VERSION ""

NS_ :

BS_:

BU_: VMCU TECU OBDScanT2 IC3 EMS ECUspare2 ECUspare1 DACU CIOM BBM

BO_ 2482973248 CIOM_BB2_05P: 8 CIOM
 SG_ FPBRChangeReq_ISig_4 : 52|2@1+ (1,0) [0|0] ""  VMCU
 SG_ HeadLampUpDown_SwitchStatus : 32|3@1+ (1,0) [0|0] ""  VMCU
 SG_ Recirc_ButtonStatus_ISig_4 : 18|2@1+ (1,0) [0|0] ""  IC3
 SG_ Auto_ButtonStatus_ISig_4 : 14|2@1+ (1,0) [0|0] ""  IC3
 SG_ AirFlowSelectionFrontBtn_stat_IS : 35|2@1+ (1,0) [0|0] ""  IC3
 SG_ InteriorLightMode_rqst_IL_Mode : 48|3@1+ (1,0) [0|0] ""  VMCU
 SG_ InteriorLightMode_rqst_EventFlag : 51|1@1+ (1,0) [0|0] ""  VMCU
 SG_ BlackOutConvoyModeSwitchStatus : 24|3@1+ (1,0) [0|0] ""  VMCU
 SG_ Indicator_Lights_Alarm_rqst_ISig : 27|3@1+ (1,0) [0|0] ""  VMCU
 SG_ AirFlowSelectionDownBtn_stat_ISi : 16|2@1+ (1,0) [0|0] ""  IC3
 SG_ ParkingHeater_IndicationCmd_ISig : 39|1@1+ (1,0) [0|0] ""  BBM
 SG_ AirFlowSelectionUpBtn_stat_ISig_ : 10|2@1+ (1,0) [0|0] ""  IC3
 SG_ ApproachLight_HMI_rqst : 44|2@1+ (1,0) [0|0] ""  VMCU
 SG_ Temperature_FreeWheelStatus_ISig : 20|4@1+ (1,0) [0|0] ""  IC3
 SG_ AirBlowerSpeed_FreeWheelStatus_I : 40|4@1+ (1,0) [0|0] ""  IC3
 SG_ CabInteriorTempVentilated_Stat_I : 0|10@1+ (0.125,-40) [-40|87.875] "DegreeC"  BBM
 SG_ ParkHeaterCooler_ButtonStatus_IS : 12|2@1+ (1,0) [0|0] ""  IC3
 SG_ WindscreenDefrost_ButtonStatus_I : 46|2@1+ (1,0) [0|0] ""  IC3
 SG_ AC_ButtonStatus_ISig_4 : 37|2@1+ (1,0) [0|0] ""  IC3

BO_ 2365532224 CIOM_BB2_04P: 8 CIOM
 SG_ BBContainerUnlockRequest : 50|2@1+ (1,0) [0|0] ""  VMCU
 SG_ CabPlowLight_rqst : 61|2@1+ (1,0) [0|0] ""  BBM
 SG_ AC_CompressorClutchCmd_ISig_4 : 58|2@1+ (1,0) [0|0] ""  EMS,VMCU
 SG_ AuxSwitchBbLoad4_Request : 44|2@1+ (1,0) [0|0] ""  VMCU
 SG_ FogLightRear_ButtonStatus_1 : 18|2@1+ (1,0) [0|0] ""  VMCU
 SG_ CabRoofSignOrVegaLight_rqst : 0|2@1+ (1,0) [0|0] ""  VMCU
 SG_ FogLightFront_ButtonStatus_2 : 4|2@1+ (1,0) [0|0] ""  VMCU
 SG_ AuxSwitchBbLoad1_Request : 30|2@1+ (1,0) [0|0] ""  VMCU
 SG_ BBCraneRequest : 52|2@1+ (1,0) [0|0] ""  VMCU
 SG_ AuxSwitchBbLoad6_Request : 48|2@1+ (1,0) [0|0] ""  VMCU
 SG_ AuxSwitchBbLoad5_Request : 46|2@1+ (1,0) [0|0] ""  VMCU
 SG_ BodyOrCabWorkingLight_rqst : 20|2@1+ (1,0) [0|0] ""  VMCU,BBM
 SG_ CabFrontSpot_rqst : 6|2@1+ (1,0) [0|0] ""  VMCU
 SG_ CabTrailerBodyLighting_rqst : 10|2@1+ (1,0) [0|0] ""  VMCU
 SG_ CabWorkingLightChassis_rqst : 2|2@1+ (1,0) [0|0] ""  VMCU
 SG_ BBTailLiftRequest : 56|2@1+ (1,0) [0|0] ""  VMCU
 SG_ BBSlidable5thWheelRequest : 54|2@1+ (1,0) [0|0] ""  VMCU
 SG_ ACmode_IndicationCmd_ISig_4 : 60|1@1+ (1,0) [0|0] ""  VMCU
 SG_ CabExtraSideWorkingLight_rqst : 24|3@1+ (1,0) [0|0] ""  VMCU
 SG_ FogLightFront_ButtonStatus_1 : 16|2@1+ (1,0) [0|0] ""  VMCU
 SG_ AuxSwitchBbLoad2_Request : 40|2@1+ (1,0) [0|0] ""  VMCU
 SG_ DRL_ButtonStatus : 14|2@1+ (1,0) [0|0] ""  VMCU
 SG_ CabRoofSpot_rqst : 12|2@1+ (1,0) [0|0] ""  VMCU
 SG_ LightMode_Status_Ctr_2 : 32|4@1+ (1,0) [0|0] ""  VMCU
 SG_ CabBeaconLight_rqst : 8|2@1+ (1,0) [0|0] ""  VMCU
 SG_ AuxSwitchBbLoad3_Request : 42|2@1+ (1,0) [0|0] ""  VMCU
 SG_ FogLightRear_ButtonStatus_2 : 22|2@1+ (1,0) [0|0] ""  VMCU
 SG_ LightMode_Status_Ctr_1 : 36|4@1+ (1,0) [0|0] ""  VMCU
 SG_ MirrorHeat_rqst : 27|3@1+ (1,0) [0|0] ""  IC3,VMCU

BO_ 2432643136 CIOM_BB2_03P: 8 CIOM
 SG_ LevelRequest_RollRequest_ISig_4 : 6|3@1+ (1,0) [0|0] ""  VMCU
 SG_ FerryFunctionSwitchChangeReq_ISi : 20|2@1+ (1,0) [0|0] ""  VMCU
 SG_ FerryFunctionRequest_ISig_4 : 34|2@1+ (1,0) [0|0] ""  VMCU
 SG_ LevelRequest_FrontAxle_ISig_4 : 0|3@1+ (1,0) [0|0] ""  VMCU
 SG_ KneelingChangeRequest_ISig_4 : 43|2@1+ (1,0) [0|0] ""  VMCU
 SG_ FerryFunctionRequest_UB_ISig_4 : 11|1@1+ (1,0) [0|0] ""  VMCU
 SG_ BunkH1AudioSrcSem_rqst_ISig_4 : 55|4@1+ (1,0) [0|0] ""  IC3
 SG_ ECSStandByRequest_ISig_4 : 40|3@1+ (1,0) [0|0] ""  VMCU
 SG_ LevelStrokeRequest_ISig_4 : 36|2@1+ (1,0) [0|0] ""  VMCU
 SG_ RideHeightStorageRequest_ISig_4 : 24|4@1+ (1,0) [0|0] ""  VMCU
 SG_ RampLevelRequest_ISig_4 : 12|4@1+ (1,0) [0|0] ""  VMCU
 SG_ TCP_KnobPostionStatus : 59|3@1+ (1,0) [0|0] ""  IC3
 SG_ SetFCWOperation : 48|3@1+ (1,0) [0|0] ""  DACU
 SG_ StopLevelChangeRequest_ISig_4 : 38|2@1+ (1,0) [0|0] ""  VMCU
 SG_ LevelRequest_sg_UB_ISig_4 : 22|1@1+ (1,0) [0|0] ""  VMCU
 SG_ RideHeightFunctionRequest_ISig_4 : 28|4@1+ (1,0) [0|0] ""  VMCU
 SG_ LevelRequest_RearAxle_ISig_4 : 3|3@1+ (1,0) [0|0] ""  VMCU
 SG_ RampLevelStorageRequest_ISig_4 : 16|4@1+ (1,0) [0|0] ""  VMCU
 SG_ SetCMOperation : 45|3@1+ (1,0) [0|0] ""  DACU,IC3,VMCU
 SG_ RideHeightFunctionRequest_UB_ISi : 23|1@1+ (1,0) [0|0] ""  VMCU
 SG_ BackToDriveReq_ISig_4 : 9|2@1+ (1,0) [0|0] ""  VMCU

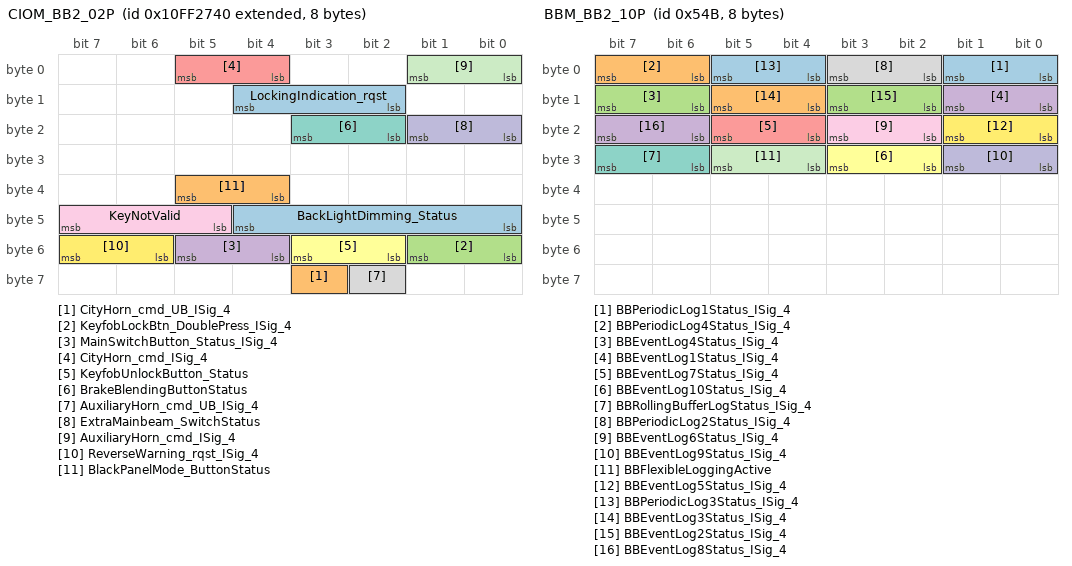
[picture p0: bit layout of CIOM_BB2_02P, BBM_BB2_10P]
BO_ 2432640832 CIOM_BB2_02P: 8 CIOM
 SG_ LockingIndication_rqst : 10|3@1+ (1,0) [0|0] ""  VMCU
 SG_ CityHorn_cmd_UB_ISig_4 : 59|1@1+ (1,0) [0|0] ""  BBM,VMCU
 SG_ KeyfobLockBtn_DoublePress_ISig_4 : 48|2@1+ (1,0) [0|0] ""  VMCU
 SG_ MainSwitchButton_Status_ISig_4 : 52|2@1+ (1,0) [0|0] ""  VMCU
 SG_ CityHorn_cmd_ISig_4 : 4|2@1+ (1,0) [0|0] ""  VMCU,BBM
 SG_ KeyfobUnlockButton_Status : 50|2@1+ (1,0) [0|0] ""  VMCU
 SG_ BrakeBlendingButtonStatus : 18|2@1+ (1,0) [0|0] ""  VMCU
 SG_ AuxiliaryHorn_cmd_UB_ISig_4 : 58|1@1+ (1,0) [0|0] ""  BBM,VMCU
 SG_ KeyNotValid : 45|3@1+ (1,0) [0|0] ""  IC3
 SG_ ExtraMainbeam_SwitchStatus : 16|2@1+ (1,0) [0|0] ""  VMCU
 SG_ AuxiliaryHorn_cmd_ISig_4 : 0|2@1+ (1,0) [0|0] ""  BBM,VMCU
 SG_ ReverseWarning_rqst_ISig_4 : 54|2@1+ (1,0) [0|0] ""  VMCU
 SG_ BackLightDimming_Status : 40|5@1+ (1,0) [0|0] ""  IC3
 SG_ BlackPanelMode_ButtonStatus : 36|2@1+ (1,0) [0|0] ""  IC3

BO_ 2432661312 CIOM_BB2_01P: 8 CIOM
 SG_ LiftAxle1LiftPositionRequest_UB_ : 3|1@1+ (1,0) [0|0] ""  VMCU
 SG_ VIN_rqst_ISig_4 : 36|1@1+ (1,0) [0|0] ""  EMS,TECU,IC3,VMCU
 SG_ FWSelectedSpeedControlMode : 24|3@1+ (1,0) [0|0] ""  IC3
 SG_ FogLightFront_ButtonStatus_3 : 42|2@1+ (1,0) [0|0] ""  VMCU
 SG_ InteriorLightDimming_rqst : 27|5@1+ (1,0) [0|0] ""  VMCU,IC3
 SG_ FrAxleDiffLockActvnDriverRqst_IS : 17|2@1+ (1,0) [0|0] ""  VMCU
 SG_ AdjustFrontBeamInclination : 32|3@1+ (1,0) [0|0] ""  VMCU
 SG_ LiftAxle2LiftPositionRequest_UB_ : 7|1@1+ (1,0) [0|0] ""  VMCU
 SG_ LiftAxle2AutoLiftRequest_ISig_4 : 11|2@1+ (1,0) [0|0] ""  VMCU
 SG_ LiftAxle2AutoLiftRequest_UB_ISig : 13|1@1+ (1,0) [0|0] ""  VMCU
 SG_ AltLoadDistribution_rqst_ISig_4 : 20|3@1+ (1,0) [0|0] ""  VMCU
 SG_ FogLightRear_ButtonStatus_3 : 44|2@1+ (1,0) [0|0] ""  VMCU
 SG_ LoadDistributionChangeRequest_UB : 16|1@1+ (1,0) [0|0] ""  VMCU
 SG_ LiftAxle2LiftPositionRequest_ISi : 4|3@1+ (1,0) [0|0] ""  VMCU
 SG_ AltLoadDistribution_rqst_UB_ISig : 23|1@1+ (1,0) [0|0] ""  VMCU
 SG_ TrailerBodyLamp_rqst : 49|2@1+ (1,0) [0|0] ""  VMCU
 SG_ LiftAxle1AutoLiftRequest_UB_ISig : 10|1@1+ (1,0) [0|0] ""  VMCU
 SG_ LoadDistributionChangeRequest_IS : 14|2@1+ (1,0) [0|0] ""  VMCU
 SG_ LiftAxle1AutoLiftRequest_ISig_4 : 8|2@1+ (1,0) [0|0] ""  VMCU
 SG_ LiftAxle1LiftPositionRequest_ISi : 0|3@1+ (1,0) [0|0] ""  VMCU
 SG_ FrAxleDiffLockActvnDriverRqst_UB : 19|1@1+ (1,0) [0|0] ""  VMCU,IC3

BO_ 1355 BBM_BB2_10P: 8 BBM
 SG_ BBPeriodicLog1Status_ISig_4 : 0|2@1+ (1,0) [0|0] ""  IC3
 SG_ BBPeriodicLog4Status_ISig_4 : 6|2@1+ (1,0) [0|0] ""  IC3
 SG_ BBEventLog4Status_ISig_4 : 14|2@1+ (1,0) [0|0] ""  IC3
 SG_ BBEventLog1Status_ISig_4 : 8|2@1+ (1,0) [0|0] ""  IC3
 SG_ BBEventLog7Status_ISig_4 : 20|2@1+ (1,0) [0|0] ""  IC3
 SG_ BBEventLog10Status_ISig_4 : 26|2@1+ (1,0) [0|0] ""  IC3
 SG_ BBRollingBufferLogStatus_ISig_4 : 30|2@1+ (1,0) [0|0] ""  IC3
 SG_ BBPeriodicLog2Status_ISig_4 : 2|2@1+ (1,0) [0|0] ""  IC3
 SG_ BBEventLog6Status_ISig_4 : 18|2@1+ (1,0) [0|0] ""  IC3
 SG_ BBEventLog9Status_ISig_4 : 24|2@1+ (1,0) [0|0] ""  IC3
 SG_ BBFlexibleLoggingActive : 28|2@1+ (1,0) [0|0] ""  IC3
 SG_ BBEventLog5Status_ISig_4 : 16|2@1+ (1,0) [0|0] ""  IC3
 SG_ BBPeriodicLog3Status_ISig_4 : 4|2@1+ (1,0) [0|0] ""  IC3
 SG_ BBEventLog3Status_ISig_4 : 12|2@1+ (1,0) [0|0] ""  IC3
 SG_ BBEventLog2Status_ISig_4 : 10|2@1+ (1,0) [0|0] ""  IC3
 SG_ BBEventLog8Status_ISig_4 : 22|2@1+ (1,0) [0|0] ""  IC3

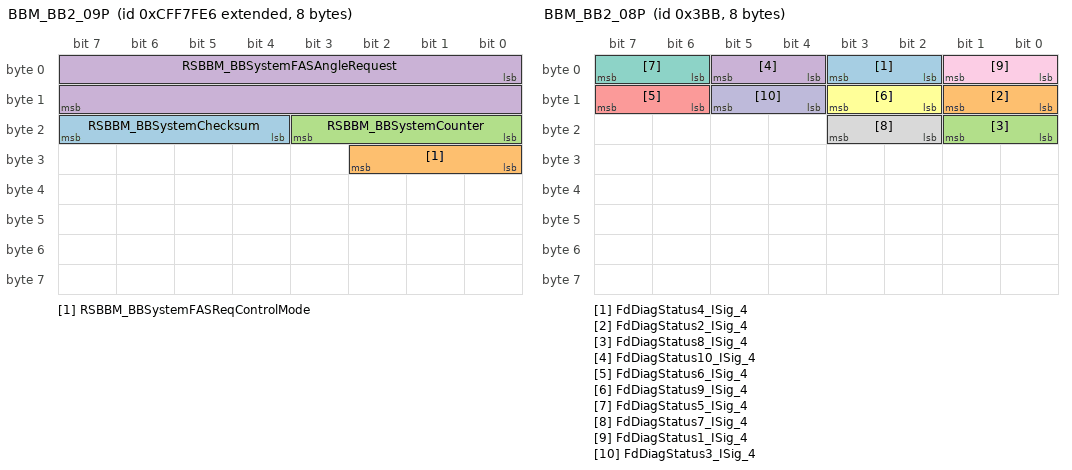
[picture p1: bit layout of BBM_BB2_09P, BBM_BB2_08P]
BO_ 2365554662 BBM_BB2_09P: 8 BBM
 SG_ RSBBM_BBSystemChecksum : 20|4@1+ (1,0) [0|15] "Count"  DACU
 SG_ RSBBM_BBSystemFASReqControlMode : 24|3@1+ (1,0) [0|0] ""  DACU
 SG_ RSBBM_BBSystemCounter : 16|4@1+ (1,0) [0|15] "Count"  DACU
 SG_ RSBBM_BBSystemFASAngleRequest : 0|16@1+ (5E-005,-1.6) [-1.6|1.67675] "rad"  DACU

BO_ 955 BBM_BB2_08P: 8 BBM
 SG_ FdDiagStatus4_ISig_4 : 2|2@1+ (1,0) [0|0] ""  IC3
 SG_ FdDiagStatus2_ISig_4 : 8|2@1+ (1,0) [0|0] ""  IC3
 SG_ FdDiagStatus8_ISig_4 : 16|2@1+ (1,0) [0|0] ""  IC3
 SG_ FdDiagStatus10_ISig_4 : 4|2@1+ (1,0) [0|0] ""  IC3
 SG_ FdDiagStatus6_ISig_4 : 14|2@1+ (1,0) [0|0] ""  IC3
 SG_ FdDiagStatus9_ISig_4 : 10|2@1+ (1,0) [0|0] ""  IC3
 SG_ FdDiagStatus5_ISig_4 : 6|2@1+ (1,0) [0|0] ""  IC3
 SG_ FdDiagStatus7_ISig_4 : 18|2@1+ (1,0) [0|0] ""  IC3
 SG_ FdDiagStatus1_ISig_4 : 0|2@1+ (1,0) [0|0] ""  IC3
 SG_ FdDiagStatus3_ISig_4 : 12|2@1+ (1,0) [0|0] ""  IC3

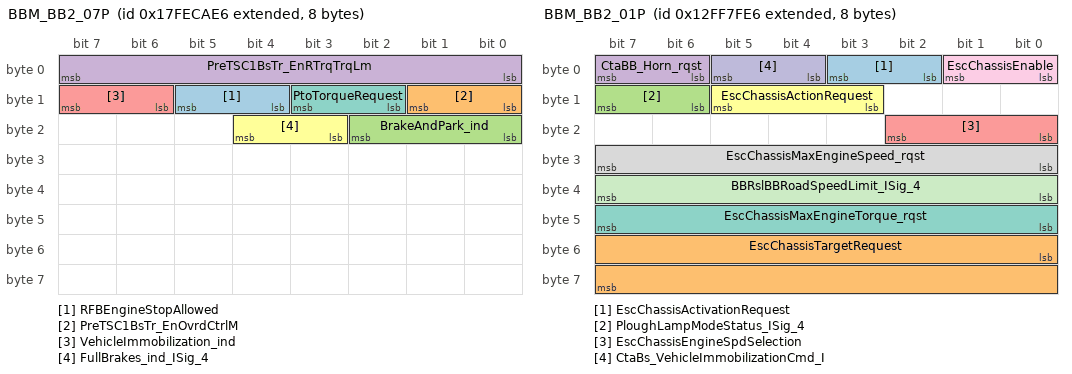
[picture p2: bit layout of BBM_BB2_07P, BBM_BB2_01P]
BO_ 2550057702 BBM_BB2_07P: 8 BBM
 SG_ RFBEngineStopAllowed : 12|2@1+ (1,0) [0|0] ""  VMCU
 SG_ PreTSC1BsTr_EnOvrdCtrlM : 8|2@1+ (1,0) [0|0] ""  VMCU
 SG_ BrakeAndPark_ind : 16|3@1+ (1,0) [0|0] ""  VMCU
 SG_ PreTSC1BsTr_EnRTrqTrqLm : 0|8@1+ (1,-125) [-125|130] "Percent"  VMCU
 SG_ VehicleImmobilization_ind : 14|2@1+ (1,0) [0|0] ""  VMCU
 SG_ FullBrakes_ind_ISig_4 : 19|2@1+ (1,0) [0|0] ""  IC3
 SG_ PtoTorqueRequest : 10|2@1+ (1,0) [0|0] ""  VMCU

BO_ 2481984998 BBM_BB2_06P: 8 BBM
 SG_ TipperConditionsStatus_ISig_4 : 14|2@1+ (1,0) [0|0] ""  CIOM
 SG_ TailLiftRemoteNotAllowed_ISig_4 : 30|2@1+ (1,0) [0|0] ""  CIOM
 SG_ TipperTarpaulinStatus_ISig_4 : 19|3@1+ (1,0) [0|0] ""  CIOM
 SG_ CTA_PBReleaseInhibit_rqst_UB : 39|1@1+ (1,0) [0|0] ""  VMCU
 SG_ TipperAutoLowering : 32|2@1+ (1,0) [0|0] ""  IC3
 SG_ DirInd_Plough_Status : 36|3@1+ (1,0) [0|0] ""  VMCU
 SG_ TipperShakerStatus_ISig_4 : 22|2@1+ (1,0) [0|0] ""  CIOM
 SG_ TipperEmergencyStopStatus_ISig_4 : 45|3@1+ (1,0) [0|0] ""  CIOM
 SG_ TipperSecondaryBodyStatus_ISig_4 : 51|3@1+ (1,0) [0|0] ""  CIOM
 SG_ TipperPrimaryBodyStatus_ISig_4 : 48|3@1+ (1,0) [0|0] ""  CIOM
 SG_ AuxSwitchBbLoad5Feedback : 8|3@1+ (1,0) [0|0] ""  VMCU
 SG_ AuxSwitchBbLoad3Feedback : 0|3@1+ (1,0) [0|0] ""  VMCU
 SG_ TailLiftMotionStatus_ISig_4 : 27|3@1+ (1,0) [0|0] ""  CIOM
 SG_ AuxSwitchBbLoad4Feedback : 3|3@1+ (1,0) [0|0] ""  VMCU
 SG_ TipperUpDownStatus_ISig_4 : 24|3@1+ (1,0) [0|0] ""  CIOM
 SG_ TailLiftConditionsStatus_ISig_4 : 6|2@1+ (1,0) [0|0] ""  CIOM
 SG_ AuxSwitchBbLoad6Feedback : 11|3@1+ (1,0) [0|0] ""  VMCU
 SG_ TipperTailGateStatus_ISig_4 : 16|3@1+ (1,0) [0|0] ""  CIOM
 SG_ CTA_PBReleaseInhibit_rqst : 43|2@1+ (1,0) [0|0] ""  VMCU

BO_ 2466201830 BBM_BB2_05P: 8 BBM
 SG_ BBUSecondDriverInterfEnable_UB_I : 29|1@1+ (1,0) [0|0] ""  VMCU
 SG_ CtaGcReverseInhibit : 6|2@1+ (1,0) [0|0] ""  TECU
 SG_ BBSystemAlternatLoadDistribReq_U : 28|1@1+ (1,0) [0|0] ""  VMCU
 SG_ BBSystemProhibitControlRequest_I : 4|2@1+ (1,0) [0|0] ""  VMCU
 SG_ BBUSecondDriverInterfEnable_ISig : 30|2@1+ (1,0) [0|0] ""  VMCU
 SG_ SecondDriverInterfEnableInput : 2|2@1+ (1,0) [0|0] ""  VMCU
 SG_ XPRRequest_RBS_ISig_4 : 40|8@1+ (1,0) [0|255] "NotApplicable"  VMCU
 SG_ CtaGcInhibitGearEngaged : 14|2@1+ (1,0) [0|0] ""  TECU
 SG_ EscChassisEngineSpdMode4 : 54|2@1+ (1,0) [0|0] ""  VMCU
 SG_ SecondAcceleratorPedalPosition : 32|8@1+ (0.4,0) [0|102] "Percent"  VMCU
 SG_ SecondaryAccelPedalQuality : 56|2@1+ (1,0) [0|0] ""  VMCU
 SG_ BBSystemKneelRequest_ISig_4 : 24|2@1+ (1,0) [0|0] ""  VMCU
 SG_ BBSystemAlternatLoadDistribReq_I : 0|2@1+ (1,0) [0|0] ""  VMCU
 SG_ EscChassisEngineSpdMode3 : 52|2@1+ (1,0) [0|0] ""  VMCU
 SG_ CtaGcSecondGearLeverPosition_ISi : 18|3@1+ (1,0) [0|0] ""  VMCU
 SG_ CtaGcAlternativeGearStarter : 16|2@1+ (1,0) [0|0] ""  TECU
 SG_ EscChassisEngineSpdMode2 : 50|2@1+ (1,0) [0|0] ""  VMCU
 SG_ SecondaryAccelPedalKickDown : 26|2@1+ (1,0) [0|0] ""  VMCU
 SG_ SecondAcceleratorPedalStatus : 10|2@1+ (1,0) [0|0] ""  VMCU
 SG_ GCRemoteEsc_rqst : 8|2@1+ (1,0) [0|0] ""  VMCU
 SG_ EscChassisEngineSpdMode1 : 48|2@1+ (1,0) [0|0] ""  VMCU
 SG_ BBSystemSpeedDepDriveLevelReq_IS : 12|2@1+ (1,0) [0|0] ""  VMCU

BO_ 2549377255 BBM_BB2_03S_HMIIOM_FCM: 8 IC3
 SG_ BBM_BB2_03S_FCS_4ea : 0|64@1+ (1,0) [0|1] ""  BBM

BO_ 2549377254 BBM_BB2_03S_HMIIOM: 128 BBM
 SG_ FdEquipmentFreeText_ISig_4_4e7 : 0|1024@1+ (1,0) [0|0] ""  IC3

BO_ 2549377511 BBM_BB2_03S_CIOM_FCM: 8 CIOM
 SG_ BBM_BB2_03S_FCS_4f0 : 0|64@1+ (1,0) [0|1] ""  BBM

BO_ 2549377510 BBM_BB2_03S_CIOM: 128 BBM
 SG_ FdEquipmentFreeText_ISig_4_4ed : 0|1024@1+ (1,0) [0|0] ""  CIOM

BO_ 2466239718 BBM_BB2_02P: 8 BBM
 SG_ RssRemoteStopEngine_rqst : 52|2@1+ (1,0) [0|0] ""  IC3,VMCU
 SG_ RSL2requestStatus : 56|2@1+ (1,0) [0|0] ""  VMCU
 SG_ FdEquipmentStatus2_ISig_4 : 6|2@1+ (1,0) [0|0] ""  IC3,CIOM
 SG_ RssRemoteStartEngine_rqst : 54|2@1+ (1,0) [0|0] ""  VMCU
 SG_ BBNetwBeaconLight_stat : 20|2@1+ (1,0) [0|0] ""  CIOM
 SG_ Pto2RemoteRequest : 18|2@1+ (1,0) [0|0] ""  VMCU
 SG_ FdEquipmentValue1_ISig_4 : 32|8@1+ (0.5,0) [0|127.5] "Percent"  CIOM,IC3
 SG_ Pto1RemoteRequest : 10|2@1+ (1,0) [0|0] ""  VMCU
 SG_ Pto3RemoteRequest : 16|2@1+ (1,0) [0|0] ""  VMCU
 SG_ FdEquipmentValue2_ISig_4 : 40|8@1+ (0.5,0) [0|127.5] "Percent"  IC3,CIOM
 SG_ BBHazardWarning_rqst : 0|2@1+ (1,0) [0|0] ""  VMCU
 SG_ FdEquipmentStatus5_ISig_4 : 4|2@1+ (1,0) [0|0] ""  CIOM,IC3
 SG_ RssInhibitStartEngFromBB_rqst : 58|2@1+ (1,0) [0|0] ""  VMCU
 SG_ BBNetwExtraSWrknLight_stat : 60|3@1+ (1,0) [0|0] ""  CIOM
 SG_ FdEquipmentStatus4_ISig_4 : 12|2@1+ (1,0) [0|0] ""  IC3,CIOM
 SG_ FdEquipmentStatus3_ISig_4 : 14|2@1+ (1,0) [0|0] ""  CIOM,IC3
 SG_ BBNetwWrknLightChassis_stat : 50|2@1+ (1,0) [0|0] ""  CIOM
 SG_ BBNetwBodyOrCabWrknLight_stat : 22|2@1+ (1,0) [0|0] ""  CIOM
 SG_ BBNetwTrailerBodyLighting_rqst : 48|2@1+ (1,0) [0|0] ""  CIOM
 SG_ Pto4RemoteRequest : 2|2@1+ (1,0) [0|0] ""  VMCU
 SG_ Pto3FeedbackStatus : 8|2@1+ (1,0) [0|0] ""  VMCU
 SG_ FdEquipmentValue3_ISig_4 : 24|8@1+ (0.5,0) [0|127.5] "Percent"  IC3,CIOM

BO_ 2466217958 BBM_BB2_01P: 8 BBM
 SG_ EscChassisActivationRequest : 2|2@1+ (1,0) [0|0] ""  VMCU
 SG_ EscChassisTargetRequest : 48|16@1+ (0.125,0) [0|8191.875] "rpm"  VMCU
 SG_ PloughLampModeStatus_ISig_4 : 14|2@1+ (1,0) [0|0] ""  CIOM,VMCU,IC3,DACU
 SG_ CtaBB_Horn_rqst : 6|2@1+ (1,0) [0|0] ""  CIOM
 SG_ EscChassisEngineSpdSelection : 16|3@1+ (1,0) [0|0] ""  VMCU
 SG_ EscChassisActionRequest : 11|3@1+ (1,0) [0|0] ""  VMCU
 SG_ EscChassisMaxEngineTorque_rqst : 40|8@1+ (1,-125) [-125|130] "Percent"  VMCU
 SG_ EscChassisMaxEngineSpeed_rqst : 24|8@1+ (10,500) [500|3050] "rpm"  VMCU
 SG_ EscChassisEnable : 0|2@1+ (1,0) [0|0] ""  VMCU
 SG_ CtaBs_VehicleImmobilizationCmd_I : 4|2@1+ (1,0) [0|0] ""  IC3
 SG_ BBRslBBRoadSpeedLimit_ISig_4 : 32|8@1+ (1,0) [0|255] "Km_per_h"  VMCU

BO_ 2633994247 AnmMsg_VMCU_Backbone2: 4 VMCU
 SG_ AnmSig_VMCU_Backbone2 : 0|32@1+ (1,0) [0|4294967295] ""  IC3,DACU,BBM,ECUspare2,EMS,CIOM,TECU,ECUspare1

BO_ 2633994246 AnmMsg_TECU_Backbone2: 4 TECU
 SG_ AnmSig_TECU_Backbone2 : 0|32@1+ (1,0) [0|4294967295] ""  VMCU,ECUspare2,IC3,ECUspare1,DACU,EMS,CIOM,BBM

BO_ 1715 AnmMsg_IC3_Backbone2: 4 IC3
 SG_ AnmSig_IC3_Backbone2 : 0|32@1+ (1,0) [0|4294967295] ""  ECUspare1,BBM,DACU,VMCU,TECU,EMS,CIOM,ECUspare2

BO_ 2633994243 AnmMsg_EMS_Backbone2: 4 EMS
 SG_ AnmSig_EMS_Backbone2 : 0|32@1+ (1,0) [0|4294967295] ""  ECUspare1,TECU,BBM,ECUspare2,CIOM,VMCU,DACU,IC3

BO_ 2633994310 AnmMsg_ECUspare2_Backbone2: 4 ECUspare2
 SG_ AnmSig_ECUspare2_Backbone2 : 0|32@1+ (1,0) [0|4294967295] ""  IC3,BBM,ECUspare1,CIOM,EMS,DACU,TECU,VMCU

BO_ 2633994309 AnmMsg_ECUspare1_Backbone2: 4 ECUspare1
 SG_ AnmSig_ECUspare1_Backbone2 : 0|32@1+ (1,0) [0|4294967295] ""  EMS,CIOM,TECU,VMCU,BBM,IC3,ECUspare2,DACU

BO_ 2633994242 AnmMsg_DACU_Backbone2: 4 DACU
 SG_ AnmSig_DACU_Backbone2 : 0|32@1+ (1,0) [0|4294967295] ""  ECUspare1,EMS,IC3,ECUspare2,CIOM,BBM,TECU,VMCU

BO_ 2633994241 AnmMsg_CIOM_Backbone2: 4 CIOM
 SG_ AnmSig_CIOM_Backbone2 : 0|32@1+ (1,0) [0|4294967295] ""  IC3,ECUspare1,VMCU,DACU,EMS,TECU,BBM,ECUspare2

BO_ 2633994240 AnmMsg_BBM_Backbone2: 4 BBM
 SG_ AnmSig_BBM_Backbone2 : 0|32@1+ (1,0) [0|4294967295] ""  EMS,VMCU,ECUspare2,DACU,CIOM,ECUspare1,TECU,IC3

CM_ SG_ 2482973248 CabInteriorTempVentilated_Stat_I "1022 Error; 1023 Not Available";
CM_ SG_ 2466201830 SecondAcceleratorPedalPosition "254 Error ; 255 Not available";
CM_ SG_ 2466239718 FdEquipmentValue1_ISig_4 "254 Error ; 255 Not available";
CM_ SG_ 2466239718 FdEquipmentValue2_ISig_4 "254 Error ; 255 Not available";
CM_ SG_ 2466239718 FdEquipmentValue3_ISig_4 "254 Error ; 255 Not available";
CM_ SG_ 2466217958 EscChassisTargetRequest "65024 - 65279 Error ; 65280 - 65535 Not available";
CM_ SG_ 2466217958 EscChassisMaxEngineTorque_rqst "254 Error ; 255 Not available";
CM_ SG_ 2466217958 EscChassisMaxEngineSpeed_rqst "254 Error ; 255 Not available";
CM_ SG_ 2466217958 BBRslBBRoadSpeedLimit_ISig_4 "254 Error ; 255 Not available";
BA_DEF_ BO_  "GenMsgStartDelayTime" INT 0 0;
BA_DEF_ BO_  "GenMsgDelayTime" INT 0 0;
BA_DEF_ BO_  "GenMsgCycleTime" INT 0 0;
BA_DEF_ BO_  "GenMsgSendType" ENUM  "Cyclic","NotUsed","NotUsed","NotUsed","NotUsed","NotUsed","NotUsed","IfActive","NoMsgSendType","NotUsed";
BA_DEF_ SG_  "GenSigStartValue" INT 0 0;
BA_DEF_ SG_  "GenSigCycleTimeActive" INT 0 0;
BA_DEF_ SG_  "GenSigCycleTime" INT 0 0;
BA_DEF_ SG_  "GenSigSendType" ENUM  "Cyclic","OnWrite","OnWriteWithRepetition","OnChange","OnChangeWithRepetition","IfActive","IfActiveWithRepetition","NoSigSendType","NotUsed","NotUsed","NotUsed","NotUsed","NotUsed";
BA_DEF_ BO_  "VFrameFormat" ENUM  "StandardCAN","ExtendedCAN","reserved","J1939PG";
BA_DEF_ SG_  "SigType" ENUM  "Default","Range","RangeSigned","ASCII","Discrete","Control","ReferencePGN","DTC","StringDelimiter","StringLength","StringLengthControl";
BA_DEF_ SG_  "SeToolVersion_SIGNAL" STRING ;
BA_DEF_ SG_  "SeToolUniqueID_SIGNAL" STRING ;
BA_DEF_ SG_  "SeToolOwnerSigGroup_SIGNAL" STRING ;
BA_DEF_ SG_  "SeToolOwnerSigGroupID_SIGNAL" STRING ;
BA_DEF_ SG_  "SeToolName_SIGNAL" STRING ;
BA_DEF_ SG_  "SeToolItemID_SIGNAL" STRING ;
BA_DEF_ SG_  "SeToolAncestorID_SIGNAL" STRING ;
BA_DEF_ SG_  "Platform_VMCU1_Sig" ENUM  "No","Yes";
BA_DEF_ BO_  "NmAsrMessage" ENUM  "No","Yes";
BA_DEF_ SG_  "NeedsUpdateBit" ENUM  "No","Yes";
BA_DEF_ SG_  "MmAnSignal" ENUM  "No","Yes";
BA_DEF_ SG_  "GenSigMaxLatency" INT 0 65535;
BA_DEF_ SG_  "GenSigILSupport" ENUM  "Yes","No";
BA_DEF_ BO_  "GenMsgRequestable" INT 0 1;
BA_DEF_ BO_  "GenMsgILSupport" ENUM  "No","Yes";
BA_DEF_ BO_  "DiagUUDTResponse" ENUM  "No","Yes";
BA_DEF_ BO_  "DiagState" ENUM  "No","Yes";
BA_DEF_ BO_  "DiagResponse" ENUM  "No","Yes";
BA_DEF_ BO_  "DiagRequest" ENUM  "No","Yes";
BA_DEF_ BO_  "DiagConnection" HEX 0 65535;
BA_DEF_ BO_  "CanTpSTmin" INT 0 255;
BA_DEF_ BO_  "CanTpFcFrameId" HEX 0 2147483647;
BA_DEF_ BO_  "CanTpBs" INT 0 255;
BA_DEF_ SG_  "SystemSignalLongSymbol" STRING ;
BA_DEF_REL_ BU_SG_REL_  "GenSigTimeoutTime" INT 0 65535;
BA_DEF_REL_ BU_SG_REL_  "GenSigFirstTimeoutTime" INT 0 65535;
BA_DEF_DEF_  "GenMsgStartDelayTime" 0;
BA_DEF_DEF_  "GenMsgDelayTime" 0;
BA_DEF_DEF_  "GenMsgCycleTime" 0;
BA_DEF_DEF_  "GenMsgSendType" "Cyclic";
BA_DEF_DEF_  "GenSigStartValue" 0;
BA_DEF_DEF_  "GenSigCycleTimeActive" 0;
BA_DEF_DEF_  "GenSigCycleTime" 0;
BA_DEF_DEF_  "GenSigSendType" "Cyclic";
BA_DEF_DEF_  "VFrameFormat" "ExtendedCAN";
BA_DEF_DEF_  "SigType" "Default";
BA_DEF_DEF_  "SeToolVersion_SIGNAL" "";
BA_DEF_DEF_  "SeToolUniqueID_SIGNAL" "";
BA_DEF_DEF_  "SeToolOwnerSigGroup_SIGNAL" "";
BA_DEF_DEF_  "SeToolOwnerSigGroupID_SIGNAL" "";
BA_DEF_DEF_  "SeToolName_SIGNAL" "";
BA_DEF_DEF_  "SeToolItemID_SIGNAL" "";
BA_DEF_DEF_  "SeToolAncestorID_SIGNAL" "";
BA_DEF_DEF_  "Platform_VMCU1_Sig" "No";
BA_DEF_DEF_  "NmAsrMessage" "No";
BA_DEF_DEF_  "NeedsUpdateBit" "No";
BA_DEF_DEF_  "MmAnSignal" "No";
BA_DEF_DEF_  "GenSigMaxLatency" 0;
BA_DEF_DEF_  "GenSigILSupport" "Yes";
BA_DEF_DEF_  "GenMsgRequestable" 1;
BA_DEF_DEF_  "GenMsgILSupport" "Yes";
BA_DEF_DEF_  "DiagUUDTResponse" "No";
BA_DEF_DEF_  "DiagState" "No";
BA_DEF_DEF_  "DiagResponse" "No";
BA_DEF_DEF_  "DiagRequest" "No";
BA_DEF_DEF_  "DiagConnection" 0;
BA_DEF_DEF_  "CanTpSTmin" 0;
BA_DEF_DEF_  "CanTpFcFrameId" 2147483647;
BA_DEF_DEF_  "CanTpBs" 255;
BA_DEF_DEF_REL_ "GenSigTimeoutTime" 0;
BA_DEF_DEF_REL_ "GenSigFirstTimeoutTime" 0;
BA_DEF_DEF_  "SystemSignalLongSymbol" "";
BA_ "GenMsgCycleTime" BO_ 2482973248 50;
BA_ "GenMsgStartDelayTime" BO_ 2482973248 20;
BA_ "GenMsgCycleTime" BO_ 2365532224 15;
BA_ "GenMsgCycleTime" BO_ 2432643136 20;
BA_ "GenMsgStartDelayTime" BO_ 2432643136 5;
BA_ "GenMsgCycleTime" BO_ 2432640832 20;
BA_ "GenMsgStartDelayTime" BO_ 2432640832 10;
BA_ "GenMsgCycleTime" BO_ 2432661312 20;
BA_ "VFrameFormat" BO_ 1355 0;
BA_ "GenMsgCycleTime" BO_ 1355 1000;
BA_ "GenMsgCycleTime" BO_ 2365554662 20;
BA_ "GenMsgStartDelayTime" BO_ 2365554662 10;
BA_ "VFrameFormat" BO_ 955 0;
BA_ "GenMsgCycleTime" BO_ 955 45;
BA_ "GenMsgStartDelayTime" BO_ 955 20;
BA_ "GenMsgCycleTime" BO_ 2550057702 250;
BA_ "GenMsgStartDelayTime" BO_ 2550057702 130;
BA_ "GenMsgCycleTime" BO_ 2481984998 50;
BA_ "GenMsgStartDelayTime" BO_ 2481984998 25;
BA_ "GenMsgCycleTime" BO_ 2466201830 30;
BA_ "GenMsgStartDelayTime" BO_ 2466201830 5;
BA_ "GenMsgILSupport" BO_ 2549377255 0;
BA_ "GenMsgSendType" BO_ 2549377255 8;
BA_ "CanTpFcFrameId" BO_ 2549377254 1258;
BA_ "GenMsgSendType" BO_ 2549377254 8;
BA_ "GenMsgDelayTime" BO_ 2549377254 90;
BA_ "GenMsgStartDelayTime" BO_ 2549377254 50;
BA_ "GenMsgILSupport" BO_ 2549377511 0;
BA_ "GenMsgSendType" BO_ 2549377511 8;
BA_ "CanTpFcFrameId" BO_ 2549377510 1264;
BA_ "GenMsgSendType" BO_ 2549377510 8;
BA_ "GenMsgDelayTime" BO_ 2549377510 90;
BA_ "GenMsgStartDelayTime" BO_ 2549377510 50;
BA_ "GenMsgCycleTime" BO_ 2466239718 45;
BA_ "GenMsgStartDelayTime" BO_ 2466239718 10;
BA_ "GenMsgCycleTime" BO_ 2466217958 45;
BA_ "GenMsgStartDelayTime" BO_ 2466217958 15;
BA_ "GenMsgCycleTime" BO_ 2633994247 100;
BA_ "GenMsgCycleTime" BO_ 2633994246 100;
BA_ "VFrameFormat" BO_ 1715 0;
BA_ "GenMsgCycleTime" BO_ 1715 100;
BA_ "GenMsgCycleTime" BO_ 2633994243 100;
BA_ "GenMsgCycleTime" BO_ 2633994310 100;
BA_ "GenMsgCycleTime" BO_ 2633994309 100;
BA_ "GenMsgCycleTime" BO_ 2633994242 100;
BA_ "GenMsgCycleTime" BO_ 2633994241 100;
BA_ "GenMsgCycleTime" BO_ 2633994240 100;
BA_ "GenSigCycleTime" SG_ 2482973248 FPBRChangeReq_ISig_4 100;
BA_ "GenSigCycleTimeActive" SG_ 2482973248 FPBRChangeReq_ISig_4 100;
BA_ "GenSigStartValue" SG_ 2482973248 FPBRChangeReq_ISig_4 3;
BA_ "Platform_VMCU1_Sig" SG_ 2482973248 FPBRChangeReq_ISig_4 1;
BA_ "GenSigCycleTime" SG_ 2482973248 HeadLampUpDown_SwitchStatus 100;
BA_ "GenSigCycleTimeActive" SG_ 2482973248 HeadLampUpDown_SwitchStatus 100;
BA_ "GenSigStartValue" SG_ 2482973248 HeadLampUpDown_SwitchStatus 7;
BA_ "GenSigMaxLatency" SG_ 2482973248 HeadLampUpDown_SwitchStatus 57;
BA_ "Platform_VMCU1_Sig" SG_ 2482973248 HeadLampUpDown_SwitchStatus 1;
BA_ "GenSigCycleTime" SG_ 2482973248 Recirc_ButtonStatus_ISig_4 100;
BA_ "GenSigCycleTimeActive" SG_ 2482973248 Recirc_ButtonStatus_ISig_4 100;
BA_ "GenSigStartValue" SG_ 2482973248 Recirc_ButtonStatus_ISig_4 3;
BA_ "GenSigMaxLatency" SG_ 2482973248 Recirc_ButtonStatus_ISig_4 57;
BA_ "Platform_VMCU1_Sig" SG_ 2482973248 Recirc_ButtonStatus_ISig_4 1;
BA_ "SeToolAncestorID_SIGNAL" SG_ 2482973248 Recirc_ButtonStatus_ISig_4 "x0000001D0423D932";
BA_ "SeToolItemID_SIGNAL" SG_ 2482973248 Recirc_ButtonStatus_ISig_4 "x0000001D0429669B";
BA_ "SeToolName_SIGNAL" SG_ 2482973248 Recirc_ButtonStatus_ISig_4 "Recirc_ButtonStatus";
BA_ "SeToolVersion_SIGNAL" SG_ 2482973248 Recirc_ButtonStatus_ISig_4 "4";
BA_ "GenSigCycleTime" SG_ 2482973248 Auto_ButtonStatus_ISig_4 100;
BA_ "GenSigCycleTimeActive" SG_ 2482973248 Auto_ButtonStatus_ISig_4 100;
BA_ "GenSigStartValue" SG_ 2482973248 Auto_ButtonStatus_ISig_4 3;
BA_ "GenSigMaxLatency" SG_ 2482973248 Auto_ButtonStatus_ISig_4 57;
BA_ "Platform_VMCU1_Sig" SG_ 2482973248 Auto_ButtonStatus_ISig_4 1;
BA_ "SeToolAncestorID_SIGNAL" SG_ 2482973248 Auto_ButtonStatus_ISig_4 "x0000001D0423D932";
BA_ "SeToolItemID_SIGNAL" SG_ 2482973248 Auto_ButtonStatus_ISig_4 "x0000001D0429669B";
BA_ "SeToolName_SIGNAL" SG_ 2482973248 Auto_ButtonStatus_ISig_4 "Auto_ButtonStatus";
BA_ "SeToolVersion_SIGNAL" SG_ 2482973248 Auto_ButtonStatus_ISig_4 "4";
BA_ "GenSigCycleTime" SG_ 2482973248 AirFlowSelectionFrontBtn_stat_IS 100;
BA_ "GenSigCycleTimeActive" SG_ 2482973248 AirFlowSelectionFrontBtn_stat_IS 100;
BA_ "GenSigStartValue" SG_ 2482973248 AirFlowSelectionFrontBtn_stat_IS 3;
BA_ "GenSigMaxLatency" SG_ 2482973248 AirFlowSelectionFrontBtn_stat_IS 57;
BA_ "Platform_VMCU1_Sig" SG_ 2482973248 AirFlowSelectionFrontBtn_stat_IS 1;
BA_ "SeToolAncestorID_SIGNAL" SG_ 2482973248 AirFlowSelectionFrontBtn_stat_IS "x0000001D0423D932";
BA_ "SeToolItemID_SIGNAL" SG_ 2482973248 AirFlowSelectionFrontBtn_stat_IS "x0000001D0429669B";
BA_ "SeToolName_SIGNAL" SG_ 2482973248 AirFlowSelectionFrontBtn_stat_IS "AirFlowSelectionFront_ButtonStatus";
BA_ "SeToolVersion_SIGNAL" SG_ 2482973248 AirFlowSelectionFrontBtn_stat_IS "4";
BA_ "SystemSignalLongSymbol" SG_ 2482973248 AirFlowSelectionFrontBtn_stat_IS "AirFlowSelectionFrontBtn_stat_ISig_4";
BA_ "GenSigCycleTime" SG_ 2482973248 InteriorLightMode_rqst_IL_Mode 100;
BA_ "GenSigCycleTimeActive" SG_ 2482973248 InteriorLightMode_rqst_IL_Mode 100;
BA_ "GenSigStartValue" SG_ 2482973248 InteriorLightMode_rqst_IL_Mode 7;
BA_ "Platform_VMCU1_Sig" SG_ 2482973248 InteriorLightMode_rqst_IL_Mode 1;
BA_ "GenSigCycleTime" SG_ 2482973248 InteriorLightMode_rqst_EventFlag 100;
BA_ "GenSigCycleTimeActive" SG_ 2482973248 InteriorLightMode_rqst_EventFlag 100;
BA_ "Platform_VMCU1_Sig" SG_ 2482973248 InteriorLightMode_rqst_EventFlag 1;
BA_ "GenSigCycleTime" SG_ 2482973248 BlackOutConvoyModeSwitchStatus 100;
BA_ "GenSigCycleTimeActive" SG_ 2482973248 BlackOutConvoyModeSwitchStatus 100;
BA_ "GenSigStartValue" SG_ 2482973248 BlackOutConvoyModeSwitchStatus 7;
BA_ "GenSigMaxLatency" SG_ 2482973248 BlackOutConvoyModeSwitchStatus 57;
BA_ "Platform_VMCU1_Sig" SG_ 2482973248 BlackOutConvoyModeSwitchStatus 1;
BA_ "GenSigCycleTime" SG_ 2482973248 Indicator_Lights_Alarm_rqst_ISig 100;
BA_ "GenSigCycleTimeActive" SG_ 2482973248 Indicator_Lights_Alarm_rqst_ISig 100;
BA_ "GenSigStartValue" SG_ 2482973248 Indicator_Lights_Alarm_rqst_ISig 7;
BA_ "GenSigMaxLatency" SG_ 2482973248 Indicator_Lights_Alarm_rqst_ISig 57;
BA_ "Platform_VMCU1_Sig" SG_ 2482973248 Indicator_Lights_Alarm_rqst_ISig 1;
BA_ "SystemSignalLongSymbol" SG_ 2482973248 Indicator_Lights_Alarm_rqst_ISig "Indicator_Lights_Alarm_rqst_ISig_4";
BA_ "GenSigCycleTime" SG_ 2482973248 AirFlowSelectionDownBtn_stat_ISi 100;
BA_ "GenSigCycleTimeActive" SG_ 2482973248 AirFlowSelectionDownBtn_stat_ISi 100;
BA_ "GenSigStartValue" SG_ 2482973248 AirFlowSelectionDownBtn_stat_ISi 3;
BA_ "GenSigMaxLatency" SG_ 2482973248 AirFlowSelectionDownBtn_stat_ISi 57;
BA_ "Platform_VMCU1_Sig" SG_ 2482973248 AirFlowSelectionDownBtn_stat_ISi 1;
BA_ "SeToolAncestorID_SIGNAL" SG_ 2482973248 AirFlowSelectionDownBtn_stat_ISi "x0000001D0423D932";
BA_ "SeToolItemID_SIGNAL" SG_ 2482973248 AirFlowSelectionDownBtn_stat_ISi "x0000001D0429669B";
BA_ "SeToolName_SIGNAL" SG_ 2482973248 AirFlowSelectionDownBtn_stat_ISi "AirFlowSelectionDown_ButtonStatus";
BA_ "SeToolVersion_SIGNAL" SG_ 2482973248 AirFlowSelectionDownBtn_stat_ISi "4";
BA_ "SystemSignalLongSymbol" SG_ 2482973248 AirFlowSelectionDownBtn_stat_ISi "AirFlowSelectionDownBtn_stat_ISig_4";
BA_ "GenSigCycleTime" SG_ 2482973248 ParkingHeater_IndicationCmd_ISig 100;
BA_ "GenSigCycleTimeActive" SG_ 2482973248 ParkingHeater_IndicationCmd_ISig 100;
BA_ "GenSigMaxLatency" SG_ 2482973248 ParkingHeater_IndicationCmd_ISig 57;
BA_ "Platform_VMCU1_Sig" SG_ 2482973248 ParkingHeater_IndicationCmd_ISig 1;
BA_ "SystemSignalLongSymbol" SG_ 2482973248 ParkingHeater_IndicationCmd_ISig "ParkingHeater_IndicationCmd_ISig_4";
BA_ "GenSigCycleTime" SG_ 2482973248 AirFlowSelectionUpBtn_stat_ISig_ 100;
BA_ "GenSigCycleTimeActive" SG_ 2482973248 AirFlowSelectionUpBtn_stat_ISig_ 100;
BA_ "GenSigStartValue" SG_ 2482973248 AirFlowSelectionUpBtn_stat_ISig_ 3;
BA_ "GenSigMaxLatency" SG_ 2482973248 AirFlowSelectionUpBtn_stat_ISig_ 57;
BA_ "Platform_VMCU1_Sig" SG_ 2482973248 AirFlowSelectionUpBtn_stat_ISig_ 1;
BA_ "SeToolAncestorID_SIGNAL" SG_ 2482973248 AirFlowSelectionUpBtn_stat_ISig_ "x0000001D0423D932";
BA_ "SeToolItemID_SIGNAL" SG_ 2482973248 AirFlowSelectionUpBtn_stat_ISig_ "x0000001D0429669B";
BA_ "SeToolName_SIGNAL" SG_ 2482973248 AirFlowSelectionUpBtn_stat_ISig_ "AirFlowSelectionUp_ButtonStatus";
BA_ "SeToolVersion_SIGNAL" SG_ 2482973248 AirFlowSelectionUpBtn_stat_ISig_ "4";
BA_ "SystemSignalLongSymbol" SG_ 2482973248 AirFlowSelectionUpBtn_stat_ISig_ "AirFlowSelectionUpBtn_stat_ISig_4";
BA_ "GenSigCycleTime" SG_ 2482973248 ApproachLight_HMI_rqst 100;
BA_ "GenSigCycleTimeActive" SG_ 2482973248 ApproachLight_HMI_rqst 100;
BA_ "GenSigStartValue" SG_ 2482973248 ApproachLight_HMI_rqst 3;
BA_ "GenSigMaxLatency" SG_ 2482973248 ApproachLight_HMI_rqst 57;
BA_ "Platform_VMCU1_Sig" SG_ 2482973248 ApproachLight_HMI_rqst 1;
BA_ "GenSigCycleTime" SG_ 2482973248 Temperature_FreeWheelStatus_ISig 100;
BA_ "GenSigCycleTimeActive" SG_ 2482973248 Temperature_FreeWheelStatus_ISig 100;
BA_ "GenSigStartValue" SG_ 2482973248 Temperature_FreeWheelStatus_ISig 15;
BA_ "GenSigMaxLatency" SG_ 2482973248 Temperature_FreeWheelStatus_ISig 57;
BA_ "Platform_VMCU1_Sig" SG_ 2482973248 Temperature_FreeWheelStatus_ISig 1;
BA_ "SeToolAncestorID_SIGNAL" SG_ 2482973248 Temperature_FreeWheelStatus_ISig "x0000001D0425F9AD";
BA_ "SeToolItemID_SIGNAL" SG_ 2482973248 Temperature_FreeWheelStatus_ISig "x0000001D043FC230";
BA_ "SeToolName_SIGNAL" SG_ 2482973248 Temperature_FreeWheelStatus_ISig "Temperature_FreeWheelStatus";
BA_ "SeToolVersion_SIGNAL" SG_ 2482973248 Temperature_FreeWheelStatus_ISig "3";
BA_ "SystemSignalLongSymbol" SG_ 2482973248 Temperature_FreeWheelStatus_ISig "Temperature_FreeWheelStatus_ISig_4";
BA_ "GenSigCycleTime" SG_ 2482973248 AirBlowerSpeed_FreeWheelStatus_I 100;
BA_ "GenSigCycleTimeActive" SG_ 2482973248 AirBlowerSpeed_FreeWheelStatus_I 100;
BA_ "GenSigStartValue" SG_ 2482973248 AirBlowerSpeed_FreeWheelStatus_I 15;
BA_ "GenSigMaxLatency" SG_ 2482973248 AirBlowerSpeed_FreeWheelStatus_I 57;
BA_ "Platform_VMCU1_Sig" SG_ 2482973248 AirBlowerSpeed_FreeWheelStatus_I 1;
BA_ "SeToolAncestorID_SIGNAL" SG_ 2482973248 AirBlowerSpeed_FreeWheelStatus_I "x0000001D0425F9AD";
BA_ "SeToolItemID_SIGNAL" SG_ 2482973248 AirBlowerSpeed_FreeWheelStatus_I "x0000001D043FC230";
BA_ "SeToolName_SIGNAL" SG_ 2482973248 AirBlowerSpeed_FreeWheelStatus_I "AirBlowerSpeed_FreeWheelStatus";
BA_ "SeToolVersion_SIGNAL" SG_ 2482973248 AirBlowerSpeed_FreeWheelStatus_I "3";
BA_ "SystemSignalLongSymbol" SG_ 2482973248 AirBlowerSpeed_FreeWheelStatus_I "AirBlowerSpeed_FreeWheelStatus_ISig_4";
BA_ "GenSigCycleTime" SG_ 2482973248 CabInteriorTempVentilated_Stat_I 100;
BA_ "GenSigCycleTimeActive" SG_ 2482973248 CabInteriorTempVentilated_Stat_I 100;
BA_ "GenSigStartValue" SG_ 2482973248 CabInteriorTempVentilated_Stat_I 1023;
BA_ "GenSigMaxLatency" SG_ 2482973248 CabInteriorTempVentilated_Stat_I 57;
BA_ "Platform_VMCU1_Sig" SG_ 2482973248 CabInteriorTempVentilated_Stat_I 1;
BA_ "SeToolAncestorID_SIGNAL" SG_ 2482973248 CabInteriorTempVentilated_Stat_I "x0000001D043C9954";
BA_ "SeToolItemID_SIGNAL" SG_ 2482973248 CabInteriorTempVentilated_Stat_I "x0000001D043C9954";
BA_ "SeToolName_SIGNAL" SG_ 2482973248 CabInteriorTempVentilated_Stat_I "CabInteriorTempVentilated_Stat";
BA_ "SeToolVersion_SIGNAL" SG_ 2482973248 CabInteriorTempVentilated_Stat_I "1";
BA_ "SystemSignalLongSymbol" SG_ 2482973248 CabInteriorTempVentilated_Stat_I "CabInteriorTempVentilated_Stat_ISig_4";
BA_ "GenSigCycleTime" SG_ 2482973248 ParkHeaterCooler_ButtonStatus_IS 100;
BA_ "GenSigCycleTimeActive" SG_ 2482973248 ParkHeaterCooler_ButtonStatus_IS 100;
BA_ "GenSigStartValue" SG_ 2482973248 ParkHeaterCooler_ButtonStatus_IS 3;
BA_ "GenSigMaxLatency" SG_ 2482973248 ParkHeaterCooler_ButtonStatus_IS 57;
BA_ "Platform_VMCU1_Sig" SG_ 2482973248 ParkHeaterCooler_ButtonStatus_IS 1;
BA_ "SystemSignalLongSymbol" SG_ 2482973248 ParkHeaterCooler_ButtonStatus_IS "ParkHeaterCooler_ButtonStatus_ISig_4";
BA_ "GenSigCycleTime" SG_ 2482973248 WindscreenDefrost_ButtonStatus_I 100;
BA_ "GenSigCycleTimeActive" SG_ 2482973248 WindscreenDefrost_ButtonStatus_I 100;
BA_ "GenSigStartValue" SG_ 2482973248 WindscreenDefrost_ButtonStatus_I 3;
BA_ "GenSigMaxLatency" SG_ 2482973248 WindscreenDefrost_ButtonStatus_I 57;
BA_ "Platform_VMCU1_Sig" SG_ 2482973248 WindscreenDefrost_ButtonStatus_I 1;
BA_ "SeToolAncestorID_SIGNAL" SG_ 2482973248 WindscreenDefrost_ButtonStatus_I "x0000001D0423D932";
BA_ "SeToolItemID_SIGNAL" SG_ 2482973248 WindscreenDefrost_ButtonStatus_I "x0000001D0429669B";
BA_ "SeToolName_SIGNAL" SG_ 2482973248 WindscreenDefrost_ButtonStatus_I "WindscreenDefroster_ButtonStatus";
BA_ "SeToolVersion_SIGNAL" SG_ 2482973248 WindscreenDefrost_ButtonStatus_I "4";
BA_ "SystemSignalLongSymbol" SG_ 2482973248 WindscreenDefrost_ButtonStatus_I "WindscreenDefrost_ButtonStatus_ISig_4";
BA_ "GenSigCycleTime" SG_ 2482973248 AC_ButtonStatus_ISig_4 100;
BA_ "GenSigCycleTimeActive" SG_ 2482973248 AC_ButtonStatus_ISig_4 100;
BA_ "GenSigStartValue" SG_ 2482973248 AC_ButtonStatus_ISig_4 3;
BA_ "GenSigMaxLatency" SG_ 2482973248 AC_ButtonStatus_ISig_4 57;
BA_ "Platform_VMCU1_Sig" SG_ 2482973248 AC_ButtonStatus_ISig_4 1;
BA_ "SeToolAncestorID_SIGNAL" SG_ 2482973248 AC_ButtonStatus_ISig_4 "x0000001D0423D932";
BA_ "SeToolItemID_SIGNAL" SG_ 2482973248 AC_ButtonStatus_ISig_4 "x0000001D0429669B";
BA_ "SeToolName_SIGNAL" SG_ 2482973248 AC_ButtonStatus_ISig_4 "AC_ButtonStatus";
BA_ "SeToolVersion_SIGNAL" SG_ 2482973248 AC_ButtonStatus_ISig_4 "4";
BA_ "GenSigCycleTime" SG_ 2365532224 BBContainerUnlockRequest 100;
BA_ "GenSigCycleTimeActive" SG_ 2365532224 BBContainerUnlockRequest 100;
BA_ "GenSigStartValue" SG_ 2365532224 BBContainerUnlockRequest 3;
BA_ "Platform_VMCU1_Sig" SG_ 2365532224 BBContainerUnlockRequest 1;
BA_ "GenSigCycleTime" SG_ 2365532224 CabPlowLight_rqst 100;
BA_ "GenSigCycleTimeActive" SG_ 2365532224 CabPlowLight_rqst 100;
BA_ "GenSigStartValue" SG_ 2365532224 CabPlowLight_rqst 3;
BA_ "Platform_VMCU1_Sig" SG_ 2365532224 CabPlowLight_rqst 1;
BA_ "GenSigCycleTime" SG_ 2365532224 AC_CompressorClutchCmd_ISig_4 100;
BA_ "GenSigCycleTimeActive" SG_ 2365532224 AC_CompressorClutchCmd_ISig_4 100;
BA_ "GenSigStartValue" SG_ 2365532224 AC_CompressorClutchCmd_ISig_4 3;
BA_ "Platform_VMCU1_Sig" SG_ 2365532224 AC_CompressorClutchCmd_ISig_4 1;
BA_ "GenSigCycleTime" SG_ 2365532224 AuxSwitchBbLoad4_Request 100;
BA_ "GenSigCycleTimeActive" SG_ 2365532224 AuxSwitchBbLoad4_Request 100;
BA_ "GenSigStartValue" SG_ 2365532224 AuxSwitchBbLoad4_Request 3;
BA_ "Platform_VMCU1_Sig" SG_ 2365532224 AuxSwitchBbLoad4_Request 1;
BA_ "GenSigCycleTime" SG_ 2365532224 FogLightRear_ButtonStatus_1 100;
BA_ "GenSigCycleTimeActive" SG_ 2365532224 FogLightRear_ButtonStatus_1 100;
BA_ "GenSigStartValue" SG_ 2365532224 FogLightRear_ButtonStatus_1 3;
BA_ "GenSigMaxLatency" SG_ 2365532224 FogLightRear_ButtonStatus_1 29;
BA_ "Platform_VMCU1_Sig" SG_ 2365532224 FogLightRear_ButtonStatus_1 1;
BA_ "SeToolAncestorID_SIGNAL" SG_ 2365532224 FogLightRear_ButtonStatus_1 "x0000001D0423D932";
BA_ "SeToolItemID_SIGNAL" SG_ 2365532224 FogLightRear_ButtonStatus_1 "x0000001D0429669B";
BA_ "SeToolName_SIGNAL" SG_ 2365532224 FogLightRear_ButtonStatus_1 "FogLightRear_ButtonStatus_1";
BA_ "SeToolVersion_SIGNAL" SG_ 2365532224 FogLightRear_ButtonStatus_1 "4";
BA_ "GenSigCycleTime" SG_ 2365532224 CabRoofSignOrVegaLight_rqst 100;
BA_ "GenSigCycleTimeActive" SG_ 2365532224 CabRoofSignOrVegaLight_rqst 100;
BA_ "GenSigStartValue" SG_ 2365532224 CabRoofSignOrVegaLight_rqst 3;
BA_ "GenSigMaxLatency" SG_ 2365532224 CabRoofSignOrVegaLight_rqst 29;
BA_ "Platform_VMCU1_Sig" SG_ 2365532224 CabRoofSignOrVegaLight_rqst 1;
BA_ "SeToolAncestorID_SIGNAL" SG_ 2365532224 CabRoofSignOrVegaLight_rqst "x0000001D041A6CF7";
BA_ "SeToolItemID_SIGNAL" SG_ 2365532224 CabRoofSignOrVegaLight_rqst "x0000001D041A6CF7";
BA_ "SeToolName_SIGNAL" SG_ 2365532224 CabRoofSignOrVegaLight_rqst "CabRoofSignLight_rqst";
BA_ "SeToolVersion_SIGNAL" SG_ 2365532224 CabRoofSignOrVegaLight_rqst "1";
BA_ "GenSigCycleTime" SG_ 2365532224 FogLightFront_ButtonStatus_2 100;
BA_ "GenSigCycleTimeActive" SG_ 2365532224 FogLightFront_ButtonStatus_2 100;
BA_ "GenSigStartValue" SG_ 2365532224 FogLightFront_ButtonStatus_2 3;
BA_ "GenSigMaxLatency" SG_ 2365532224 FogLightFront_ButtonStatus_2 29;
BA_ "Platform_VMCU1_Sig" SG_ 2365532224 FogLightFront_ButtonStatus_2 1;
BA_ "SeToolAncestorID_SIGNAL" SG_ 2365532224 FogLightFront_ButtonStatus_2 "x0000001D0423D932";
BA_ "SeToolItemID_SIGNAL" SG_ 2365532224 FogLightFront_ButtonStatus_2 "x0000001D0429669B";
BA_ "SeToolName_SIGNAL" SG_ 2365532224 FogLightFront_ButtonStatus_2 "FogLightFront_ButtonStatus_2";
BA_ "SeToolVersion_SIGNAL" SG_ 2365532224 FogLightFront_ButtonStatus_2 "4";
BA_ "GenSigCycleTime" SG_ 2365532224 AuxSwitchBbLoad1_Request 100;
BA_ "GenSigCycleTimeActive" SG_ 2365532224 AuxSwitchBbLoad1_Request 100;
BA_ "GenSigStartValue" SG_ 2365532224 AuxSwitchBbLoad1_Request 3;
BA_ "Platform_VMCU1_Sig" SG_ 2365532224 AuxSwitchBbLoad1_Request 1;
BA_ "GenSigCycleTime" SG_ 2365532224 BBCraneRequest 100;
BA_ "GenSigCycleTimeActive" SG_ 2365532224 BBCraneRequest 100;
BA_ "GenSigStartValue" SG_ 2365532224 BBCraneRequest 3;
BA_ "Platform_VMCU1_Sig" SG_ 2365532224 BBCraneRequest 1;
BA_ "GenSigCycleTime" SG_ 2365532224 AuxSwitchBbLoad6_Request 100;
BA_ "GenSigCycleTimeActive" SG_ 2365532224 AuxSwitchBbLoad6_Request 100;
BA_ "GenSigStartValue" SG_ 2365532224 AuxSwitchBbLoad6_Request 3;
BA_ "Platform_VMCU1_Sig" SG_ 2365532224 AuxSwitchBbLoad6_Request 1;
BA_ "GenSigCycleTime" SG_ 2365532224 AuxSwitchBbLoad5_Request 100;
BA_ "GenSigCycleTimeActive" SG_ 2365532224 AuxSwitchBbLoad5_Request 100;
BA_ "GenSigStartValue" SG_ 2365532224 AuxSwitchBbLoad5_Request 3;
BA_ "Platform_VMCU1_Sig" SG_ 2365532224 AuxSwitchBbLoad5_Request 1;
BA_ "GenSigCycleTime" SG_ 2365532224 BodyOrCabWorkingLight_rqst 100;
BA_ "GenSigCycleTimeActive" SG_ 2365532224 BodyOrCabWorkingLight_rqst 100;
BA_ "GenSigStartValue" SG_ 2365532224 BodyOrCabWorkingLight_rqst 3;
BA_ "GenSigMaxLatency" SG_ 2365532224 BodyOrCabWorkingLight_rqst 29;
BA_ "Platform_VMCU1_Sig" SG_ 2365532224 BodyOrCabWorkingLight_rqst 1;
BA_ "SeToolAncestorID_SIGNAL" SG_ 2365532224 BodyOrCabWorkingLight_rqst "x0000001D041A6CF9";
BA_ "SeToolItemID_SIGNAL" SG_ 2365532224 BodyOrCabWorkingLight_rqst "x0000001D041A6CF9";
BA_ "SeToolName_SIGNAL" SG_ 2365532224 BodyOrCabWorkingLight_rqst "CabBody/CabWorkingLight_rqst";
BA_ "SeToolVersion_SIGNAL" SG_ 2365532224 BodyOrCabWorkingLight_rqst "1";
BA_ "GenSigCycleTime" SG_ 2365532224 CabFrontSpot_rqst 100;
BA_ "GenSigCycleTimeActive" SG_ 2365532224 CabFrontSpot_rqst 100;
BA_ "GenSigStartValue" SG_ 2365532224 CabFrontSpot_rqst 3;
BA_ "GenSigMaxLatency" SG_ 2365532224 CabFrontSpot_rqst 29;
BA_ "Platform_VMCU1_Sig" SG_ 2365532224 CabFrontSpot_rqst 1;
BA_ "SeToolAncestorID_SIGNAL" SG_ 2365532224 CabFrontSpot_rqst "x0000001D041A6CF5";
BA_ "SeToolItemID_SIGNAL" SG_ 2365532224 CabFrontSpot_rqst "x0000001D041A6CF5";
BA_ "SeToolName_SIGNAL" SG_ 2365532224 CabFrontSpot_rqst "CabFrontSpot_rqst";
BA_ "SeToolVersion_SIGNAL" SG_ 2365532224 CabFrontSpot_rqst "1";
BA_ "GenSigCycleTime" SG_ 2365532224 CabTrailerBodyLighting_rqst 100;
BA_ "GenSigCycleTimeActive" SG_ 2365532224 CabTrailerBodyLighting_rqst 100;
BA_ "GenSigStartValue" SG_ 2365532224 CabTrailerBodyLighting_rqst 3;
BA_ "GenSigMaxLatency" SG_ 2365532224 CabTrailerBodyLighting_rqst 29;
BA_ "Platform_VMCU1_Sig" SG_ 2365532224 CabTrailerBodyLighting_rqst 1;
BA_ "SeToolAncestorID_SIGNAL" SG_ 2365532224 CabTrailerBodyLighting_rqst "x0000001D04206C33";
BA_ "SeToolItemID_SIGNAL" SG_ 2365532224 CabTrailerBodyLighting_rqst "x0000001D042FD0E8";
BA_ "SeToolName_SIGNAL" SG_ 2365532224 CabTrailerBodyLighting_rqst "CabTrailerBodyLighting_rqst";
BA_ "SeToolVersion_SIGNAL" SG_ 2365532224 CabTrailerBodyLighting_rqst "2";
BA_ "GenSigCycleTime" SG_ 2365532224 CabWorkingLightChassis_rqst 100;
BA_ "GenSigCycleTimeActive" SG_ 2365532224 CabWorkingLightChassis_rqst 100;
BA_ "GenSigStartValue" SG_ 2365532224 CabWorkingLightChassis_rqst 3;
BA_ "GenSigMaxLatency" SG_ 2365532224 CabWorkingLightChassis_rqst 29;
BA_ "Platform_VMCU1_Sig" SG_ 2365532224 CabWorkingLightChassis_rqst 1;
BA_ "SeToolAncestorID_SIGNAL" SG_ 2365532224 CabWorkingLightChassis_rqst "x0000001D041A6D07";
BA_ "SeToolItemID_SIGNAL" SG_ 2365532224 CabWorkingLightChassis_rqst "x0000001D041A6D07";
BA_ "SeToolName_SIGNAL" SG_ 2365532224 CabWorkingLightChassis_rqst "CabWorkingLightChassis_rqst";
BA_ "SeToolVersion_SIGNAL" SG_ 2365532224 CabWorkingLightChassis_rqst "1";
BA_ "GenSigCycleTime" SG_ 2365532224 BBTailLiftRequest 100;
BA_ "GenSigCycleTimeActive" SG_ 2365532224 BBTailLiftRequest 100;
BA_ "GenSigStartValue" SG_ 2365532224 BBTailLiftRequest 3;
BA_ "Platform_VMCU1_Sig" SG_ 2365532224 BBTailLiftRequest 1;
BA_ "GenSigCycleTime" SG_ 2365532224 BBSlidable5thWheelRequest 100;
BA_ "GenSigCycleTimeActive" SG_ 2365532224 BBSlidable5thWheelRequest 100;
BA_ "GenSigStartValue" SG_ 2365532224 BBSlidable5thWheelRequest 3;
BA_ "Platform_VMCU1_Sig" SG_ 2365532224 BBSlidable5thWheelRequest 1;
BA_ "GenSigCycleTime" SG_ 2365532224 ACmode_IndicationCmd_ISig_4 100;
BA_ "GenSigCycleTimeActive" SG_ 2365532224 ACmode_IndicationCmd_ISig_4 100;
BA_ "Platform_VMCU1_Sig" SG_ 2365532224 ACmode_IndicationCmd_ISig_4 1;
BA_ "SeToolAncestorID_SIGNAL" SG_ 2365532224 ACmode_IndicationCmd_ISig_4 "x0000001D04405ABB";
BA_ "SeToolItemID_SIGNAL" SG_ 2365532224 ACmode_IndicationCmd_ISig_4 "x0000001D04405ABB";
BA_ "SeToolName_SIGNAL" SG_ 2365532224 ACmode_IndicationCmd_ISig_4 "ACmode_IndicationCmd";
BA_ "SeToolVersion_SIGNAL" SG_ 2365532224 ACmode_IndicationCmd_ISig_4 "1";
BA_ "GenSigCycleTime" SG_ 2365532224 CabExtraSideWorkingLight_rqst 100;
BA_ "GenSigCycleTimeActive" SG_ 2365532224 CabExtraSideWorkingLight_rqst 100;
BA_ "GenSigStartValue" SG_ 2365532224 CabExtraSideWorkingLight_rqst 7;
BA_ "GenSigMaxLatency" SG_ 2365532224 CabExtraSideWorkingLight_rqst 29;
BA_ "Platform_VMCU1_Sig" SG_ 2365532224 CabExtraSideWorkingLight_rqst 1;
BA_ "SeToolAncestorID_SIGNAL" SG_ 2365532224 CabExtraSideWorkingLight_rqst "x0000001D041AF5F5";
BA_ "SeToolItemID_SIGNAL" SG_ 2365532224 CabExtraSideWorkingLight_rqst "x0000001D041AF5F5";
BA_ "SeToolName_SIGNAL" SG_ 2365532224 CabExtraSideWorkingLight_rqst "CabExtraSideWorkingLight_rqst";
BA_ "SeToolVersion_SIGNAL" SG_ 2365532224 CabExtraSideWorkingLight_rqst "1";
BA_ "GenSigCycleTime" SG_ 2365532224 FogLightFront_ButtonStatus_1 100;
BA_ "GenSigCycleTimeActive" SG_ 2365532224 FogLightFront_ButtonStatus_1 100;
BA_ "GenSigStartValue" SG_ 2365532224 FogLightFront_ButtonStatus_1 3;
BA_ "GenSigMaxLatency" SG_ 2365532224 FogLightFront_ButtonStatus_1 29;
BA_ "Platform_VMCU1_Sig" SG_ 2365532224 FogLightFront_ButtonStatus_1 1;
BA_ "SeToolAncestorID_SIGNAL" SG_ 2365532224 FogLightFront_ButtonStatus_1 "x0000001D0423D932";
BA_ "SeToolItemID_SIGNAL" SG_ 2365532224 FogLightFront_ButtonStatus_1 "x0000001D0429669B";
BA_ "SeToolName_SIGNAL" SG_ 2365532224 FogLightFront_ButtonStatus_1 "FogLightFront_ButtonStatus_1";
BA_ "SeToolVersion_SIGNAL" SG_ 2365532224 FogLightFront_ButtonStatus_1 "4";
BA_ "GenSigCycleTime" SG_ 2365532224 AuxSwitchBbLoad2_Request 100;
BA_ "GenSigCycleTimeActive" SG_ 2365532224 AuxSwitchBbLoad2_Request 100;
BA_ "GenSigStartValue" SG_ 2365532224 AuxSwitchBbLoad2_Request 3;
BA_ "Platform_VMCU1_Sig" SG_ 2365532224 AuxSwitchBbLoad2_Request 1;
BA_ "GenSigCycleTime" SG_ 2365532224 DRL_ButtonStatus 100;
BA_ "GenSigCycleTimeActive" SG_ 2365532224 DRL_ButtonStatus 100;
BA_ "GenSigStartValue" SG_ 2365532224 DRL_ButtonStatus 3;
BA_ "GenSigMaxLatency" SG_ 2365532224 DRL_ButtonStatus 29;
BA_ "Platform_VMCU1_Sig" SG_ 2365532224 DRL_ButtonStatus 1;
BA_ "SeToolAncestorID_SIGNAL" SG_ 2365532224 DRL_ButtonStatus "x0000001D0423D932";
BA_ "SeToolItemID_SIGNAL" SG_ 2365532224 DRL_ButtonStatus "x0000001D0429669B";
BA_ "SeToolName_SIGNAL" SG_ 2365532224 DRL_ButtonStatus "DRL_ButtonStatus";
BA_ "SeToolVersion_SIGNAL" SG_ 2365532224 DRL_ButtonStatus "4";
BA_ "GenSigCycleTime" SG_ 2365532224 CabRoofSpot_rqst 100;
BA_ "GenSigCycleTimeActive" SG_ 2365532224 CabRoofSpot_rqst 100;
BA_ "GenSigStartValue" SG_ 2365532224 CabRoofSpot_rqst 3;
BA_ "GenSigMaxLatency" SG_ 2365532224 CabRoofSpot_rqst 29;
BA_ "Platform_VMCU1_Sig" SG_ 2365532224 CabRoofSpot_rqst 1;
BA_ "SeToolAncestorID_SIGNAL" SG_ 2365532224 CabRoofSpot_rqst "x0000001D041A6CF3";
BA_ "SeToolItemID_SIGNAL" SG_ 2365532224 CabRoofSpot_rqst "x0000001D041A6CF3";
BA_ "SeToolName_SIGNAL" SG_ 2365532224 CabRoofSpot_rqst "CabRoofSpot_rqst";
BA_ "SeToolVersion_SIGNAL" SG_ 2365532224 CabRoofSpot_rqst "1";
BA_ "GenSigCycleTime" SG_ 2365532224 LightMode_Status_Ctr_2 100;
BA_ "GenSigCycleTimeActive" SG_ 2365532224 LightMode_Status_Ctr_2 100;
BA_ "GenSigStartValue" SG_ 2365532224 LightMode_Status_Ctr_2 15;
BA_ "Platform_VMCU1_Sig" SG_ 2365532224 LightMode_Status_Ctr_2 1;
BA_ "GenSigCycleTime" SG_ 2365532224 CabBeaconLight_rqst 100;
BA_ "GenSigCycleTimeActive" SG_ 2365532224 CabBeaconLight_rqst 100;
BA_ "GenSigStartValue" SG_ 2365532224 CabBeaconLight_rqst 3;
BA_ "GenSigMaxLatency" SG_ 2365532224 CabBeaconLight_rqst 29;
BA_ "Platform_VMCU1_Sig" SG_ 2365532224 CabBeaconLight_rqst 1;
BA_ "SeToolAncestorID_SIGNAL" SG_ 2365532224 CabBeaconLight_rqst "x0000001D041A6CF1";
BA_ "SeToolItemID_SIGNAL" SG_ 2365532224 CabBeaconLight_rqst "x0000001D041A6CF1";
BA_ "SeToolName_SIGNAL" SG_ 2365532224 CabBeaconLight_rqst "CabBeaconLight_rqst";
BA_ "SeToolVersion_SIGNAL" SG_ 2365532224 CabBeaconLight_rqst "1";
BA_ "GenSigCycleTime" SG_ 2365532224 AuxSwitchBbLoad3_Request 100;
BA_ "GenSigCycleTimeActive" SG_ 2365532224 AuxSwitchBbLoad3_Request 100;
BA_ "GenSigStartValue" SG_ 2365532224 AuxSwitchBbLoad3_Request 3;
BA_ "Platform_VMCU1_Sig" SG_ 2365532224 AuxSwitchBbLoad3_Request 1;
BA_ "GenSigCycleTime" SG_ 2365532224 FogLightRear_ButtonStatus_2 100;
BA_ "GenSigCycleTimeActive" SG_ 2365532224 FogLightRear_ButtonStatus_2 100;
BA_ "GenSigStartValue" SG_ 2365532224 FogLightRear_ButtonStatus_2 3;
BA_ "GenSigMaxLatency" SG_ 2365532224 FogLightRear_ButtonStatus_2 29;
BA_ "Platform_VMCU1_Sig" SG_ 2365532224 FogLightRear_ButtonStatus_2 1;
BA_ "SeToolAncestorID_SIGNAL" SG_ 2365532224 FogLightRear_ButtonStatus_2 "x0000001D0423D932";
BA_ "SeToolItemID_SIGNAL" SG_ 2365532224 FogLightRear_ButtonStatus_2 "x0000001D0429669B";
BA_ "SeToolName_SIGNAL" SG_ 2365532224 FogLightRear_ButtonStatus_2 "FogLightRear_ButtonStatus_2";
BA_ "SeToolVersion_SIGNAL" SG_ 2365532224 FogLightRear_ButtonStatus_2 "4";
BA_ "GenSigCycleTime" SG_ 2365532224 LightMode_Status_Ctr_1 100;
BA_ "GenSigCycleTimeActive" SG_ 2365532224 LightMode_Status_Ctr_1 100;
BA_ "GenSigStartValue" SG_ 2365532224 LightMode_Status_Ctr_1 15;
BA_ "Platform_VMCU1_Sig" SG_ 2365532224 LightMode_Status_Ctr_1 1;
BA_ "GenSigCycleTime" SG_ 2365532224 MirrorHeat_rqst 100;
BA_ "GenSigCycleTimeActive" SG_ 2365532224 MirrorHeat_rqst 100;
BA_ "GenSigStartValue" SG_ 2365532224 MirrorHeat_rqst 7;
BA_ "GenSigMaxLatency" SG_ 2365532224 MirrorHeat_rqst 29;
BA_ "Platform_VMCU1_Sig" SG_ 2365532224 MirrorHeat_rqst 1;
BA_ "SeToolAncestorID_SIGNAL" SG_ 2365532224 MirrorHeat_rqst "x0000001D0412C072";
BA_ "SeToolItemID_SIGNAL" SG_ 2365532224 MirrorHeat_rqst "x0000001D0412C072";
BA_ "SeToolName_SIGNAL" SG_ 2365532224 MirrorHeat_rqst "MirrorHeat_rqst";
BA_ "SeToolVersion_SIGNAL" SG_ 2365532224 MirrorHeat_rqst "1";
BA_ "GenSigCycleTime" SG_ 2432643136 LevelRequest_RollRequest_ISig_4 100;
BA_ "GenSigCycleTimeActive" SG_ 2432643136 LevelRequest_RollRequest_ISig_4 100;
BA_ "GenSigStartValue" SG_ 2432643136 LevelRequest_RollRequest_ISig_4 7;
BA_ "NeedsUpdateBit" SG_ 2432643136 LevelRequest_RollRequest_ISig_4 1;
BA_ "Platform_VMCU1_Sig" SG_ 2432643136 LevelRequest_RollRequest_ISig_4 1;
BA_ "GenSigCycleTime" SG_ 2432643136 FerryFunctionSwitchChangeReq_ISi 100;
BA_ "GenSigCycleTimeActive" SG_ 2432643136 FerryFunctionSwitchChangeReq_ISi 100;
BA_ "GenSigStartValue" SG_ 2432643136 FerryFunctionSwitchChangeReq_ISi 3;
BA_ "Platform_VMCU1_Sig" SG_ 2432643136 FerryFunctionSwitchChangeReq_ISi 1;
BA_ "SystemSignalLongSymbol" SG_ 2432643136 FerryFunctionSwitchChangeReq_ISi "FerryFunctionSwitchChangeReq_ISig_4";
BA_ "GenSigCycleTime" SG_ 2432643136 FerryFunctionRequest_ISig_4 100;
BA_ "GenSigCycleTimeActive" SG_ 2432643136 FerryFunctionRequest_ISig_4 100;
BA_ "GenSigStartValue" SG_ 2432643136 FerryFunctionRequest_ISig_4 3;
BA_ "GenSigMaxLatency" SG_ 2432643136 FerryFunctionRequest_ISig_4 28;
BA_ "NeedsUpdateBit" SG_ 2432643136 FerryFunctionRequest_ISig_4 1;
BA_ "Platform_VMCU1_Sig" SG_ 2432643136 FerryFunctionRequest_ISig_4 1;
BA_ "SeToolAncestorID_SIGNAL" SG_ 2432643136 FerryFunctionRequest_ISig_4 "x0000001D04131411";
BA_ "SeToolItemID_SIGNAL" SG_ 2432643136 FerryFunctionRequest_ISig_4 "x0000001D04131411";
BA_ "SeToolName_SIGNAL" SG_ 2432643136 FerryFunctionRequest_ISig_4 "FerryFunctionRequest";
BA_ "SeToolVersion_SIGNAL" SG_ 2432643136 FerryFunctionRequest_ISig_4 "1";
BA_ "GenSigCycleTime" SG_ 2432643136 LevelRequest_FrontAxle_ISig_4 100;
BA_ "GenSigCycleTimeActive" SG_ 2432643136 LevelRequest_FrontAxle_ISig_4 100;
BA_ "GenSigStartValue" SG_ 2432643136 LevelRequest_FrontAxle_ISig_4 7;
BA_ "NeedsUpdateBit" SG_ 2432643136 LevelRequest_FrontAxle_ISig_4 1;
BA_ "Platform_VMCU1_Sig" SG_ 2432643136 LevelRequest_FrontAxle_ISig_4 1;
BA_ "GenSigCycleTime" SG_ 2432643136 KneelingChangeRequest_ISig_4 100;
BA_ "GenSigCycleTimeActive" SG_ 2432643136 KneelingChangeRequest_ISig_4 100;
BA_ "GenSigStartValue" SG_ 2432643136 KneelingChangeRequest_ISig_4 3;
BA_ "Platform_VMCU1_Sig" SG_ 2432643136 KneelingChangeRequest_ISig_4 1;
BA_ "GenSigSendType" SG_ 2432643136 FerryFunctionRequest_UB_ISig_4 7;
BA_ "Platform_VMCU1_Sig" SG_ 2432643136 FerryFunctionRequest_UB_ISig_4 1;
BA_ "GenSigCycleTime" SG_ 2432643136 BunkH1AudioSrcSem_rqst_ISig_4 100;
BA_ "GenSigCycleTimeActive" SG_ 2432643136 BunkH1AudioSrcSem_rqst_ISig_4 100;
BA_ "GenSigStartValue" SG_ 2432643136 BunkH1AudioSrcSem_rqst_ISig_4 15;
BA_ "Platform_VMCU1_Sig" SG_ 2432643136 BunkH1AudioSrcSem_rqst_ISig_4 1;
BA_ "GenSigCycleTime" SG_ 2432643136 ECSStandByRequest_ISig_4 100;
BA_ "GenSigCycleTimeActive" SG_ 2432643136 ECSStandByRequest_ISig_4 100;
BA_ "GenSigStartValue" SG_ 2432643136 ECSStandByRequest_ISig_4 7;
BA_ "Platform_VMCU1_Sig" SG_ 2432643136 ECSStandByRequest_ISig_4 1;
BA_ "GenSigCycleTime" SG_ 2432643136 LevelStrokeRequest_ISig_4 100;
BA_ "GenSigCycleTimeActive" SG_ 2432643136 LevelStrokeRequest_ISig_4 100;
BA_ "GenSigStartValue" SG_ 2432643136 LevelStrokeRequest_ISig_4 3;
BA_ "GenSigMaxLatency" SG_ 2432643136 LevelStrokeRequest_ISig_4 28;
BA_ "Platform_VMCU1_Sig" SG_ 2432643136 LevelStrokeRequest_ISig_4 1;
BA_ "SeToolAncestorID_SIGNAL" SG_ 2432643136 LevelStrokeRequest_ISig_4 "x0000001D0413029C";
BA_ "SeToolItemID_SIGNAL" SG_ 2432643136 LevelStrokeRequest_ISig_4 "x0000001D0413029C";
BA_ "SeToolName_SIGNAL" SG_ 2432643136 LevelStrokeRequest_ISig_4 "LevelStrokeRequest";
BA_ "SeToolVersion_SIGNAL" SG_ 2432643136 LevelStrokeRequest_ISig_4 "1";
BA_ "GenSigCycleTime" SG_ 2432643136 RideHeightStorageRequest_ISig_4 100;
BA_ "GenSigCycleTimeActive" SG_ 2432643136 RideHeightStorageRequest_ISig_4 100;
BA_ "GenSigStartValue" SG_ 2432643136 RideHeightStorageRequest_ISig_4 15;
BA_ "GenSigMaxLatency" SG_ 2432643136 RideHeightStorageRequest_ISig_4 28;
BA_ "Platform_VMCU1_Sig" SG_ 2432643136 RideHeightStorageRequest_ISig_4 1;
BA_ "SeToolAncestorID_SIGNAL" SG_ 2432643136 RideHeightStorageRequest_ISig_4 "x0000001D041302B5";
BA_ "SeToolItemID_SIGNAL" SG_ 2432643136 RideHeightStorageRequest_ISig_4 "x0000001D041302B5";
BA_ "SeToolName_SIGNAL" SG_ 2432643136 RideHeightStorageRequest_ISig_4 "RideHeightStorageRequest";
BA_ "SeToolVersion_SIGNAL" SG_ 2432643136 RideHeightStorageRequest_ISig_4 "1";
BA_ "GenSigCycleTime" SG_ 2432643136 RampLevelRequest_ISig_4 100;
BA_ "GenSigCycleTimeActive" SG_ 2432643136 RampLevelRequest_ISig_4 100;
BA_ "GenSigStartValue" SG_ 2432643136 RampLevelRequest_ISig_4 15;
BA_ "GenSigMaxLatency" SG_ 2432643136 RampLevelRequest_ISig_4 28;
BA_ "Platform_VMCU1_Sig" SG_ 2432643136 RampLevelRequest_ISig_4 1;
BA_ "SeToolAncestorID_SIGNAL" SG_ 2432643136 RampLevelRequest_ISig_4 "x0000001D041301DB";
BA_ "SeToolItemID_SIGNAL" SG_ 2432643136 RampLevelRequest_ISig_4 "x0000001D041301DB";
BA_ "SeToolName_SIGNAL" SG_ 2432643136 RampLevelRequest_ISig_4 "RampLevelRequest";
BA_ "SeToolVersion_SIGNAL" SG_ 2432643136 RampLevelRequest_ISig_4 "1";
BA_ "GenSigCycleTime" SG_ 2432643136 TCP_KnobPostionStatus 100;
BA_ "GenSigCycleTimeActive" SG_ 2432643136 TCP_KnobPostionStatus 100;
BA_ "GenSigStartValue" SG_ 2432643136 TCP_KnobPostionStatus 3;
BA_ "GenSigMaxLatency" SG_ 2432643136 TCP_KnobPostionStatus 1038;
BA_ "GenSigCycleTime" SG_ 2432643136 SetFCWOperation 100;
BA_ "GenSigCycleTimeActive" SG_ 2432643136 SetFCWOperation 100;
BA_ "GenSigStartValue" SG_ 2432643136 SetFCWOperation 7;
BA_ "Platform_VMCU1_Sig" SG_ 2432643136 SetFCWOperation 1;
BA_ "GenSigCycleTime" SG_ 2432643136 StopLevelChangeRequest_ISig_4 100;
BA_ "GenSigCycleTimeActive" SG_ 2432643136 StopLevelChangeRequest_ISig_4 100;
BA_ "GenSigStartValue" SG_ 2432643136 StopLevelChangeRequest_ISig_4 3;
BA_ "GenSigMaxLatency" SG_ 2432643136 StopLevelChangeRequest_ISig_4 28;
BA_ "Platform_VMCU1_Sig" SG_ 2432643136 StopLevelChangeRequest_ISig_4 1;
BA_ "SeToolAncestorID_SIGNAL" SG_ 2432643136 StopLevelChangeRequest_ISig_4 "x0000001D041301E9";
BA_ "SeToolItemID_SIGNAL" SG_ 2432643136 StopLevelChangeRequest_ISig_4 "x0000001D041301E9";
BA_ "SeToolName_SIGNAL" SG_ 2432643136 StopLevelChangeRequest_ISig_4 "StopLevelChangeRequest";
BA_ "SeToolVersion_SIGNAL" SG_ 2432643136 StopLevelChangeRequest_ISig_4 "1";
BA_ "GenSigSendType" SG_ 2432643136 LevelRequest_sg_UB_ISig_4 7;
BA_ "Platform_VMCU1_Sig" SG_ 2432643136 LevelRequest_sg_UB_ISig_4 1;
BA_ "GenSigCycleTime" SG_ 2432643136 RideHeightFunctionRequest_ISig_4 100;
BA_ "GenSigCycleTimeActive" SG_ 2432643136 RideHeightFunctionRequest_ISig_4 100;
BA_ "GenSigStartValue" SG_ 2432643136 RideHeightFunctionRequest_ISig_4 15;
BA_ "GenSigMaxLatency" SG_ 2432643136 RideHeightFunctionRequest_ISig_4 28;
BA_ "NeedsUpdateBit" SG_ 2432643136 RideHeightFunctionRequest_ISig_4 1;
BA_ "Platform_VMCU1_Sig" SG_ 2432643136 RideHeightFunctionRequest_ISig_4 1;
BA_ "SeToolAncestorID_SIGNAL" SG_ 2432643136 RideHeightFunctionRequest_ISig_4 "x0000001D0412F86D";
BA_ "SeToolItemID_SIGNAL" SG_ 2432643136 RideHeightFunctionRequest_ISig_4 "x0000001D043FB86B";
BA_ "SeToolName_SIGNAL" SG_ 2432643136 RideHeightFunctionRequest_ISig_4 "RideHeightFunctionRequest";
BA_ "SeToolVersion_SIGNAL" SG_ 2432643136 RideHeightFunctionRequest_ISig_4 "2";
BA_ "GenSigCycleTime" SG_ 2432643136 LevelRequest_RearAxle_ISig_4 100;
BA_ "GenSigCycleTimeActive" SG_ 2432643136 LevelRequest_RearAxle_ISig_4 100;
BA_ "GenSigStartValue" SG_ 2432643136 LevelRequest_RearAxle_ISig_4 7;
BA_ "NeedsUpdateBit" SG_ 2432643136 LevelRequest_RearAxle_ISig_4 1;
BA_ "Platform_VMCU1_Sig" SG_ 2432643136 LevelRequest_RearAxle_ISig_4 1;
BA_ "GenSigCycleTime" SG_ 2432643136 RampLevelStorageRequest_ISig_4 100;
BA_ "GenSigCycleTimeActive" SG_ 2432643136 RampLevelStorageRequest_ISig_4 100;
BA_ "GenSigStartValue" SG_ 2432643136 RampLevelStorageRequest_ISig_4 15;
BA_ "GenSigMaxLatency" SG_ 2432643136 RampLevelStorageRequest_ISig_4 28;
BA_ "Platform_VMCU1_Sig" SG_ 2432643136 RampLevelStorageRequest_ISig_4 1;
BA_ "SeToolAncestorID_SIGNAL" SG_ 2432643136 RampLevelStorageRequest_ISig_4 "x0000001D041301E3";
BA_ "SeToolItemID_SIGNAL" SG_ 2432643136 RampLevelStorageRequest_ISig_4 "x0000001D041301E3";
BA_ "SeToolName_SIGNAL" SG_ 2432643136 RampLevelStorageRequest_ISig_4 "RampLevelStorageRequest";
BA_ "SeToolVersion_SIGNAL" SG_ 2432643136 RampLevelStorageRequest_ISig_4 "1";
BA_ "GenSigCycleTime" SG_ 2432643136 SetCMOperation 100;
BA_ "GenSigCycleTimeActive" SG_ 2432643136 SetCMOperation 100;
BA_ "GenSigStartValue" SG_ 2432643136 SetCMOperation 7;
BA_ "Platform_VMCU1_Sig" SG_ 2432643136 SetCMOperation 1;
BA_ "GenSigSendType" SG_ 2432643136 RideHeightFunctionRequest_UB_ISi 7;
BA_ "Platform_VMCU1_Sig" SG_ 2432643136 RideHeightFunctionRequest_UB_ISi 1;
BA_ "SystemSignalLongSymbol" SG_ 2432643136 RideHeightFunctionRequest_UB_ISi "RideHeightFunctionRequest_UB_ISig_4";
BA_ "GenSigCycleTime" SG_ 2432643136 BackToDriveReq_ISig_4 100;
BA_ "GenSigCycleTimeActive" SG_ 2432643136 BackToDriveReq_ISig_4 100;
BA_ "GenSigStartValue" SG_ 2432643136 BackToDriveReq_ISig_4 3;
BA_ "Platform_VMCU1_Sig" SG_ 2432643136 BackToDriveReq_ISig_4 1;
BA_ "GenSigCycleTime" SG_ 2432640832 LockingIndication_rqst 100;
BA_ "GenSigCycleTimeActive" SG_ 2432640832 LockingIndication_rqst 100;
BA_ "GenSigStartValue" SG_ 2432640832 LockingIndication_rqst 7;
BA_ "Platform_VMCU1_Sig" SG_ 2432640832 LockingIndication_rqst 1;
BA_ "GenSigSendType" SG_ 2432640832 CityHorn_cmd_UB_ISig_4 7;
BA_ "Platform_VMCU1_Sig" SG_ 2432640832 CityHorn_cmd_UB_ISig_4 1;
BA_ "GenSigCycleTime" SG_ 2432640832 KeyfobLockBtn_DoublePress_ISig_4 100;
BA_ "GenSigCycleTimeActive" SG_ 2432640832 KeyfobLockBtn_DoublePress_ISig_4 100;
BA_ "GenSigStartValue" SG_ 2432640832 KeyfobLockBtn_DoublePress_ISig_4 3;
BA_ "Platform_VMCU1_Sig" SG_ 2432640832 KeyfobLockBtn_DoublePress_ISig_4 1;
BA_ "GenSigCycleTime" SG_ 2432640832 MainSwitchButton_Status_ISig_4 100;
BA_ "GenSigCycleTimeActive" SG_ 2432640832 MainSwitchButton_Status_ISig_4 100;
BA_ "GenSigStartValue" SG_ 2432640832 MainSwitchButton_Status_ISig_4 3;
BA_ "Platform_VMCU1_Sig" SG_ 2432640832 MainSwitchButton_Status_ISig_4 1;
BA_ "GenSigCycleTime" SG_ 2432640832 CityHorn_cmd_ISig_4 100;
BA_ "GenSigCycleTimeActive" SG_ 2432640832 CityHorn_cmd_ISig_4 100;
BA_ "GenSigStartValue" SG_ 2432640832 CityHorn_cmd_ISig_4 3;
BA_ "GenSigMaxLatency" SG_ 2432640832 CityHorn_cmd_ISig_4 27;
BA_ "NeedsUpdateBit" SG_ 2432640832 CityHorn_cmd_ISig_4 1;
BA_ "Platform_VMCU1_Sig" SG_ 2432640832 CityHorn_cmd_ISig_4 1;
BA_ "SeToolAncestorID_SIGNAL" SG_ 2432640832 CityHorn_cmd_ISig_4 "x0000001D040FCB08";
BA_ "SeToolItemID_SIGNAL" SG_ 2432640832 CityHorn_cmd_ISig_4 "x0000001D042E3A55";
BA_ "SeToolName_SIGNAL" SG_ 2432640832 CityHorn_cmd_ISig_4 "CityHorn_cmd";
BA_ "SeToolVersion_SIGNAL" SG_ 2432640832 CityHorn_cmd_ISig_4 "2";
BA_ "GenSigCycleTime" SG_ 2432640832 KeyfobUnlockButton_Status 100;
BA_ "GenSigCycleTimeActive" SG_ 2432640832 KeyfobUnlockButton_Status 100;
BA_ "GenSigStartValue" SG_ 2432640832 KeyfobUnlockButton_Status 3;
BA_ "Platform_VMCU1_Sig" SG_ 2432640832 KeyfobUnlockButton_Status 1;
BA_ "GenSigCycleTime" SG_ 2432640832 BrakeBlendingButtonStatus 100;
BA_ "GenSigCycleTimeActive" SG_ 2432640832 BrakeBlendingButtonStatus 100;
BA_ "GenSigStartValue" SG_ 2432640832 BrakeBlendingButtonStatus 3;
BA_ "Platform_VMCU1_Sig" SG_ 2432640832 BrakeBlendingButtonStatus 1;
BA_ "GenSigSendType" SG_ 2432640832 AuxiliaryHorn_cmd_UB_ISig_4 7;
BA_ "Platform_VMCU1_Sig" SG_ 2432640832 AuxiliaryHorn_cmd_UB_ISig_4 1;
BA_ "GenSigCycleTime" SG_ 2432640832 KeyNotValid 100;
BA_ "GenSigCycleTimeActive" SG_ 2432640832 KeyNotValid 100;
BA_ "GenSigStartValue" SG_ 2432640832 KeyNotValid 7;
BA_ "Platform_VMCU1_Sig" SG_ 2432640832 KeyNotValid 1;
BA_ "GenSigCycleTime" SG_ 2432640832 ExtraMainbeam_SwitchStatus 100;
BA_ "GenSigCycleTimeActive" SG_ 2432640832 ExtraMainbeam_SwitchStatus 100;
BA_ "GenSigStartValue" SG_ 2432640832 ExtraMainbeam_SwitchStatus 3;
BA_ "Platform_VMCU1_Sig" SG_ 2432640832 ExtraMainbeam_SwitchStatus 1;
BA_ "GenSigCycleTime" SG_ 2432640832 AuxiliaryHorn_cmd_ISig_4 100;
BA_ "GenSigCycleTimeActive" SG_ 2432640832 AuxiliaryHorn_cmd_ISig_4 100;
BA_ "GenSigStartValue" SG_ 2432640832 AuxiliaryHorn_cmd_ISig_4 3;
BA_ "GenSigMaxLatency" SG_ 2432640832 AuxiliaryHorn_cmd_ISig_4 27;
BA_ "NeedsUpdateBit" SG_ 2432640832 AuxiliaryHorn_cmd_ISig_4 1;
BA_ "Platform_VMCU1_Sig" SG_ 2432640832 AuxiliaryHorn_cmd_ISig_4 1;
BA_ "SeToolAncestorID_SIGNAL" SG_ 2432640832 AuxiliaryHorn_cmd_ISig_4 "x0000001D040FCAFD";
BA_ "SeToolItemID_SIGNAL" SG_ 2432640832 AuxiliaryHorn_cmd_ISig_4 "x0000001D042E3A36";
BA_ "SeToolName_SIGNAL" SG_ 2432640832 AuxiliaryHorn_cmd_ISig_4 "AuxiliaryHorn_cmd";
BA_ "SeToolVersion_SIGNAL" SG_ 2432640832 AuxiliaryHorn_cmd_ISig_4 "2";
BA_ "GenSigCycleTime" SG_ 2432640832 ReverseWarning_rqst_ISig_4 100;
BA_ "GenSigCycleTimeActive" SG_ 2432640832 ReverseWarning_rqst_ISig_4 100;
BA_ "GenSigStartValue" SG_ 2432640832 ReverseWarning_rqst_ISig_4 3;
BA_ "GenSigMaxLatency" SG_ 2432640832 ReverseWarning_rqst_ISig_4 26;
BA_ "Platform_VMCU1_Sig" SG_ 2432640832 ReverseWarning_rqst_ISig_4 1;
BA_ "SeToolAncestorID_SIGNAL" SG_ 2432640832 ReverseWarning_rqst_ISig_4 "x0000001D042783B3";
BA_ "SeToolItemID_SIGNAL" SG_ 2432640832 ReverseWarning_rqst_ISig_4 "x0000001D042783B3";
BA_ "SeToolName_SIGNAL" SG_ 2432640832 ReverseWarning_rqst_ISig_4 "ReverseWarning_rqst";
BA_ "SeToolVersion_SIGNAL" SG_ 2432640832 ReverseWarning_rqst_ISig_4 "1";
BA_ "GenSigCycleTime" SG_ 2432640832 BackLightDimming_Status 100;
BA_ "GenSigCycleTimeActive" SG_ 2432640832 BackLightDimming_Status 100;
BA_ "GenSigStartValue" SG_ 2432640832 BackLightDimming_Status 31;
BA_ "Platform_VMCU1_Sig" SG_ 2432640832 BackLightDimming_Status 1;
BA_ "GenSigCycleTime" SG_ 2432640832 BlackPanelMode_ButtonStatus 100;
BA_ "GenSigCycleTimeActive" SG_ 2432640832 BlackPanelMode_ButtonStatus 100;
BA_ "GenSigStartValue" SG_ 2432640832 BlackPanelMode_ButtonStatus 3;
BA_ "Platform_VMCU1_Sig" SG_ 2432640832 BlackPanelMode_ButtonStatus 1;
BA_ "GenSigSendType" SG_ 2432661312 LiftAxle1LiftPositionRequest_UB_ 7;
BA_ "Platform_VMCU1_Sig" SG_ 2432661312 LiftAxle1LiftPositionRequest_UB_ 1;
BA_ "SystemSignalLongSymbol" SG_ 2432661312 LiftAxle1LiftPositionRequest_UB_ "LiftAxle1LiftPositionRequest_UB_ISig_4";
BA_ "GenSigCycleTime" SG_ 2432661312 VIN_rqst_ISig_4 100;
BA_ "GenSigCycleTimeActive" SG_ 2432661312 VIN_rqst_ISig_4 100;
BA_ "Platform_VMCU1_Sig" SG_ 2432661312 VIN_rqst_ISig_4 1;
BA_ "GenSigCycleTime" SG_ 2432661312 FWSelectedSpeedControlMode 100;
BA_ "GenSigCycleTimeActive" SG_ 2432661312 FWSelectedSpeedControlMode 100;
BA_ "GenSigStartValue" SG_ 2432661312 FWSelectedSpeedControlMode 7;
BA_ "Platform_VMCU1_Sig" SG_ 2432661312 FWSelectedSpeedControlMode 1;
BA_ "GenSigCycleTime" SG_ 2432661312 FogLightFront_ButtonStatus_3 100;
BA_ "GenSigCycleTimeActive" SG_ 2432661312 FogLightFront_ButtonStatus_3 100;
BA_ "GenSigStartValue" SG_ 2432661312 FogLightFront_ButtonStatus_3 3;
BA_ "Platform_VMCU1_Sig" SG_ 2432661312 FogLightFront_ButtonStatus_3 1;
BA_ "GenSigCycleTime" SG_ 2432661312 InteriorLightDimming_rqst 100;
BA_ "GenSigCycleTimeActive" SG_ 2432661312 InteriorLightDimming_rqst 100;
BA_ "GenSigStartValue" SG_ 2432661312 InteriorLightDimming_rqst 31;
BA_ "Platform_VMCU1_Sig" SG_ 2432661312 InteriorLightDimming_rqst 1;
BA_ "GenSigCycleTime" SG_ 2432661312 FrAxleDiffLockActvnDriverRqst_IS 100;
BA_ "GenSigCycleTimeActive" SG_ 2432661312 FrAxleDiffLockActvnDriverRqst_IS 100;
BA_ "GenSigStartValue" SG_ 2432661312 FrAxleDiffLockActvnDriverRqst_IS 3;
BA_ "GenSigMaxLatency" SG_ 2432661312 FrAxleDiffLockActvnDriverRqst_IS 28;
BA_ "NeedsUpdateBit" SG_ 2432661312 FrAxleDiffLockActvnDriverRqst_IS 1;
BA_ "Platform_VMCU1_Sig" SG_ 2432661312 FrAxleDiffLockActvnDriverRqst_IS 1;
BA_ "SystemSignalLongSymbol" SG_ 2432661312 FrAxleDiffLockActvnDriverRqst_IS "FrAxleDiffLockActvnDriverRqst_ISig_4";
BA_ "GenSigCycleTime" SG_ 2432661312 AdjustFrontBeamInclination 100;
BA_ "GenSigCycleTimeActive" SG_ 2432661312 AdjustFrontBeamInclination 100;
BA_ "GenSigStartValue" SG_ 2432661312 AdjustFrontBeamInclination 7;
BA_ "Platform_VMCU1_Sig" SG_ 2432661312 AdjustFrontBeamInclination 1;
BA_ "GenSigSendType" SG_ 2432661312 LiftAxle2LiftPositionRequest_UB_ 7;
BA_ "Platform_VMCU1_Sig" SG_ 2432661312 LiftAxle2LiftPositionRequest_UB_ 1;
BA_ "SystemSignalLongSymbol" SG_ 2432661312 LiftAxle2LiftPositionRequest_UB_ "LiftAxle2LiftPositionRequest_UB_ISig_4";
BA_ "GenSigCycleTime" SG_ 2432661312 LiftAxle2AutoLiftRequest_ISig_4 100;
BA_ "GenSigCycleTimeActive" SG_ 2432661312 LiftAxle2AutoLiftRequest_ISig_4 100;
BA_ "GenSigStartValue" SG_ 2432661312 LiftAxle2AutoLiftRequest_ISig_4 3;
BA_ "GenSigMaxLatency" SG_ 2432661312 LiftAxle2AutoLiftRequest_ISig_4 28;
BA_ "NeedsUpdateBit" SG_ 2432661312 LiftAxle2AutoLiftRequest_ISig_4 1;
BA_ "Platform_VMCU1_Sig" SG_ 2432661312 LiftAxle2AutoLiftRequest_ISig_4 1;
BA_ "SeToolAncestorID_SIGNAL" SG_ 2432661312 LiftAxle2AutoLiftRequest_ISig_4 "x0000001D0417683F";
BA_ "SeToolItemID_SIGNAL" SG_ 2432661312 LiftAxle2AutoLiftRequest_ISig_4 "x0000001D0417683F";
BA_ "SeToolName_SIGNAL" SG_ 2432661312 LiftAxle2AutoLiftRequest_ISig_4 "LiftAxle2AutoLiftRequest";
BA_ "SeToolVersion_SIGNAL" SG_ 2432661312 LiftAxle2AutoLiftRequest_ISig_4 "1";
BA_ "GenSigSendType" SG_ 2432661312 LiftAxle2AutoLiftRequest_UB_ISig 7;
BA_ "Platform_VMCU1_Sig" SG_ 2432661312 LiftAxle2AutoLiftRequest_UB_ISig 1;
BA_ "SystemSignalLongSymbol" SG_ 2432661312 LiftAxle2AutoLiftRequest_UB_ISig "LiftAxle2AutoLiftRequest_UB_ISig_4";
BA_ "GenSigCycleTime" SG_ 2432661312 AltLoadDistribution_rqst_ISig_4 100;
BA_ "GenSigCycleTimeActive" SG_ 2432661312 AltLoadDistribution_rqst_ISig_4 100;
BA_ "GenSigStartValue" SG_ 2432661312 AltLoadDistribution_rqst_ISig_4 7;
BA_ "GenSigMaxLatency" SG_ 2432661312 AltLoadDistribution_rqst_ISig_4 28;
BA_ "NeedsUpdateBit" SG_ 2432661312 AltLoadDistribution_rqst_ISig_4 1;
BA_ "Platform_VMCU1_Sig" SG_ 2432661312 AltLoadDistribution_rqst_ISig_4 1;
BA_ "SeToolAncestorID_SIGNAL" SG_ 2432661312 AltLoadDistribution_rqst_ISig_4 "x0000001D04189EA3";
BA_ "SeToolItemID_SIGNAL" SG_ 2432661312 AltLoadDistribution_rqst_ISig_4 "x0000001D04189EA3";
BA_ "SeToolName_SIGNAL" SG_ 2432661312 AltLoadDistribution_rqst_ISig_4 "AlternativeLoadDistributionRequest";
BA_ "SeToolVersion_SIGNAL" SG_ 2432661312 AltLoadDistribution_rqst_ISig_4 "1";
BA_ "GenSigCycleTime" SG_ 2432661312 FogLightRear_ButtonStatus_3 100;
BA_ "GenSigCycleTimeActive" SG_ 2432661312 FogLightRear_ButtonStatus_3 100;
BA_ "GenSigStartValue" SG_ 2432661312 FogLightRear_ButtonStatus_3 3;
BA_ "Platform_VMCU1_Sig" SG_ 2432661312 FogLightRear_ButtonStatus_3 1;
BA_ "GenSigSendType" SG_ 2432661312 LoadDistributionChangeRequest_UB 7;
BA_ "Platform_VMCU1_Sig" SG_ 2432661312 LoadDistributionChangeRequest_UB 1;
BA_ "SystemSignalLongSymbol" SG_ 2432661312 LoadDistributionChangeRequest_UB "LoadDistributionChangeRequest_UB_ISig_4";
BA_ "GenSigCycleTime" SG_ 2432661312 LiftAxle2LiftPositionRequest_ISi 100;
BA_ "GenSigCycleTimeActive" SG_ 2432661312 LiftAxle2LiftPositionRequest_ISi 100;
BA_ "GenSigStartValue" SG_ 2432661312 LiftAxle2LiftPositionRequest_ISi 7;
BA_ "GenSigMaxLatency" SG_ 2432661312 LiftAxle2LiftPositionRequest_ISi 28;
BA_ "NeedsUpdateBit" SG_ 2432661312 LiftAxle2LiftPositionRequest_ISi 1;
BA_ "Platform_VMCU1_Sig" SG_ 2432661312 LiftAxle2LiftPositionRequest_ISi 1;
BA_ "SeToolAncestorID_SIGNAL" SG_ 2432661312 LiftAxle2LiftPositionRequest_ISi "x0000001D0417683A";
BA_ "SeToolItemID_SIGNAL" SG_ 2432661312 LiftAxle2LiftPositionRequest_ISi "x0000001D0417683A";
BA_ "SeToolName_SIGNAL" SG_ 2432661312 LiftAxle2LiftPositionRequest_ISi "LiftAxle2LiftPositionRequest";
BA_ "SeToolVersion_SIGNAL" SG_ 2432661312 LiftAxle2LiftPositionRequest_ISi "1";
BA_ "SystemSignalLongSymbol" SG_ 2432661312 LiftAxle2LiftPositionRequest_ISi "LiftAxle2LiftPositionRequest_ISig_4";
BA_ "GenSigSendType" SG_ 2432661312 AltLoadDistribution_rqst_UB_ISig 7;
BA_ "Platform_VMCU1_Sig" SG_ 2432661312 AltLoadDistribution_rqst_UB_ISig 1;
BA_ "SystemSignalLongSymbol" SG_ 2432661312 AltLoadDistribution_rqst_UB_ISig "AltLoadDistribution_rqst_UB_ISig_4";
BA_ "GenSigCycleTime" SG_ 2432661312 TrailerBodyLamp_rqst 100;
BA_ "GenSigCycleTimeActive" SG_ 2432661312 TrailerBodyLamp_rqst 100;
BA_ "GenSigStartValue" SG_ 2432661312 TrailerBodyLamp_rqst 3;
BA_ "Platform_VMCU1_Sig" SG_ 2432661312 TrailerBodyLamp_rqst 1;
BA_ "GenSigSendType" SG_ 2432661312 LiftAxle1AutoLiftRequest_UB_ISig 7;
BA_ "Platform_VMCU1_Sig" SG_ 2432661312 LiftAxle1AutoLiftRequest_UB_ISig 1;
BA_ "SystemSignalLongSymbol" SG_ 2432661312 LiftAxle1AutoLiftRequest_UB_ISig "LiftAxle1AutoLiftRequest_UB_ISig_4";
BA_ "GenSigCycleTime" SG_ 2432661312 LoadDistributionChangeRequest_IS 100;
BA_ "GenSigCycleTimeActive" SG_ 2432661312 LoadDistributionChangeRequest_IS 100;
BA_ "GenSigStartValue" SG_ 2432661312 LoadDistributionChangeRequest_IS 3;
BA_ "GenSigMaxLatency" SG_ 2432661312 LoadDistributionChangeRequest_IS 28;
BA_ "NeedsUpdateBit" SG_ 2432661312 LoadDistributionChangeRequest_IS 1;
BA_ "Platform_VMCU1_Sig" SG_ 2432661312 LoadDistributionChangeRequest_IS 1;
BA_ "SeToolAncestorID_SIGNAL" SG_ 2432661312 LoadDistributionChangeRequest_IS "x0000001D04176D2B";
BA_ "SeToolItemID_SIGNAL" SG_ 2432661312 LoadDistributionChangeRequest_IS "x0000001D04176D2B";
BA_ "SeToolName_SIGNAL" SG_ 2432661312 LoadDistributionChangeRequest_IS "LoadDistributionChangeRequest";
BA_ "SeToolVersion_SIGNAL" SG_ 2432661312 LoadDistributionChangeRequest_IS "1";
BA_ "SystemSignalLongSymbol" SG_ 2432661312 LoadDistributionChangeRequest_IS "LoadDistributionChangeRequest_ISig_4";
BA_ "GenSigCycleTime" SG_ 2432661312 LiftAxle1AutoLiftRequest_ISig_4 100;
BA_ "GenSigCycleTimeActive" SG_ 2432661312 LiftAxle1AutoLiftRequest_ISig_4 100;
BA_ "GenSigStartValue" SG_ 2432661312 LiftAxle1AutoLiftRequest_ISig_4 3;
BA_ "GenSigMaxLatency" SG_ 2432661312 LiftAxle1AutoLiftRequest_ISig_4 28;
BA_ "NeedsUpdateBit" SG_ 2432661312 LiftAxle1AutoLiftRequest_ISig_4 1;
BA_ "Platform_VMCU1_Sig" SG_ 2432661312 LiftAxle1AutoLiftRequest_ISig_4 1;
BA_ "SeToolAncestorID_SIGNAL" SG_ 2432661312 LiftAxle1AutoLiftRequest_ISig_4 "x0000001D0417688D";
BA_ "SeToolItemID_SIGNAL" SG_ 2432661312 LiftAxle1AutoLiftRequest_ISig_4 "x0000001D0417688D";
BA_ "SeToolName_SIGNAL" SG_ 2432661312 LiftAxle1AutoLiftRequest_ISig_4 "LiftAxle1AutoLiftRequest";
BA_ "SeToolVersion_SIGNAL" SG_ 2432661312 LiftAxle1AutoLiftRequest_ISig_4 "1";
BA_ "GenSigCycleTime" SG_ 2432661312 LiftAxle1LiftPositionRequest_ISi 100;
BA_ "GenSigCycleTimeActive" SG_ 2432661312 LiftAxle1LiftPositionRequest_ISi 100;
BA_ "GenSigStartValue" SG_ 2432661312 LiftAxle1LiftPositionRequest_ISi 7;
BA_ "GenSigMaxLatency" SG_ 2432661312 LiftAxle1LiftPositionRequest_ISi 28;
BA_ "NeedsUpdateBit" SG_ 2432661312 LiftAxle1LiftPositionRequest_ISi 1;
BA_ "Platform_VMCU1_Sig" SG_ 2432661312 LiftAxle1LiftPositionRequest_ISi 1;
BA_ "SeToolAncestorID_SIGNAL" SG_ 2432661312 LiftAxle1LiftPositionRequest_ISi "x0000001D04176891";
BA_ "SeToolItemID_SIGNAL" SG_ 2432661312 LiftAxle1LiftPositionRequest_ISi "x0000001D04176891";
BA_ "SeToolName_SIGNAL" SG_ 2432661312 LiftAxle1LiftPositionRequest_ISi "LiftAxle1LiftPositionRequest";
BA_ "SeToolVersion_SIGNAL" SG_ 2432661312 LiftAxle1LiftPositionRequest_ISi "1";
BA_ "SystemSignalLongSymbol" SG_ 2432661312 LiftAxle1LiftPositionRequest_ISi "LiftAxle1LiftPositionRequest_ISig_4";
BA_ "GenSigSendType" SG_ 2432661312 FrAxleDiffLockActvnDriverRqst_UB 7;
BA_ "Platform_VMCU1_Sig" SG_ 2432661312 FrAxleDiffLockActvnDriverRqst_UB 1;
BA_ "SystemSignalLongSymbol" SG_ 2432661312 FrAxleDiffLockActvnDriverRqst_UB "FrAxleDiffLockActvnDriverRqst_UB_ISig_4";
BA_ "GenSigCycleTime" SG_ 1355 BBPeriodicLog1Status_ISig_4 100;
BA_ "GenSigCycleTimeActive" SG_ 1355 BBPeriodicLog1Status_ISig_4 100;
BA_ "GenSigStartValue" SG_ 1355 BBPeriodicLog1Status_ISig_4 3;
BA_ "GenSigMaxLatency" SG_ 1355 BBPeriodicLog1Status_ISig_4 995;
BA_ "GenSigCycleTime" SG_ 1355 BBPeriodicLog4Status_ISig_4 100;
BA_ "GenSigCycleTimeActive" SG_ 1355 BBPeriodicLog4Status_ISig_4 100;
BA_ "GenSigStartValue" SG_ 1355 BBPeriodicLog4Status_ISig_4 3;
BA_ "GenSigMaxLatency" SG_ 1355 BBPeriodicLog4Status_ISig_4 995;
BA_ "GenSigCycleTime" SG_ 1355 BBEventLog4Status_ISig_4 100;
BA_ "GenSigCycleTimeActive" SG_ 1355 BBEventLog4Status_ISig_4 100;
BA_ "GenSigStartValue" SG_ 1355 BBEventLog4Status_ISig_4 3;
BA_ "GenSigMaxLatency" SG_ 1355 BBEventLog4Status_ISig_4 995;
BA_ "GenSigCycleTime" SG_ 1355 BBEventLog1Status_ISig_4 100;
BA_ "GenSigCycleTimeActive" SG_ 1355 BBEventLog1Status_ISig_4 100;
BA_ "GenSigStartValue" SG_ 1355 BBEventLog1Status_ISig_4 3;
BA_ "GenSigMaxLatency" SG_ 1355 BBEventLog1Status_ISig_4 995;
BA_ "GenSigCycleTime" SG_ 1355 BBEventLog7Status_ISig_4 100;
BA_ "GenSigCycleTimeActive" SG_ 1355 BBEventLog7Status_ISig_4 100;
BA_ "GenSigStartValue" SG_ 1355 BBEventLog7Status_ISig_4 3;
BA_ "GenSigMaxLatency" SG_ 1355 BBEventLog7Status_ISig_4 995;
BA_ "GenSigCycleTime" SG_ 1355 BBEventLog10Status_ISig_4 100;
BA_ "GenSigCycleTimeActive" SG_ 1355 BBEventLog10Status_ISig_4 100;
BA_ "GenSigStartValue" SG_ 1355 BBEventLog10Status_ISig_4 3;
BA_ "GenSigMaxLatency" SG_ 1355 BBEventLog10Status_ISig_4 995;
BA_ "GenSigCycleTime" SG_ 1355 BBRollingBufferLogStatus_ISig_4 100;
BA_ "GenSigCycleTimeActive" SG_ 1355 BBRollingBufferLogStatus_ISig_4 100;
BA_ "GenSigStartValue" SG_ 1355 BBRollingBufferLogStatus_ISig_4 3;
BA_ "GenSigMaxLatency" SG_ 1355 BBRollingBufferLogStatus_ISig_4 995;
BA_ "GenSigCycleTime" SG_ 1355 BBPeriodicLog2Status_ISig_4 100;
BA_ "GenSigCycleTimeActive" SG_ 1355 BBPeriodicLog2Status_ISig_4 100;
BA_ "GenSigStartValue" SG_ 1355 BBPeriodicLog2Status_ISig_4 3;
BA_ "GenSigMaxLatency" SG_ 1355 BBPeriodicLog2Status_ISig_4 995;
BA_ "GenSigCycleTime" SG_ 1355 BBEventLog6Status_ISig_4 100;
BA_ "GenSigCycleTimeActive" SG_ 1355 BBEventLog6Status_ISig_4 100;
BA_ "GenSigStartValue" SG_ 1355 BBEventLog6Status_ISig_4 3;
BA_ "GenSigMaxLatency" SG_ 1355 BBEventLog6Status_ISig_4 995;
BA_ "GenSigCycleTime" SG_ 1355 BBEventLog9Status_ISig_4 100;
BA_ "GenSigCycleTimeActive" SG_ 1355 BBEventLog9Status_ISig_4 100;
BA_ "GenSigStartValue" SG_ 1355 BBEventLog9Status_ISig_4 3;
BA_ "GenSigMaxLatency" SG_ 1355 BBEventLog9Status_ISig_4 995;
BA_ "GenSigCycleTime" SG_ 1355 BBFlexibleLoggingActive 100;
BA_ "GenSigCycleTimeActive" SG_ 1355 BBFlexibleLoggingActive 100;
BA_ "GenSigStartValue" SG_ 1355 BBFlexibleLoggingActive 3;
BA_ "GenSigMaxLatency" SG_ 1355 BBFlexibleLoggingActive 995;
BA_ "GenSigCycleTime" SG_ 1355 BBEventLog5Status_ISig_4 100;
BA_ "GenSigCycleTimeActive" SG_ 1355 BBEventLog5Status_ISig_4 100;
BA_ "GenSigStartValue" SG_ 1355 BBEventLog5Status_ISig_4 3;
BA_ "GenSigMaxLatency" SG_ 1355 BBEventLog5Status_ISig_4 995;
BA_ "GenSigCycleTime" SG_ 1355 BBPeriodicLog3Status_ISig_4 100;
BA_ "GenSigCycleTimeActive" SG_ 1355 BBPeriodicLog3Status_ISig_4 100;
BA_ "GenSigStartValue" SG_ 1355 BBPeriodicLog3Status_ISig_4 3;
BA_ "GenSigMaxLatency" SG_ 1355 BBPeriodicLog3Status_ISig_4 995;
BA_ "GenSigCycleTime" SG_ 1355 BBEventLog3Status_ISig_4 100;
BA_ "GenSigCycleTimeActive" SG_ 1355 BBEventLog3Status_ISig_4 100;
BA_ "GenSigStartValue" SG_ 1355 BBEventLog3Status_ISig_4 3;
BA_ "GenSigMaxLatency" SG_ 1355 BBEventLog3Status_ISig_4 995;
BA_ "GenSigCycleTime" SG_ 1355 BBEventLog2Status_ISig_4 100;
BA_ "GenSigCycleTimeActive" SG_ 1355 BBEventLog2Status_ISig_4 100;
BA_ "GenSigStartValue" SG_ 1355 BBEventLog2Status_ISig_4 3;
BA_ "GenSigMaxLatency" SG_ 1355 BBEventLog2Status_ISig_4 995;
BA_ "GenSigCycleTime" SG_ 1355 BBEventLog8Status_ISig_4 100;
BA_ "GenSigCycleTimeActive" SG_ 1355 BBEventLog8Status_ISig_4 100;
BA_ "GenSigStartValue" SG_ 1355 BBEventLog8Status_ISig_4 3;
BA_ "GenSigMaxLatency" SG_ 1355 BBEventLog8Status_ISig_4 995;
BA_ "GenSigCycleTime" SG_ 2365554662 RSBBM_BBSystemChecksum 100;
BA_ "GenSigCycleTimeActive" SG_ 2365554662 RSBBM_BBSystemChecksum 100;
BA_ "GenSigStartValue" SG_ 2365554662 RSBBM_BBSystemChecksum 15;
BA_ "GenSigCycleTime" SG_ 2365554662 RSBBM_BBSystemFASReqControlMode 100;
BA_ "GenSigCycleTimeActive" SG_ 2365554662 RSBBM_BBSystemFASReqControlMode 100;
BA_ "GenSigStartValue" SG_ 2365554662 RSBBM_BBSystemFASReqControlMode 7;
BA_ "GenSigCycleTime" SG_ 2365554662 RSBBM_BBSystemCounter 100;
BA_ "GenSigCycleTimeActive" SG_ 2365554662 RSBBM_BBSystemCounter 100;
BA_ "GenSigStartValue" SG_ 2365554662 RSBBM_BBSystemCounter 15;
BA_ "GenSigCycleTime" SG_ 2365554662 RSBBM_BBSystemFASAngleRequest 100;
BA_ "GenSigCycleTimeActive" SG_ 2365554662 RSBBM_BBSystemFASAngleRequest 100;
BA_ "GenSigStartValue" SG_ 2365554662 RSBBM_BBSystemFASAngleRequest 65535;
BA_ "GenSigCycleTime" SG_ 955 FdDiagStatus4_ISig_4 100;
BA_ "GenSigCycleTimeActive" SG_ 955 FdDiagStatus4_ISig_4 100;
BA_ "GenSigStartValue" SG_ 955 FdDiagStatus4_ISig_4 3;
BA_ "GenSigMaxLatency" SG_ 955 FdDiagStatus4_ISig_4 61;
BA_ "GenSigCycleTime" SG_ 955 FdDiagStatus2_ISig_4 100;
BA_ "GenSigCycleTimeActive" SG_ 955 FdDiagStatus2_ISig_4 100;
BA_ "GenSigStartValue" SG_ 955 FdDiagStatus2_ISig_4 3;
BA_ "GenSigMaxLatency" SG_ 955 FdDiagStatus2_ISig_4 61;
BA_ "GenSigCycleTime" SG_ 955 FdDiagStatus8_ISig_4 100;
BA_ "GenSigCycleTimeActive" SG_ 955 FdDiagStatus8_ISig_4 100;
BA_ "GenSigStartValue" SG_ 955 FdDiagStatus8_ISig_4 3;
BA_ "GenSigMaxLatency" SG_ 955 FdDiagStatus8_ISig_4 61;
BA_ "GenSigCycleTime" SG_ 955 FdDiagStatus10_ISig_4 100;
BA_ "GenSigCycleTimeActive" SG_ 955 FdDiagStatus10_ISig_4 100;
BA_ "GenSigStartValue" SG_ 955 FdDiagStatus10_ISig_4 3;
BA_ "GenSigMaxLatency" SG_ 955 FdDiagStatus10_ISig_4 61;
BA_ "GenSigCycleTime" SG_ 955 FdDiagStatus6_ISig_4 100;
BA_ "GenSigCycleTimeActive" SG_ 955 FdDiagStatus6_ISig_4 100;
BA_ "GenSigStartValue" SG_ 955 FdDiagStatus6_ISig_4 3;
BA_ "GenSigMaxLatency" SG_ 955 FdDiagStatus6_ISig_4 61;
BA_ "GenSigCycleTime" SG_ 955 FdDiagStatus9_ISig_4 100;
BA_ "GenSigCycleTimeActive" SG_ 955 FdDiagStatus9_ISig_4 100;
BA_ "GenSigStartValue" SG_ 955 FdDiagStatus9_ISig_4 3;
BA_ "GenSigMaxLatency" SG_ 955 FdDiagStatus9_ISig_4 61;
BA_ "GenSigCycleTime" SG_ 955 FdDiagStatus5_ISig_4 100;
BA_ "GenSigCycleTimeActive" SG_ 955 FdDiagStatus5_ISig_4 100;
BA_ "GenSigStartValue" SG_ 955 FdDiagStatus5_ISig_4 3;
BA_ "GenSigMaxLatency" SG_ 955 FdDiagStatus5_ISig_4 61;
BA_ "GenSigCycleTime" SG_ 955 FdDiagStatus7_ISig_4 100;
BA_ "GenSigCycleTimeActive" SG_ 955 FdDiagStatus7_ISig_4 100;
BA_ "GenSigStartValue" SG_ 955 FdDiagStatus7_ISig_4 3;
BA_ "GenSigMaxLatency" SG_ 955 FdDiagStatus7_ISig_4 61;
BA_ "GenSigCycleTime" SG_ 955 FdDiagStatus1_ISig_4 100;
BA_ "GenSigCycleTimeActive" SG_ 955 FdDiagStatus1_ISig_4 100;
BA_ "GenSigStartValue" SG_ 955 FdDiagStatus1_ISig_4 3;
BA_ "GenSigMaxLatency" SG_ 955 FdDiagStatus1_ISig_4 61;
BA_ "GenSigCycleTime" SG_ 955 FdDiagStatus3_ISig_4 100;
BA_ "GenSigCycleTimeActive" SG_ 955 FdDiagStatus3_ISig_4 100;
BA_ "GenSigStartValue" SG_ 955 FdDiagStatus3_ISig_4 3;
BA_ "GenSigMaxLatency" SG_ 955 FdDiagStatus3_ISig_4 61;
BA_ "GenSigCycleTime" SG_ 2550057702 RFBEngineStopAllowed 100;
BA_ "GenSigCycleTimeActive" SG_ 2550057702 RFBEngineStopAllowed 100;
BA_ "GenSigStartValue" SG_ 2550057702 RFBEngineStopAllowed 3;
BA_ "Platform_VMCU1_Sig" SG_ 2550057702 RFBEngineStopAllowed 1;
BA_ "GenSigCycleTime" SG_ 2550057702 PreTSC1BsTr_EnOvrdCtrlM 100;
BA_ "GenSigCycleTimeActive" SG_ 2550057702 PreTSC1BsTr_EnOvrdCtrlM 100;
BA_ "Platform_VMCU1_Sig" SG_ 2550057702 PreTSC1BsTr_EnOvrdCtrlM 1;
BA_ "GenSigCycleTime" SG_ 2550057702 BrakeAndPark_ind 100;
BA_ "GenSigCycleTimeActive" SG_ 2550057702 BrakeAndPark_ind 100;
BA_ "GenSigStartValue" SG_ 2550057702 BrakeAndPark_ind 7;
BA_ "Platform_VMCU1_Sig" SG_ 2550057702 BrakeAndPark_ind 1;
BA_ "GenSigCycleTime" SG_ 2550057702 PreTSC1BsTr_EnRTrqTrqLm 100;
BA_ "GenSigCycleTimeActive" SG_ 2550057702 PreTSC1BsTr_EnRTrqTrqLm 100;
BA_ "GenSigStartValue" SG_ 2550057702 PreTSC1BsTr_EnRTrqTrqLm 255;
BA_ "Platform_VMCU1_Sig" SG_ 2550057702 PreTSC1BsTr_EnRTrqTrqLm 1;
BA_ "GenSigCycleTime" SG_ 2550057702 VehicleImmobilization_ind 100;
BA_ "GenSigCycleTimeActive" SG_ 2550057702 VehicleImmobilization_ind 100;
BA_ "GenSigStartValue" SG_ 2550057702 VehicleImmobilization_ind 3;
BA_ "Platform_VMCU1_Sig" SG_ 2550057702 VehicleImmobilization_ind 1;
BA_ "GenSigCycleTime" SG_ 2550057702 FullBrakes_ind_ISig_4 100;
BA_ "GenSigCycleTimeActive" SG_ 2550057702 FullBrakes_ind_ISig_4 100;
BA_ "GenSigStartValue" SG_ 2550057702 FullBrakes_ind_ISig_4 3;
BA_ "Platform_VMCU1_Sig" SG_ 2550057702 FullBrakes_ind_ISig_4 1;
BA_ "GenSigCycleTime" SG_ 2550057702 PtoTorqueRequest 100;
BA_ "GenSigCycleTimeActive" SG_ 2550057702 PtoTorqueRequest 100;
BA_ "GenSigStartValue" SG_ 2550057702 PtoTorqueRequest 3;
BA_ "Platform_VMCU1_Sig" SG_ 2550057702 PtoTorqueRequest 1;
BA_ "GenSigCycleTime" SG_ 2481984998 TipperConditionsStatus_ISig_4 100;
BA_ "GenSigCycleTimeActive" SG_ 2481984998 TipperConditionsStatus_ISig_4 100;
BA_ "GenSigStartValue" SG_ 2481984998 TipperConditionsStatus_ISig_4 3;
BA_ "Platform_VMCU1_Sig" SG_ 2481984998 TipperConditionsStatus_ISig_4 1;
BA_ "GenSigCycleTime" SG_ 2481984998 TailLiftRemoteNotAllowed_ISig_4 100;
BA_ "GenSigCycleTimeActive" SG_ 2481984998 TailLiftRemoteNotAllowed_ISig_4 100;
BA_ "GenSigStartValue" SG_ 2481984998 TailLiftRemoteNotAllowed_ISig_4 3;
BA_ "Platform_VMCU1_Sig" SG_ 2481984998 TailLiftRemoteNotAllowed_ISig_4 1;
BA_ "GenSigCycleTime" SG_ 2481984998 TipperTarpaulinStatus_ISig_4 100;
BA_ "GenSigCycleTimeActive" SG_ 2481984998 TipperTarpaulinStatus_ISig_4 100;
BA_ "GenSigStartValue" SG_ 2481984998 TipperTarpaulinStatus_ISig_4 7;
BA_ "Platform_VMCU1_Sig" SG_ 2481984998 TipperTarpaulinStatus_ISig_4 1;
BA_ "GenSigSendType" SG_ 2481984998 CTA_PBReleaseInhibit_rqst_UB 7;
BA_ "Platform_VMCU1_Sig" SG_ 2481984998 CTA_PBReleaseInhibit_rqst_UB 1;
BA_ "GenSigCycleTime" SG_ 2481984998 TipperAutoLowering 100;
BA_ "GenSigCycleTimeActive" SG_ 2481984998 TipperAutoLowering 100;
BA_ "GenSigStartValue" SG_ 2481984998 TipperAutoLowering 3;
BA_ "Platform_VMCU1_Sig" SG_ 2481984998 TipperAutoLowering 1;
BA_ "GenSigCycleTime" SG_ 2481984998 DirInd_Plough_Status 100;
BA_ "GenSigCycleTimeActive" SG_ 2481984998 DirInd_Plough_Status 100;
BA_ "GenSigStartValue" SG_ 2481984998 DirInd_Plough_Status 7;
BA_ "Platform_VMCU1_Sig" SG_ 2481984998 DirInd_Plough_Status 1;
BA_ "GenSigCycleTime" SG_ 2481984998 TipperShakerStatus_ISig_4 100;
BA_ "GenSigCycleTimeActive" SG_ 2481984998 TipperShakerStatus_ISig_4 100;
BA_ "GenSigStartValue" SG_ 2481984998 TipperShakerStatus_ISig_4 3;
BA_ "Platform_VMCU1_Sig" SG_ 2481984998 TipperShakerStatus_ISig_4 1;
BA_ "GenSigCycleTime" SG_ 2481984998 TipperEmergencyStopStatus_ISig_4 100;
BA_ "GenSigCycleTimeActive" SG_ 2481984998 TipperEmergencyStopStatus_ISig_4 100;
BA_ "GenSigStartValue" SG_ 2481984998 TipperEmergencyStopStatus_ISig_4 7;
BA_ "Platform_VMCU1_Sig" SG_ 2481984998 TipperEmergencyStopStatus_ISig_4 1;
BA_ "GenSigCycleTime" SG_ 2481984998 TipperSecondaryBodyStatus_ISig_4 100;
BA_ "GenSigCycleTimeActive" SG_ 2481984998 TipperSecondaryBodyStatus_ISig_4 100;
BA_ "GenSigStartValue" SG_ 2481984998 TipperSecondaryBodyStatus_ISig_4 7;
BA_ "Platform_VMCU1_Sig" SG_ 2481984998 TipperSecondaryBodyStatus_ISig_4 1;
BA_ "GenSigCycleTime" SG_ 2481984998 TipperPrimaryBodyStatus_ISig_4 100;
BA_ "GenSigCycleTimeActive" SG_ 2481984998 TipperPrimaryBodyStatus_ISig_4 100;
BA_ "GenSigStartValue" SG_ 2481984998 TipperPrimaryBodyStatus_ISig_4 7;
BA_ "Platform_VMCU1_Sig" SG_ 2481984998 TipperPrimaryBodyStatus_ISig_4 1;
BA_ "GenSigCycleTime" SG_ 2481984998 AuxSwitchBbLoad5Feedback 100;
BA_ "GenSigCycleTimeActive" SG_ 2481984998 AuxSwitchBbLoad5Feedback 100;
BA_ "GenSigStartValue" SG_ 2481984998 AuxSwitchBbLoad5Feedback 7;
BA_ "Platform_VMCU1_Sig" SG_ 2481984998 AuxSwitchBbLoad5Feedback 1;
BA_ "GenSigCycleTime" SG_ 2481984998 AuxSwitchBbLoad3Feedback 100;
BA_ "GenSigCycleTimeActive" SG_ 2481984998 AuxSwitchBbLoad3Feedback 100;
BA_ "GenSigStartValue" SG_ 2481984998 AuxSwitchBbLoad3Feedback 7;
BA_ "Platform_VMCU1_Sig" SG_ 2481984998 AuxSwitchBbLoad3Feedback 1;
BA_ "GenSigCycleTime" SG_ 2481984998 TailLiftMotionStatus_ISig_4 100;
BA_ "GenSigCycleTimeActive" SG_ 2481984998 TailLiftMotionStatus_ISig_4 100;
BA_ "GenSigStartValue" SG_ 2481984998 TailLiftMotionStatus_ISig_4 7;
BA_ "Platform_VMCU1_Sig" SG_ 2481984998 TailLiftMotionStatus_ISig_4 1;
BA_ "GenSigCycleTime" SG_ 2481984998 AuxSwitchBbLoad4Feedback 100;
BA_ "GenSigCycleTimeActive" SG_ 2481984998 AuxSwitchBbLoad4Feedback 100;
BA_ "GenSigStartValue" SG_ 2481984998 AuxSwitchBbLoad4Feedback 7;
BA_ "Platform_VMCU1_Sig" SG_ 2481984998 AuxSwitchBbLoad4Feedback 1;
BA_ "GenSigCycleTime" SG_ 2481984998 TipperUpDownStatus_ISig_4 100;
BA_ "GenSigCycleTimeActive" SG_ 2481984998 TipperUpDownStatus_ISig_4 100;
BA_ "GenSigStartValue" SG_ 2481984998 TipperUpDownStatus_ISig_4 7;
BA_ "Platform_VMCU1_Sig" SG_ 2481984998 TipperUpDownStatus_ISig_4 1;
BA_ "GenSigCycleTime" SG_ 2481984998 TailLiftConditionsStatus_ISig_4 100;
BA_ "GenSigCycleTimeActive" SG_ 2481984998 TailLiftConditionsStatus_ISig_4 100;
BA_ "GenSigStartValue" SG_ 2481984998 TailLiftConditionsStatus_ISig_4 3;
BA_ "Platform_VMCU1_Sig" SG_ 2481984998 TailLiftConditionsStatus_ISig_4 1;
BA_ "GenSigCycleTime" SG_ 2481984998 AuxSwitchBbLoad6Feedback 100;
BA_ "GenSigCycleTimeActive" SG_ 2481984998 AuxSwitchBbLoad6Feedback 100;
BA_ "GenSigStartValue" SG_ 2481984998 AuxSwitchBbLoad6Feedback 7;
BA_ "Platform_VMCU1_Sig" SG_ 2481984998 AuxSwitchBbLoad6Feedback 1;
BA_ "GenSigCycleTime" SG_ 2481984998 TipperTailGateStatus_ISig_4 100;
BA_ "GenSigCycleTimeActive" SG_ 2481984998 TipperTailGateStatus_ISig_4 100;
BA_ "GenSigStartValue" SG_ 2481984998 TipperTailGateStatus_ISig_4 7;
BA_ "Platform_VMCU1_Sig" SG_ 2481984998 TipperTailGateStatus_ISig_4 1;
BA_ "GenSigCycleTime" SG_ 2481984998 CTA_PBReleaseInhibit_rqst 100;
BA_ "GenSigCycleTimeActive" SG_ 2481984998 CTA_PBReleaseInhibit_rqst 100;
BA_ "GenSigStartValue" SG_ 2481984998 CTA_PBReleaseInhibit_rqst 3;
BA_ "NeedsUpdateBit" SG_ 2481984998 CTA_PBReleaseInhibit_rqst 1;
BA_ "Platform_VMCU1_Sig" SG_ 2481984998 CTA_PBReleaseInhibit_rqst 1;
BA_ "GenSigSendType" SG_ 2466201830 BBUSecondDriverInterfEnable_UB_I 7;
BA_ "Platform_VMCU1_Sig" SG_ 2466201830 BBUSecondDriverInterfEnable_UB_I 1;
BA_ "SystemSignalLongSymbol" SG_ 2466201830 BBUSecondDriverInterfEnable_UB_I "BBUSecondDriverInterfEnable_UB_ISig_4";
BA_ "GenSigCycleTime" SG_ 2466201830 CtaGcReverseInhibit 100;
BA_ "GenSigCycleTimeActive" SG_ 2466201830 CtaGcReverseInhibit 100;
BA_ "GenSigStartValue" SG_ 2466201830 CtaGcReverseInhibit 3;
BA_ "GenSigMaxLatency" SG_ 2466201830 CtaGcReverseInhibit 29;
BA_ "Platform_VMCU1_Sig" SG_ 2466201830 CtaGcReverseInhibit 1;
BA_ "GenSigSendType" SG_ 2466201830 BBSystemAlternatLoadDistribReq_U 7;
BA_ "Platform_VMCU1_Sig" SG_ 2466201830 BBSystemAlternatLoadDistribReq_U 1;
BA_ "SystemSignalLongSymbol" SG_ 2466201830 BBSystemAlternatLoadDistribReq_U "BBSystemAlternatLoadDistribReq_UB_ISig_4";
BA_ "GenSigCycleTime" SG_ 2466201830 BBSystemProhibitControlRequest_I 100;
BA_ "GenSigCycleTimeActive" SG_ 2466201830 BBSystemProhibitControlRequest_I 100;
BA_ "GenSigStartValue" SG_ 2466201830 BBSystemProhibitControlRequest_I 3;
BA_ "GenSigMaxLatency" SG_ 2466201830 BBSystemProhibitControlRequest_I 29;
BA_ "Platform_VMCU1_Sig" SG_ 2466201830 BBSystemProhibitControlRequest_I 1;
BA_ "SystemSignalLongSymbol" SG_ 2466201830 BBSystemProhibitControlRequest_I "BBSystemProhibitControlRequest_ISig_4";
BA_ "GenSigCycleTime" SG_ 2466201830 BBUSecondDriverInterfEnable_ISig 100;
BA_ "GenSigCycleTimeActive" SG_ 2466201830 BBUSecondDriverInterfEnable_ISig 100;
BA_ "GenSigStartValue" SG_ 2466201830 BBUSecondDriverInterfEnable_ISig 3;
BA_ "NeedsUpdateBit" SG_ 2466201830 BBUSecondDriverInterfEnable_ISig 1;
BA_ "Platform_VMCU1_Sig" SG_ 2466201830 BBUSecondDriverInterfEnable_ISig 1;
BA_ "SystemSignalLongSymbol" SG_ 2466201830 BBUSecondDriverInterfEnable_ISig "BBUSecondDriverInterfEnable_ISig_4";
BA_ "GenSigCycleTime" SG_ 2466201830 SecondDriverInterfEnableInput 100;
BA_ "GenSigCycleTimeActive" SG_ 2466201830 SecondDriverInterfEnableInput 100;
BA_ "GenSigStartValue" SG_ 2466201830 SecondDriverInterfEnableInput 3;
BA_ "GenSigMaxLatency" SG_ 2466201830 SecondDriverInterfEnableInput 29;
BA_ "Platform_VMCU1_Sig" SG_ 2466201830 SecondDriverInterfEnableInput 1;
BA_ "GenSigCycleTime" SG_ 2466201830 XPRRequest_RBS_ISig_4 100;
BA_ "GenSigCycleTimeActive" SG_ 2466201830 XPRRequest_RBS_ISig_4 100;
BA_ "GenSigStartValue" SG_ 2466201830 XPRRequest_RBS_ISig_4 255;
BA_ "Platform_VMCU1_Sig" SG_ 2466201830 XPRRequest_RBS_ISig_4 1;
BA_ "GenSigCycleTime" SG_ 2466201830 CtaGcInhibitGearEngaged 100;
BA_ "GenSigCycleTimeActive" SG_ 2466201830 CtaGcInhibitGearEngaged 100;
BA_ "GenSigStartValue" SG_ 2466201830 CtaGcInhibitGearEngaged 3;
BA_ "GenSigMaxLatency" SG_ 2466201830 CtaGcInhibitGearEngaged 29;
BA_ "Platform_VMCU1_Sig" SG_ 2466201830 CtaGcInhibitGearEngaged 1;
BA_ "GenSigCycleTime" SG_ 2466201830 EscChassisEngineSpdMode4 100;
BA_ "GenSigCycleTimeActive" SG_ 2466201830 EscChassisEngineSpdMode4 100;
BA_ "GenSigStartValue" SG_ 2466201830 EscChassisEngineSpdMode4 3;
BA_ "Platform_VMCU1_Sig" SG_ 2466201830 EscChassisEngineSpdMode4 1;
BA_ "GenSigCycleTime" SG_ 2466201830 SecondAcceleratorPedalPosition 100;
BA_ "GenSigCycleTimeActive" SG_ 2466201830 SecondAcceleratorPedalPosition 100;
BA_ "GenSigStartValue" SG_ 2466201830 SecondAcceleratorPedalPosition 255;
BA_ "GenSigMaxLatency" SG_ 2466201830 SecondAcceleratorPedalPosition 29;
BA_ "Platform_VMCU1_Sig" SG_ 2466201830 SecondAcceleratorPedalPosition 1;
BA_ "GenSigCycleTime" SG_ 2466201830 SecondaryAccelPedalQuality 100;
BA_ "GenSigCycleTimeActive" SG_ 2466201830 SecondaryAccelPedalQuality 100;
BA_ "GenSigStartValue" SG_ 2466201830 SecondaryAccelPedalQuality 3;
BA_ "Platform_VMCU1_Sig" SG_ 2466201830 SecondaryAccelPedalQuality 1;
BA_ "GenSigCycleTime" SG_ 2466201830 BBSystemKneelRequest_ISig_4 100;
BA_ "GenSigCycleTimeActive" SG_ 2466201830 BBSystemKneelRequest_ISig_4 100;
BA_ "GenSigStartValue" SG_ 2466201830 BBSystemKneelRequest_ISig_4 3;
BA_ "GenSigMaxLatency" SG_ 2466201830 BBSystemKneelRequest_ISig_4 29;
BA_ "Platform_VMCU1_Sig" SG_ 2466201830 BBSystemKneelRequest_ISig_4 1;
BA_ "GenSigCycleTime" SG_ 2466201830 BBSystemAlternatLoadDistribReq_I 100;
BA_ "GenSigCycleTimeActive" SG_ 2466201830 BBSystemAlternatLoadDistribReq_I 100;
BA_ "GenSigStartValue" SG_ 2466201830 BBSystemAlternatLoadDistribReq_I 3;
BA_ "GenSigMaxLatency" SG_ 2466201830 BBSystemAlternatLoadDistribReq_I 29;
BA_ "NeedsUpdateBit" SG_ 2466201830 BBSystemAlternatLoadDistribReq_I 1;
BA_ "Platform_VMCU1_Sig" SG_ 2466201830 BBSystemAlternatLoadDistribReq_I 1;
BA_ "SystemSignalLongSymbol" SG_ 2466201830 BBSystemAlternatLoadDistribReq_I "BBSystemAlternatLoadDistribReq_ISig_4";
BA_ "GenSigCycleTime" SG_ 2466201830 EscChassisEngineSpdMode3 100;
BA_ "GenSigCycleTimeActive" SG_ 2466201830 EscChassisEngineSpdMode3 100;
BA_ "GenSigStartValue" SG_ 2466201830 EscChassisEngineSpdMode3 3;
BA_ "Platform_VMCU1_Sig" SG_ 2466201830 EscChassisEngineSpdMode3 1;
BA_ "GenSigCycleTime" SG_ 2466201830 CtaGcSecondGearLeverPosition_ISi 100;
BA_ "GenSigCycleTimeActive" SG_ 2466201830 CtaGcSecondGearLeverPosition_ISi 100;
BA_ "GenSigStartValue" SG_ 2466201830 CtaGcSecondGearLeverPosition_ISi 7;
BA_ "GenSigMaxLatency" SG_ 2466201830 CtaGcSecondGearLeverPosition_ISi 29;
BA_ "Platform_VMCU1_Sig" SG_ 2466201830 CtaGcSecondGearLeverPosition_ISi 1;
BA_ "SystemSignalLongSymbol" SG_ 2466201830 CtaGcSecondGearLeverPosition_ISi "CtaGcSecondGearLeverPosition_ISig_4";
BA_ "GenSigCycleTime" SG_ 2466201830 CtaGcAlternativeGearStarter 100;
BA_ "GenSigCycleTimeActive" SG_ 2466201830 CtaGcAlternativeGearStarter 100;
BA_ "GenSigStartValue" SG_ 2466201830 CtaGcAlternativeGearStarter 3;
BA_ "GenSigMaxLatency" SG_ 2466201830 CtaGcAlternativeGearStarter 29;
BA_ "Platform_VMCU1_Sig" SG_ 2466201830 CtaGcAlternativeGearStarter 1;
BA_ "GenSigCycleTime" SG_ 2466201830 EscChassisEngineSpdMode2 100;
BA_ "GenSigCycleTimeActive" SG_ 2466201830 EscChassisEngineSpdMode2 100;
BA_ "GenSigStartValue" SG_ 2466201830 EscChassisEngineSpdMode2 3;
BA_ "Platform_VMCU1_Sig" SG_ 2466201830 EscChassisEngineSpdMode2 1;
BA_ "GenSigCycleTime" SG_ 2466201830 SecondaryAccelPedalKickDown 100;
BA_ "GenSigCycleTimeActive" SG_ 2466201830 SecondaryAccelPedalKickDown 100;
BA_ "GenSigStartValue" SG_ 2466201830 SecondaryAccelPedalKickDown 3;
BA_ "Platform_VMCU1_Sig" SG_ 2466201830 SecondaryAccelPedalKickDown 1;
BA_ "GenSigCycleTime" SG_ 2466201830 SecondAcceleratorPedalStatus 100;
BA_ "GenSigCycleTimeActive" SG_ 2466201830 SecondAcceleratorPedalStatus 100;
BA_ "GenSigStartValue" SG_ 2466201830 SecondAcceleratorPedalStatus 3;
BA_ "Platform_VMCU1_Sig" SG_ 2466201830 SecondAcceleratorPedalStatus 1;
BA_ "GenSigCycleTime" SG_ 2466201830 GCRemoteEsc_rqst 100;
BA_ "GenSigCycleTimeActive" SG_ 2466201830 GCRemoteEsc_rqst 100;
BA_ "GenSigStartValue" SG_ 2466201830 GCRemoteEsc_rqst 3;
BA_ "GenSigMaxLatency" SG_ 2466201830 GCRemoteEsc_rqst 29;
BA_ "Platform_VMCU1_Sig" SG_ 2466201830 GCRemoteEsc_rqst 1;
BA_ "GenSigCycleTime" SG_ 2466201830 EscChassisEngineSpdMode1 100;
BA_ "GenSigCycleTimeActive" SG_ 2466201830 EscChassisEngineSpdMode1 100;
BA_ "GenSigStartValue" SG_ 2466201830 EscChassisEngineSpdMode1 3;
BA_ "Platform_VMCU1_Sig" SG_ 2466201830 EscChassisEngineSpdMode1 1;
BA_ "GenSigCycleTime" SG_ 2466201830 BBSystemSpeedDepDriveLevelReq_IS 100;
BA_ "GenSigCycleTimeActive" SG_ 2466201830 BBSystemSpeedDepDriveLevelReq_IS 100;
BA_ "GenSigStartValue" SG_ 2466201830 BBSystemSpeedDepDriveLevelReq_IS 3;
BA_ "GenSigMaxLatency" SG_ 2466201830 BBSystemSpeedDepDriveLevelReq_IS 29;
BA_ "Platform_VMCU1_Sig" SG_ 2466201830 BBSystemSpeedDepDriveLevelReq_IS 1;
BA_ "SystemSignalLongSymbol" SG_ 2466201830 BBSystemSpeedDepDriveLevelReq_IS "BBSystemSpeedDepDriveLevelReq_ISig_4";
BA_ "GenSigSendType" SG_ 2549377255 BBM_BB2_03S_FCS_4ea 7;
BA_ "Platform_VMCU1_Sig" SG_ 2549377255 BBM_BB2_03S_FCS_4ea 1;
BA_ "GenSigSendType" SG_ 2549377254 FdEquipmentFreeText_ISig_4_4e7 1;
BA_ "GenSigMaxLatency" SG_ 2549377254 FdEquipmentFreeText_ISig_4_4e7 250;
BA_ "Platform_VMCU1_Sig" SG_ 2549377254 FdEquipmentFreeText_ISig_4_4e7 1;
BA_ "SeToolAncestorID_SIGNAL" SG_ 2549377254 FdEquipmentFreeText_ISig_4_4e7 "x0000001D04171318";
BA_ "SeToolItemID_SIGNAL" SG_ 2549377254 FdEquipmentFreeText_ISig_4_4e7 "x0000001D04171318";
BA_ "SeToolName_SIGNAL" SG_ 2549377254 FdEquipmentFreeText_ISig_4_4e7 "FdEquipmentFreeText";
BA_ "SeToolVersion_SIGNAL" SG_ 2549377254 FdEquipmentFreeText_ISig_4_4e7 "1";
BA_ "GenSigSendType" SG_ 2549377511 BBM_BB2_03S_FCS_4f0 7;
BA_ "Platform_VMCU1_Sig" SG_ 2549377511 BBM_BB2_03S_FCS_4f0 1;
BA_ "GenSigSendType" SG_ 2549377510 FdEquipmentFreeText_ISig_4_4ed 1;
BA_ "GenSigMaxLatency" SG_ 2549377510 FdEquipmentFreeText_ISig_4_4ed 250;
BA_ "Platform_VMCU1_Sig" SG_ 2549377510 FdEquipmentFreeText_ISig_4_4ed 1;
BA_ "SeToolAncestorID_SIGNAL" SG_ 2549377510 FdEquipmentFreeText_ISig_4_4ed "x0000001D04171318";
BA_ "SeToolItemID_SIGNAL" SG_ 2549377510 FdEquipmentFreeText_ISig_4_4ed "x0000001D04171318";
BA_ "SeToolName_SIGNAL" SG_ 2549377510 FdEquipmentFreeText_ISig_4_4ed "FdEquipmentFreeText";
BA_ "SeToolVersion_SIGNAL" SG_ 2549377510 FdEquipmentFreeText_ISig_4_4ed "1";
BA_ "GenSigCycleTime" SG_ 2466239718 RssRemoteStopEngine_rqst 100;
BA_ "GenSigCycleTimeActive" SG_ 2466239718 RssRemoteStopEngine_rqst 100;
BA_ "GenSigStartValue" SG_ 2466239718 RssRemoteStopEngine_rqst 3;
BA_ "Platform_VMCU1_Sig" SG_ 2466239718 RssRemoteStopEngine_rqst 1;
BA_ "GenSigCycleTime" SG_ 2466239718 RSL2requestStatus 100;
BA_ "GenSigCycleTimeActive" SG_ 2466239718 RSL2requestStatus 100;
BA_ "GenSigStartValue" SG_ 2466239718 RSL2requestStatus 3;
BA_ "Platform_VMCU1_Sig" SG_ 2466239718 RSL2requestStatus 1;
BA_ "GenSigCycleTime" SG_ 2466239718 FdEquipmentStatus2_ISig_4 100;
BA_ "GenSigCycleTimeActive" SG_ 2466239718 FdEquipmentStatus2_ISig_4 100;
BA_ "GenSigStartValue" SG_ 2466239718 FdEquipmentStatus2_ISig_4 3;
BA_ "GenSigMaxLatency" SG_ 2466239718 FdEquipmentStatus2_ISig_4 59;
BA_ "Platform_VMCU1_Sig" SG_ 2466239718 FdEquipmentStatus2_ISig_4 1;
BA_ "SeToolAncestorID_SIGNAL" SG_ 2466239718 FdEquipmentStatus2_ISig_4 "x0000001D041709FC";
BA_ "SeToolItemID_SIGNAL" SG_ 2466239718 FdEquipmentStatus2_ISig_4 "x0000001D041709FC";
BA_ "SeToolName_SIGNAL" SG_ 2466239718 FdEquipmentStatus2_ISig_4 "FdEquipmentStatus2";
BA_ "SeToolVersion_SIGNAL" SG_ 2466239718 FdEquipmentStatus2_ISig_4 "1";
BA_ "GenSigCycleTime" SG_ 2466239718 RssRemoteStartEngine_rqst 100;
BA_ "GenSigCycleTimeActive" SG_ 2466239718 RssRemoteStartEngine_rqst 100;
BA_ "GenSigStartValue" SG_ 2466239718 RssRemoteStartEngine_rqst 3;
BA_ "Platform_VMCU1_Sig" SG_ 2466239718 RssRemoteStartEngine_rqst 1;
BA_ "GenSigCycleTime" SG_ 2466239718 BBNetwBeaconLight_stat 100;
BA_ "GenSigCycleTimeActive" SG_ 2466239718 BBNetwBeaconLight_stat 100;
BA_ "GenSigStartValue" SG_ 2466239718 BBNetwBeaconLight_stat 3;
BA_ "Platform_VMCU1_Sig" SG_ 2466239718 BBNetwBeaconLight_stat 1;
BA_ "GenSigCycleTime" SG_ 2466239718 Pto2RemoteRequest 100;
BA_ "GenSigCycleTimeActive" SG_ 2466239718 Pto2RemoteRequest 100;
BA_ "GenSigStartValue" SG_ 2466239718 Pto2RemoteRequest 3;
BA_ "GenSigMaxLatency" SG_ 2466239718 Pto2RemoteRequest 59;
BA_ "Platform_VMCU1_Sig" SG_ 2466239718 Pto2RemoteRequest 1;
BA_ "SeToolAncestorID_SIGNAL" SG_ 2466239718 Pto2RemoteRequest "x0000001D0415378A";
BA_ "SeToolItemID_SIGNAL" SG_ 2466239718 Pto2RemoteRequest "x0000001D0415378A";
BA_ "SeToolName_SIGNAL" SG_ 2466239718 Pto2RemoteRequest "Pto2RemoteRequest";
BA_ "SeToolVersion_SIGNAL" SG_ 2466239718 Pto2RemoteRequest "1";
BA_ "GenSigCycleTime" SG_ 2466239718 FdEquipmentValue1_ISig_4 100;
BA_ "GenSigCycleTimeActive" SG_ 2466239718 FdEquipmentValue1_ISig_4 100;
BA_ "GenSigStartValue" SG_ 2466239718 FdEquipmentValue1_ISig_4 255;
BA_ "GenSigMaxLatency" SG_ 2466239718 FdEquipmentValue1_ISig_4 59;
BA_ "Platform_VMCU1_Sig" SG_ 2466239718 FdEquipmentValue1_ISig_4 1;
BA_ "SeToolAncestorID_SIGNAL" SG_ 2466239718 FdEquipmentValue1_ISig_4 "x0000001D0417123F";
BA_ "SeToolItemID_SIGNAL" SG_ 2466239718 FdEquipmentValue1_ISig_4 "x0000001D0417123F";
BA_ "SeToolName_SIGNAL" SG_ 2466239718 FdEquipmentValue1_ISig_4 "FdEquipmentValue1";
BA_ "SeToolVersion_SIGNAL" SG_ 2466239718 FdEquipmentValue1_ISig_4 "1";
BA_ "GenSigCycleTime" SG_ 2466239718 Pto1RemoteRequest 100;
BA_ "GenSigCycleTimeActive" SG_ 2466239718 Pto1RemoteRequest 100;
BA_ "GenSigStartValue" SG_ 2466239718 Pto1RemoteRequest 3;
BA_ "GenSigMaxLatency" SG_ 2466239718 Pto1RemoteRequest 59;
BA_ "Platform_VMCU1_Sig" SG_ 2466239718 Pto1RemoteRequest 1;
BA_ "SeToolAncestorID_SIGNAL" SG_ 2466239718 Pto1RemoteRequest "x0000001D04153788";
BA_ "SeToolItemID_SIGNAL" SG_ 2466239718 Pto1RemoteRequest "x0000001D04153788";
BA_ "SeToolName_SIGNAL" SG_ 2466239718 Pto1RemoteRequest "Pto1RemoteRequest";
BA_ "SeToolVersion_SIGNAL" SG_ 2466239718 Pto1RemoteRequest "1";
BA_ "GenSigCycleTime" SG_ 2466239718 Pto3RemoteRequest 100;
BA_ "GenSigCycleTimeActive" SG_ 2466239718 Pto3RemoteRequest 100;
BA_ "GenSigStartValue" SG_ 2466239718 Pto3RemoteRequest 3;
BA_ "GenSigMaxLatency" SG_ 2466239718 Pto3RemoteRequest 59;
BA_ "Platform_VMCU1_Sig" SG_ 2466239718 Pto3RemoteRequest 1;
BA_ "SeToolAncestorID_SIGNAL" SG_ 2466239718 Pto3RemoteRequest "x0000001D0415378C";
BA_ "SeToolItemID_SIGNAL" SG_ 2466239718 Pto3RemoteRequest "x0000001D0415378C";
BA_ "SeToolName_SIGNAL" SG_ 2466239718 Pto3RemoteRequest "Pto3RemoteRequest";
BA_ "SeToolVersion_SIGNAL" SG_ 2466239718 Pto3RemoteRequest "1";
BA_ "GenSigCycleTime" SG_ 2466239718 FdEquipmentValue2_ISig_4 100;
BA_ "GenSigCycleTimeActive" SG_ 2466239718 FdEquipmentValue2_ISig_4 100;
BA_ "GenSigStartValue" SG_ 2466239718 FdEquipmentValue2_ISig_4 255;
BA_ "GenSigMaxLatency" SG_ 2466239718 FdEquipmentValue2_ISig_4 59;
BA_ "Platform_VMCU1_Sig" SG_ 2466239718 FdEquipmentValue2_ISig_4 1;
BA_ "SeToolAncestorID_SIGNAL" SG_ 2466239718 FdEquipmentValue2_ISig_4 "x0000001D04171241";
BA_ "SeToolItemID_SIGNAL" SG_ 2466239718 FdEquipmentValue2_ISig_4 "x0000001D04171241";
BA_ "SeToolName_SIGNAL" SG_ 2466239718 FdEquipmentValue2_ISig_4 "FdEquipmentValue2";
BA_ "SeToolVersion_SIGNAL" SG_ 2466239718 FdEquipmentValue2_ISig_4 "1";
BA_ "GenSigCycleTime" SG_ 2466239718 BBHazardWarning_rqst 100;
BA_ "GenSigCycleTimeActive" SG_ 2466239718 BBHazardWarning_rqst 100;
BA_ "GenSigStartValue" SG_ 2466239718 BBHazardWarning_rqst 3;
BA_ "Platform_VMCU1_Sig" SG_ 2466239718 BBHazardWarning_rqst 1;
BA_ "GenSigCycleTime" SG_ 2466239718 FdEquipmentStatus5_ISig_4 100;
BA_ "GenSigCycleTimeActive" SG_ 2466239718 FdEquipmentStatus5_ISig_4 100;
BA_ "GenSigStartValue" SG_ 2466239718 FdEquipmentStatus5_ISig_4 3;
BA_ "GenSigMaxLatency" SG_ 2466239718 FdEquipmentStatus5_ISig_4 59;
BA_ "Platform_VMCU1_Sig" SG_ 2466239718 FdEquipmentStatus5_ISig_4 1;
BA_ "SeToolAncestorID_SIGNAL" SG_ 2466239718 FdEquipmentStatus5_ISig_4 "x0000001D04170A02";
BA_ "SeToolItemID_SIGNAL" SG_ 2466239718 FdEquipmentStatus5_ISig_4 "x0000001D04170A02";
BA_ "SeToolName_SIGNAL" SG_ 2466239718 FdEquipmentStatus5_ISig_4 "FdEquipmentStatus5";
BA_ "SeToolVersion_SIGNAL" SG_ 2466239718 FdEquipmentStatus5_ISig_4 "1";
BA_ "GenSigCycleTime" SG_ 2466239718 RssInhibitStartEngFromBB_rqst 100;
BA_ "GenSigCycleTimeActive" SG_ 2466239718 RssInhibitStartEngFromBB_rqst 100;
BA_ "GenSigStartValue" SG_ 2466239718 RssInhibitStartEngFromBB_rqst 3;
BA_ "Platform_VMCU1_Sig" SG_ 2466239718 RssInhibitStartEngFromBB_rqst 1;
BA_ "GenSigCycleTime" SG_ 2466239718 BBNetwExtraSWrknLight_stat 100;
BA_ "GenSigCycleTimeActive" SG_ 2466239718 BBNetwExtraSWrknLight_stat 100;
BA_ "GenSigStartValue" SG_ 2466239718 BBNetwExtraSWrknLight_stat 7;
BA_ "Platform_VMCU1_Sig" SG_ 2466239718 BBNetwExtraSWrknLight_stat 1;
BA_ "GenSigCycleTime" SG_ 2466239718 FdEquipmentStatus4_ISig_4 100;
BA_ "GenSigCycleTimeActive" SG_ 2466239718 FdEquipmentStatus4_ISig_4 100;
BA_ "GenSigStartValue" SG_ 2466239718 FdEquipmentStatus4_ISig_4 3;
BA_ "GenSigMaxLatency" SG_ 2466239718 FdEquipmentStatus4_ISig_4 59;
BA_ "Platform_VMCU1_Sig" SG_ 2466239718 FdEquipmentStatus4_ISig_4 1;
BA_ "SeToolAncestorID_SIGNAL" SG_ 2466239718 FdEquipmentStatus4_ISig_4 "x0000001D04170A00";
BA_ "SeToolItemID_SIGNAL" SG_ 2466239718 FdEquipmentStatus4_ISig_4 "x0000001D04170A00";
BA_ "SeToolName_SIGNAL" SG_ 2466239718 FdEquipmentStatus4_ISig_4 "FdEquipmentStatus4";
BA_ "SeToolVersion_SIGNAL" SG_ 2466239718 FdEquipmentStatus4_ISig_4 "1";
BA_ "GenSigCycleTime" SG_ 2466239718 FdEquipmentStatus3_ISig_4 100;
BA_ "GenSigCycleTimeActive" SG_ 2466239718 FdEquipmentStatus3_ISig_4 100;
BA_ "GenSigStartValue" SG_ 2466239718 FdEquipmentStatus3_ISig_4 3;
BA_ "GenSigMaxLatency" SG_ 2466239718 FdEquipmentStatus3_ISig_4 59;
BA_ "Platform_VMCU1_Sig" SG_ 2466239718 FdEquipmentStatus3_ISig_4 1;
BA_ "SeToolAncestorID_SIGNAL" SG_ 2466239718 FdEquipmentStatus3_ISig_4 "x0000001D041709FE";
BA_ "SeToolItemID_SIGNAL" SG_ 2466239718 FdEquipmentStatus3_ISig_4 "x0000001D041709FE";
BA_ "SeToolName_SIGNAL" SG_ 2466239718 FdEquipmentStatus3_ISig_4 "FdEquipmentStatus3";
BA_ "SeToolVersion_SIGNAL" SG_ 2466239718 FdEquipmentStatus3_ISig_4 "1";
BA_ "GenSigCycleTime" SG_ 2466239718 BBNetwWrknLightChassis_stat 100;
BA_ "GenSigCycleTimeActive" SG_ 2466239718 BBNetwWrknLightChassis_stat 100;
BA_ "GenSigStartValue" SG_ 2466239718 BBNetwWrknLightChassis_stat 3;
BA_ "Platform_VMCU1_Sig" SG_ 2466239718 BBNetwWrknLightChassis_stat 1;
BA_ "GenSigCycleTime" SG_ 2466239718 BBNetwBodyOrCabWrknLight_stat 100;
BA_ "GenSigCycleTimeActive" SG_ 2466239718 BBNetwBodyOrCabWrknLight_stat 100;
BA_ "GenSigStartValue" SG_ 2466239718 BBNetwBodyOrCabWrknLight_stat 3;
BA_ "Platform_VMCU1_Sig" SG_ 2466239718 BBNetwBodyOrCabWrknLight_stat 1;
BA_ "GenSigCycleTime" SG_ 2466239718 BBNetwTrailerBodyLighting_rqst 100;
BA_ "GenSigCycleTimeActive" SG_ 2466239718 BBNetwTrailerBodyLighting_rqst 100;
BA_ "GenSigStartValue" SG_ 2466239718 BBNetwTrailerBodyLighting_rqst 3;
BA_ "Platform_VMCU1_Sig" SG_ 2466239718 BBNetwTrailerBodyLighting_rqst 1;
BA_ "GenSigCycleTime" SG_ 2466239718 Pto4RemoteRequest 100;
BA_ "GenSigCycleTimeActive" SG_ 2466239718 Pto4RemoteRequest 100;
BA_ "GenSigStartValue" SG_ 2466239718 Pto4RemoteRequest 3;
BA_ "GenSigMaxLatency" SG_ 2466239718 Pto4RemoteRequest 59;
BA_ "Platform_VMCU1_Sig" SG_ 2466239718 Pto4RemoteRequest 1;
BA_ "SeToolAncestorID_SIGNAL" SG_ 2466239718 Pto4RemoteRequest "x0000001D04153791";
BA_ "SeToolItemID_SIGNAL" SG_ 2466239718 Pto4RemoteRequest "x0000001D04153791";
BA_ "SeToolName_SIGNAL" SG_ 2466239718 Pto4RemoteRequest "Pto4RemoteRequest";
BA_ "SeToolVersion_SIGNAL" SG_ 2466239718 Pto4RemoteRequest "1";
BA_ "GenSigCycleTime" SG_ 2466239718 Pto3FeedbackStatus 100;
BA_ "GenSigCycleTimeActive" SG_ 2466239718 Pto3FeedbackStatus 100;
BA_ "GenSigStartValue" SG_ 2466239718 Pto3FeedbackStatus 3;
BA_ "GenSigMaxLatency" SG_ 2466239718 Pto3FeedbackStatus 59;
BA_ "Platform_VMCU1_Sig" SG_ 2466239718 Pto3FeedbackStatus 1;
BA_ "SeToolAncestorID_SIGNAL" SG_ 2466239718 Pto3FeedbackStatus "x0000001D041538E2";
BA_ "SeToolItemID_SIGNAL" SG_ 2466239718 Pto3FeedbackStatus "x0000001D041538E2";
BA_ "SeToolName_SIGNAL" SG_ 2466239718 Pto3FeedbackStatus "Pto3FeedbackStatus";
BA_ "SeToolVersion_SIGNAL" SG_ 2466239718 Pto3FeedbackStatus "1";
BA_ "GenSigCycleTime" SG_ 2466239718 FdEquipmentValue3_ISig_4 100;
BA_ "GenSigCycleTimeActive" SG_ 2466239718 FdEquipmentValue3_ISig_4 100;
BA_ "GenSigStartValue" SG_ 2466239718 FdEquipmentValue3_ISig_4 255;
BA_ "GenSigMaxLatency" SG_ 2466239718 FdEquipmentValue3_ISig_4 59;
BA_ "Platform_VMCU1_Sig" SG_ 2466239718 FdEquipmentValue3_ISig_4 1;
BA_ "SeToolAncestorID_SIGNAL" SG_ 2466239718 FdEquipmentValue3_ISig_4 "x0000001D04171243";
BA_ "SeToolItemID_SIGNAL" SG_ 2466239718 FdEquipmentValue3_ISig_4 "x0000001D043A9096";
BA_ "SeToolName_SIGNAL" SG_ 2466239718 FdEquipmentValue3_ISig_4 "FdEquipmentValue3";
BA_ "SeToolVersion_SIGNAL" SG_ 2466239718 FdEquipmentValue3_ISig_4 "2";
BA_ "GenSigCycleTime" SG_ 2466217958 EscChassisActivationRequest 100;
BA_ "GenSigCycleTimeActive" SG_ 2466217958 EscChassisActivationRequest 100;
BA_ "GenSigStartValue" SG_ 2466217958 EscChassisActivationRequest 3;
BA_ "GenSigMaxLatency" SG_ 2466217958 EscChassisActivationRequest 57;
BA_ "Platform_VMCU1_Sig" SG_ 2466217958 EscChassisActivationRequest 1;
BA_ "SeToolAncestorID_SIGNAL" SG_ 2466217958 EscChassisActivationRequest "x0000001D043DFB31";
BA_ "SeToolItemID_SIGNAL" SG_ 2466217958 EscChassisActivationRequest "x0000001D043DFB31";
BA_ "SeToolName_SIGNAL" SG_ 2466217958 EscChassisActivationRequest "EscChassisActivationRequest";
BA_ "SeToolVersion_SIGNAL" SG_ 2466217958 EscChassisActivationRequest "1";
BA_ "GenSigCycleTime" SG_ 2466217958 EscChassisTargetRequest 100;
BA_ "GenSigCycleTimeActive" SG_ 2466217958 EscChassisTargetRequest 100;
BA_ "GenSigStartValue" SG_ 2466217958 EscChassisTargetRequest 65535;
BA_ "GenSigMaxLatency" SG_ 2466217958 EscChassisTargetRequest 57;
BA_ "Platform_VMCU1_Sig" SG_ 2466217958 EscChassisTargetRequest 1;
BA_ "SeToolAncestorID_SIGNAL" SG_ 2466217958 EscChassisTargetRequest "x0000001D04197020";
BA_ "SeToolItemID_SIGNAL" SG_ 2466217958 EscChassisTargetRequest "x0000001D04197020";
BA_ "SeToolName_SIGNAL" SG_ 2466217958 EscChassisTargetRequest "EscChassisTargetRequest";
BA_ "SeToolVersion_SIGNAL" SG_ 2466217958 EscChassisTargetRequest "1";
BA_ "GenSigCycleTime" SG_ 2466217958 PloughLampModeStatus_ISig_4 100;
BA_ "GenSigCycleTimeActive" SG_ 2466217958 PloughLampModeStatus_ISig_4 100;
BA_ "GenSigStartValue" SG_ 2466217958 PloughLampModeStatus_ISig_4 3;
BA_ "Platform_VMCU1_Sig" SG_ 2466217958 PloughLampModeStatus_ISig_4 1;
BA_ "GenSigCycleTime" SG_ 2466217958 CtaBB_Horn_rqst 100;
BA_ "GenSigCycleTimeActive" SG_ 2466217958 CtaBB_Horn_rqst 100;
BA_ "GenSigStartValue" SG_ 2466217958 CtaBB_Horn_rqst 3;
BA_ "GenSigMaxLatency" SG_ 2466217958 CtaBB_Horn_rqst 57;
BA_ "Platform_VMCU1_Sig" SG_ 2466217958 CtaBB_Horn_rqst 1;
BA_ "GenSigCycleTime" SG_ 2466217958 EscChassisEngineSpdSelection 100;
BA_ "GenSigCycleTimeActive" SG_ 2466217958 EscChassisEngineSpdSelection 100;
BA_ "GenSigStartValue" SG_ 2466217958 EscChassisEngineSpdSelection 7;
BA_ "GenSigMaxLatency" SG_ 2466217958 EscChassisEngineSpdSelection 57;
BA_ "Platform_VMCU1_Sig" SG_ 2466217958 EscChassisEngineSpdSelection 1;
BA_ "SeToolAncestorID_SIGNAL" SG_ 2466217958 EscChassisEngineSpdSelection "x0000001D042C5CA5";
BA_ "SeToolItemID_SIGNAL" SG_ 2466217958 EscChassisEngineSpdSelection "x0000001D042C5CA5";
BA_ "SeToolName_SIGNAL" SG_ 2466217958 EscChassisEngineSpdSelection "EscChassisEngineSpdSelection";
BA_ "SeToolVersion_SIGNAL" SG_ 2466217958 EscChassisEngineSpdSelection "1";
BA_ "GenSigCycleTime" SG_ 2466217958 EscChassisActionRequest 100;
BA_ "GenSigCycleTimeActive" SG_ 2466217958 EscChassisActionRequest 100;
BA_ "GenSigStartValue" SG_ 2466217958 EscChassisActionRequest 7;
BA_ "GenSigMaxLatency" SG_ 2466217958 EscChassisActionRequest 57;
BA_ "Platform_VMCU1_Sig" SG_ 2466217958 EscChassisActionRequest 1;
BA_ "SeToolAncestorID_SIGNAL" SG_ 2466217958 EscChassisActionRequest "x0000001D044050FE";
BA_ "SeToolItemID_SIGNAL" SG_ 2466217958 EscChassisActionRequest "x0000001D044050FE";
BA_ "SeToolName_SIGNAL" SG_ 2466217958 EscChassisActionRequest "EscChassisActionRequest";
BA_ "SeToolVersion_SIGNAL" SG_ 2466217958 EscChassisActionRequest "1";
BA_ "GenSigCycleTime" SG_ 2466217958 EscChassisMaxEngineTorque_rqst 100;
BA_ "GenSigCycleTimeActive" SG_ 2466217958 EscChassisMaxEngineTorque_rqst 100;
BA_ "GenSigStartValue" SG_ 2466217958 EscChassisMaxEngineTorque_rqst 255;
BA_ "GenSigMaxLatency" SG_ 2466217958 EscChassisMaxEngineTorque_rqst 57;
BA_ "Platform_VMCU1_Sig" SG_ 2466217958 EscChassisMaxEngineTorque_rqst 1;
BA_ "SeToolAncestorID_SIGNAL" SG_ 2466217958 EscChassisMaxEngineTorque_rqst "x0000001D04197027";
BA_ "SeToolItemID_SIGNAL" SG_ 2466217958 EscChassisMaxEngineTorque_rqst "x0000001D04197027";
BA_ "SeToolName_SIGNAL" SG_ 2466217958 EscChassisMaxEngineTorque_rqst "EscChassisMaxEngineTorqueRequest";
BA_ "SeToolVersion_SIGNAL" SG_ 2466217958 EscChassisMaxEngineTorque_rqst "1";
BA_ "GenSigCycleTime" SG_ 2466217958 EscChassisMaxEngineSpeed_rqst 100;
BA_ "GenSigCycleTimeActive" SG_ 2466217958 EscChassisMaxEngineSpeed_rqst 100;
BA_ "GenSigStartValue" SG_ 2466217958 EscChassisMaxEngineSpeed_rqst 255;
BA_ "GenSigMaxLatency" SG_ 2466217958 EscChassisMaxEngineSpeed_rqst 57;
BA_ "Platform_VMCU1_Sig" SG_ 2466217958 EscChassisMaxEngineSpeed_rqst 1;
BA_ "SeToolAncestorID_SIGNAL" SG_ 2466217958 EscChassisMaxEngineSpeed_rqst "x0000001D04197025";
BA_ "SeToolItemID_SIGNAL" SG_ 2466217958 EscChassisMaxEngineSpeed_rqst "x0000001D04197025";
BA_ "SeToolName_SIGNAL" SG_ 2466217958 EscChassisMaxEngineSpeed_rqst "EscChassisMaxEngineSpeedRequest";
BA_ "SeToolVersion_SIGNAL" SG_ 2466217958 EscChassisMaxEngineSpeed_rqst "1";
BA_ "GenSigCycleTime" SG_ 2466217958 EscChassisEnable 100;
BA_ "GenSigCycleTimeActive" SG_ 2466217958 EscChassisEnable 100;
BA_ "GenSigStartValue" SG_ 2466217958 EscChassisEnable 3;
BA_ "GenSigMaxLatency" SG_ 2466217958 EscChassisEnable 57;
BA_ "Platform_VMCU1_Sig" SG_ 2466217958 EscChassisEnable 1;
BA_ "SeToolAncestorID_SIGNAL" SG_ 2466217958 EscChassisEnable "x0000001D043DFB2F";
BA_ "SeToolItemID_SIGNAL" SG_ 2466217958 EscChassisEnable "x0000001D043DFB2F";
BA_ "SeToolName_SIGNAL" SG_ 2466217958 EscChassisEnable "EscChassisEnable";
BA_ "SeToolVersion_SIGNAL" SG_ 2466217958 EscChassisEnable "1";
BA_ "GenSigCycleTime" SG_ 2466217958 CtaBs_VehicleImmobilizationCmd_I 100;
BA_ "GenSigCycleTimeActive" SG_ 2466217958 CtaBs_VehicleImmobilizationCmd_I 100;
BA_ "GenSigStartValue" SG_ 2466217958 CtaBs_VehicleImmobilizationCmd_I 3;
BA_ "GenSigMaxLatency" SG_ 2466217958 CtaBs_VehicleImmobilizationCmd_I 57;
BA_ "Platform_VMCU1_Sig" SG_ 2466217958 CtaBs_VehicleImmobilizationCmd_I 1;
BA_ "SeToolAncestorID_SIGNAL" SG_ 2466217958 CtaBs_VehicleImmobilizationCmd_I "x0000001D0418087A";
BA_ "SeToolItemID_SIGNAL" SG_ 2466217958 CtaBs_VehicleImmobilizationCmd_I "x0000001D0418087A";
BA_ "SeToolName_SIGNAL" SG_ 2466217958 CtaBs_VehicleImmobilizationCmd_I "CtaBs_VehicleImmobilizationCmd";
BA_ "SeToolVersion_SIGNAL" SG_ 2466217958 CtaBs_VehicleImmobilizationCmd_I "1";
BA_ "SystemSignalLongSymbol" SG_ 2466217958 CtaBs_VehicleImmobilizationCmd_I "CtaBs_VehicleImmobilizationCmd_ISig_4";
BA_ "GenSigCycleTime" SG_ 2466217958 BBRslBBRoadSpeedLimit_ISig_4 100;
BA_ "GenSigCycleTimeActive" SG_ 2466217958 BBRslBBRoadSpeedLimit_ISig_4 100;
BA_ "GenSigStartValue" SG_ 2466217958 BBRslBBRoadSpeedLimit_ISig_4 255;
BA_ "GenSigMaxLatency" SG_ 2466217958 BBRslBBRoadSpeedLimit_ISig_4 57;
BA_ "Platform_VMCU1_Sig" SG_ 2466217958 BBRslBBRoadSpeedLimit_ISig_4 1;
BA_ "SeToolAncestorID_SIGNAL" SG_ 2466217958 BBRslBBRoadSpeedLimit_ISig_4 "x0000001D041600C2";
BA_ "SeToolItemID_SIGNAL" SG_ 2466217958 BBRslBBRoadSpeedLimit_ISig_4 "x0000001D041600C2";
BA_ "SeToolName_SIGNAL" SG_ 2466217958 BBRslBBRoadSpeedLimit_ISig_4 "BBRslBBRoadSpeedLimit";
BA_ "SeToolVersion_SIGNAL" SG_ 2466217958 BBRslBBRoadSpeedLimit_ISig_4 "1";
BA_ "GenSigSendType" SG_ 2633994247 AnmSig_VMCU_Backbone2 1;
BA_ "GenSigCycleTime" SG_ 2633994247 AnmSig_VMCU_Backbone2 100;
BA_ "GenSigCycleTimeActive" SG_ 2633994247 AnmSig_VMCU_Backbone2 100;
BA_ "MmAnSignal" SG_ 2633994247 AnmSig_VMCU_Backbone2 1;
BA_ "Platform_VMCU1_Sig" SG_ 2633994247 AnmSig_VMCU_Backbone2 1;
BA_ "GenSigSendType" SG_ 2633994246 AnmSig_TECU_Backbone2 1;
BA_ "GenSigCycleTime" SG_ 2633994246 AnmSig_TECU_Backbone2 100;
BA_ "GenSigCycleTimeActive" SG_ 2633994246 AnmSig_TECU_Backbone2 100;
BA_ "MmAnSignal" SG_ 2633994246 AnmSig_TECU_Backbone2 1;
BA_ "Platform_VMCU1_Sig" SG_ 2633994246 AnmSig_TECU_Backbone2 1;
BA_ "GenSigSendType" SG_ 1715 AnmSig_IC3_Backbone2 1;
BA_ "GenSigCycleTime" SG_ 1715 AnmSig_IC3_Backbone2 100;
BA_ "GenSigCycleTimeActive" SG_ 1715 AnmSig_IC3_Backbone2 100;
BA_ "MmAnSignal" SG_ 1715 AnmSig_IC3_Backbone2 1;
BA_ "Platform_VMCU1_Sig" SG_ 1715 AnmSig_IC3_Backbone2 1;
BA_ "GenSigSendType" SG_ 2633994243 AnmSig_EMS_Backbone2 1;
BA_ "GenSigCycleTime" SG_ 2633994243 AnmSig_EMS_Backbone2 100;
BA_ "GenSigCycleTimeActive" SG_ 2633994243 AnmSig_EMS_Backbone2 100;
BA_ "MmAnSignal" SG_ 2633994243 AnmSig_EMS_Backbone2 1;
BA_ "Platform_VMCU1_Sig" SG_ 2633994243 AnmSig_EMS_Backbone2 1;
BA_ "GenSigSendType" SG_ 2633994310 AnmSig_ECUspare2_Backbone2 1;
BA_ "GenSigCycleTime" SG_ 2633994310 AnmSig_ECUspare2_Backbone2 100;
BA_ "GenSigCycleTimeActive" SG_ 2633994310 AnmSig_ECUspare2_Backbone2 100;
BA_ "MmAnSignal" SG_ 2633994310 AnmSig_ECUspare2_Backbone2 1;
BA_ "Platform_VMCU1_Sig" SG_ 2633994310 AnmSig_ECUspare2_Backbone2 1;
BA_ "GenSigSendType" SG_ 2633994309 AnmSig_ECUspare1_Backbone2 1;
BA_ "GenSigCycleTime" SG_ 2633994309 AnmSig_ECUspare1_Backbone2 100;
BA_ "GenSigCycleTimeActive" SG_ 2633994309 AnmSig_ECUspare1_Backbone2 100;
BA_ "MmAnSignal" SG_ 2633994309 AnmSig_ECUspare1_Backbone2 1;
BA_ "Platform_VMCU1_Sig" SG_ 2633994309 AnmSig_ECUspare1_Backbone2 1;
BA_ "GenSigSendType" SG_ 2633994242 AnmSig_DACU_Backbone2 1;
BA_ "GenSigCycleTime" SG_ 2633994242 AnmSig_DACU_Backbone2 100;
BA_ "GenSigCycleTimeActive" SG_ 2633994242 AnmSig_DACU_Backbone2 100;
BA_ "MmAnSignal" SG_ 2633994242 AnmSig_DACU_Backbone2 1;
BA_ "Platform_VMCU1_Sig" SG_ 2633994242 AnmSig_DACU_Backbone2 1;
BA_ "GenSigSendType" SG_ 2633994241 AnmSig_CIOM_Backbone2 1;
BA_ "GenSigCycleTime" SG_ 2633994241 AnmSig_CIOM_Backbone2 100;
BA_ "GenSigCycleTimeActive" SG_ 2633994241 AnmSig_CIOM_Backbone2 100;
BA_ "MmAnSignal" SG_ 2633994241 AnmSig_CIOM_Backbone2 1;
BA_ "Platform_VMCU1_Sig" SG_ 2633994241 AnmSig_CIOM_Backbone2 1;
BA_ "GenSigSendType" SG_ 2633994240 AnmSig_BBM_Backbone2 1;
BA_ "GenSigCycleTime" SG_ 2633994240 AnmSig_BBM_Backbone2 100;
BA_ "GenSigCycleTimeActive" SG_ 2633994240 AnmSig_BBM_Backbone2 100;
BA_ "MmAnSignal" SG_ 2633994240 AnmSig_BBM_Backbone2 1;
BA_ "Platform_VMCU1_Sig" SG_ 2633994240 AnmSig_BBM_Backbone2 1;
BA_REL_ "GenSigFirstTimeoutTime" BU_SG_REL_ VMCU SG_ 2482973248 FPBRChangeReq_ISig_4 3000;
BA_REL_ "GenSigTimeoutTime" BU_SG_REL_ VMCU SG_ 2482973248 FPBRChangeReq_ISig_4 300;
BA_REL_ "GenSigFirstTimeoutTime" BU_SG_REL_ VMCU SG_ 2482973248 HeadLampUpDown_SwitchStatus 3000;
BA_REL_ "GenSigTimeoutTime" BU_SG_REL_ VMCU SG_ 2482973248 HeadLampUpDown_SwitchStatus 300;
BA_REL_ "GenSigFirstTimeoutTime" BU_SG_REL_ IC3 SG_ 2482973248 Recirc_ButtonStatus_ISig_4 3000;
BA_REL_ "GenSigTimeoutTime" BU_SG_REL_ IC3 SG_ 2482973248 Recirc_ButtonStatus_ISig_4 300;
BA_REL_ "GenSigFirstTimeoutTime" BU_SG_REL_ IC3 SG_ 2482973248 Auto_ButtonStatus_ISig_4 3000;
BA_REL_ "GenSigTimeoutTime" BU_SG_REL_ IC3 SG_ 2482973248 Auto_ButtonStatus_ISig_4 300;
BA_REL_ "GenSigFirstTimeoutTime" BU_SG_REL_ IC3 SG_ 2482973248 AirFlowSelectionFrontBtn_stat_IS 3000;
BA_REL_ "GenSigTimeoutTime" BU_SG_REL_ IC3 SG_ 2482973248 AirFlowSelectionFrontBtn_stat_IS 300;
BA_REL_ "GenSigFirstTimeoutTime" BU_SG_REL_ VMCU SG_ 2482973248 InteriorLightMode_rqst_IL_Mode 3000;
BA_REL_ "GenSigTimeoutTime" BU_SG_REL_ VMCU SG_ 2482973248 InteriorLightMode_rqst_IL_Mode 300;
BA_REL_ "GenSigFirstTimeoutTime" BU_SG_REL_ VMCU SG_ 2482973248 InteriorLightMode_rqst_EventFlag 3000;
BA_REL_ "GenSigTimeoutTime" BU_SG_REL_ VMCU SG_ 2482973248 InteriorLightMode_rqst_EventFlag 300;
BA_REL_ "GenSigFirstTimeoutTime" BU_SG_REL_ VMCU SG_ 2482973248 BlackOutConvoyModeSwitchStatus 3000;
BA_REL_ "GenSigTimeoutTime" BU_SG_REL_ VMCU SG_ 2482973248 BlackOutConvoyModeSwitchStatus 300;
BA_REL_ "GenSigFirstTimeoutTime" BU_SG_REL_ VMCU SG_ 2482973248 Indicator_Lights_Alarm_rqst_ISig 3000;
BA_REL_ "GenSigTimeoutTime" BU_SG_REL_ VMCU SG_ 2482973248 Indicator_Lights_Alarm_rqst_ISig 300;
BA_REL_ "GenSigFirstTimeoutTime" BU_SG_REL_ IC3 SG_ 2482973248 AirFlowSelectionDownBtn_stat_ISi 3000;
BA_REL_ "GenSigTimeoutTime" BU_SG_REL_ IC3 SG_ 2482973248 AirFlowSelectionDownBtn_stat_ISi 300;
BA_REL_ "GenSigFirstTimeoutTime" BU_SG_REL_ BBM SG_ 2482973248 ParkingHeater_IndicationCmd_ISig 3000;
BA_REL_ "GenSigTimeoutTime" BU_SG_REL_ BBM SG_ 2482973248 ParkingHeater_IndicationCmd_ISig 300;
BA_REL_ "GenSigFirstTimeoutTime" BU_SG_REL_ IC3 SG_ 2482973248 AirFlowSelectionUpBtn_stat_ISig_ 3000;
BA_REL_ "GenSigTimeoutTime" BU_SG_REL_ IC3 SG_ 2482973248 AirFlowSelectionUpBtn_stat_ISig_ 300;
BA_REL_ "GenSigFirstTimeoutTime" BU_SG_REL_ VMCU SG_ 2482973248 ApproachLight_HMI_rqst 3000;
BA_REL_ "GenSigTimeoutTime" BU_SG_REL_ VMCU SG_ 2482973248 ApproachLight_HMI_rqst 300;
BA_REL_ "GenSigFirstTimeoutTime" BU_SG_REL_ IC3 SG_ 2482973248 Temperature_FreeWheelStatus_ISig 3000;
BA_REL_ "GenSigTimeoutTime" BU_SG_REL_ IC3 SG_ 2482973248 Temperature_FreeWheelStatus_ISig 300;
BA_REL_ "GenSigFirstTimeoutTime" BU_SG_REL_ IC3 SG_ 2482973248 AirBlowerSpeed_FreeWheelStatus_I 3000;
BA_REL_ "GenSigTimeoutTime" BU_SG_REL_ IC3 SG_ 2482973248 AirBlowerSpeed_FreeWheelStatus_I 300;
BA_REL_ "GenSigFirstTimeoutTime" BU_SG_REL_ BBM SG_ 2482973248 CabInteriorTempVentilated_Stat_I 3000;
BA_REL_ "GenSigTimeoutTime" BU_SG_REL_ BBM SG_ 2482973248 CabInteriorTempVentilated_Stat_I 300;
BA_REL_ "GenSigFirstTimeoutTime" BU_SG_REL_ IC3 SG_ 2482973248 ParkHeaterCooler_ButtonStatus_IS 3000;
BA_REL_ "GenSigTimeoutTime" BU_SG_REL_ IC3 SG_ 2482973248 ParkHeaterCooler_ButtonStatus_IS 300;
BA_REL_ "GenSigFirstTimeoutTime" BU_SG_REL_ IC3 SG_ 2482973248 WindscreenDefrost_ButtonStatus_I 3000;
BA_REL_ "GenSigTimeoutTime" BU_SG_REL_ IC3 SG_ 2482973248 WindscreenDefrost_ButtonStatus_I 300;
BA_REL_ "GenSigFirstTimeoutTime" BU_SG_REL_ IC3 SG_ 2482973248 AC_ButtonStatus_ISig_4 3000;
BA_REL_ "GenSigTimeoutTime" BU_SG_REL_ IC3 SG_ 2482973248 AC_ButtonStatus_ISig_4 300;
BA_REL_ "GenSigFirstTimeoutTime" BU_SG_REL_ VMCU SG_ 2365532224 BBContainerUnlockRequest 3000;
BA_REL_ "GenSigTimeoutTime" BU_SG_REL_ VMCU SG_ 2365532224 BBContainerUnlockRequest 90;
BA_REL_ "GenSigFirstTimeoutTime" BU_SG_REL_ BBM SG_ 2365532224 CabPlowLight_rqst 3000;
BA_REL_ "GenSigTimeoutTime" BU_SG_REL_ BBM SG_ 2365532224 CabPlowLight_rqst 90;
BA_REL_ "GenSigFirstTimeoutTime" BU_SG_REL_ EMS SG_ 2365532224 AC_CompressorClutchCmd_ISig_4 3000;
BA_REL_ "GenSigTimeoutTime" BU_SG_REL_ EMS SG_ 2365532224 AC_CompressorClutchCmd_ISig_4 90;
BA_REL_ "GenSigFirstTimeoutTime" BU_SG_REL_ VMCU SG_ 2365532224 AC_CompressorClutchCmd_ISig_4 3000;
BA_REL_ "GenSigTimeoutTime" BU_SG_REL_ VMCU SG_ 2365532224 AC_CompressorClutchCmd_ISig_4 90;
BA_REL_ "GenSigFirstTimeoutTime" BU_SG_REL_ VMCU SG_ 2365532224 AuxSwitchBbLoad4_Request 3000;
BA_REL_ "GenSigTimeoutTime" BU_SG_REL_ VMCU SG_ 2365532224 AuxSwitchBbLoad4_Request 90;
BA_REL_ "GenSigFirstTimeoutTime" BU_SG_REL_ VMCU SG_ 2365532224 FogLightRear_ButtonStatus_1 3000;
BA_REL_ "GenSigTimeoutTime" BU_SG_REL_ VMCU SG_ 2365532224 FogLightRear_ButtonStatus_1 90;
BA_REL_ "GenSigFirstTimeoutTime" BU_SG_REL_ VMCU SG_ 2365532224 CabRoofSignOrVegaLight_rqst 3000;
BA_REL_ "GenSigTimeoutTime" BU_SG_REL_ VMCU SG_ 2365532224 CabRoofSignOrVegaLight_rqst 90;
BA_REL_ "GenSigFirstTimeoutTime" BU_SG_REL_ VMCU SG_ 2365532224 FogLightFront_ButtonStatus_2 3000;
BA_REL_ "GenSigTimeoutTime" BU_SG_REL_ VMCU SG_ 2365532224 FogLightFront_ButtonStatus_2 90;
BA_REL_ "GenSigFirstTimeoutTime" BU_SG_REL_ VMCU SG_ 2365532224 AuxSwitchBbLoad1_Request 3000;
BA_REL_ "GenSigTimeoutTime" BU_SG_REL_ VMCU SG_ 2365532224 AuxSwitchBbLoad1_Request 90;
BA_REL_ "GenSigFirstTimeoutTime" BU_SG_REL_ VMCU SG_ 2365532224 BBCraneRequest 3000;
BA_REL_ "GenSigTimeoutTime" BU_SG_REL_ VMCU SG_ 2365532224 BBCraneRequest 90;
BA_REL_ "GenSigFirstTimeoutTime" BU_SG_REL_ VMCU SG_ 2365532224 AuxSwitchBbLoad6_Request 3000;
BA_REL_ "GenSigTimeoutTime" BU_SG_REL_ VMCU SG_ 2365532224 AuxSwitchBbLoad6_Request 90;
BA_REL_ "GenSigFirstTimeoutTime" BU_SG_REL_ VMCU SG_ 2365532224 AuxSwitchBbLoad5_Request 3000;
BA_REL_ "GenSigTimeoutTime" BU_SG_REL_ VMCU SG_ 2365532224 AuxSwitchBbLoad5_Request 90;
BA_REL_ "GenSigFirstTimeoutTime" BU_SG_REL_ VMCU SG_ 2365532224 BodyOrCabWorkingLight_rqst 3000;
BA_REL_ "GenSigTimeoutTime" BU_SG_REL_ VMCU SG_ 2365532224 BodyOrCabWorkingLight_rqst 90;
BA_REL_ "GenSigFirstTimeoutTime" BU_SG_REL_ BBM SG_ 2365532224 BodyOrCabWorkingLight_rqst 3000;
BA_REL_ "GenSigTimeoutTime" BU_SG_REL_ BBM SG_ 2365532224 BodyOrCabWorkingLight_rqst 90;
BA_REL_ "GenSigFirstTimeoutTime" BU_SG_REL_ VMCU SG_ 2365532224 CabFrontSpot_rqst 3000;
BA_REL_ "GenSigTimeoutTime" BU_SG_REL_ VMCU SG_ 2365532224 CabFrontSpot_rqst 90;
BA_REL_ "GenSigFirstTimeoutTime" BU_SG_REL_ VMCU SG_ 2365532224 CabTrailerBodyLighting_rqst 3000;
BA_REL_ "GenSigTimeoutTime" BU_SG_REL_ VMCU SG_ 2365532224 CabTrailerBodyLighting_rqst 90;
BA_REL_ "GenSigFirstTimeoutTime" BU_SG_REL_ VMCU SG_ 2365532224 CabWorkingLightChassis_rqst 3000;
BA_REL_ "GenSigTimeoutTime" BU_SG_REL_ VMCU SG_ 2365532224 CabWorkingLightChassis_rqst 90;
BA_REL_ "GenSigFirstTimeoutTime" BU_SG_REL_ VMCU SG_ 2365532224 BBTailLiftRequest 3000;
BA_REL_ "GenSigTimeoutTime" BU_SG_REL_ VMCU SG_ 2365532224 BBTailLiftRequest 90;
BA_REL_ "GenSigFirstTimeoutTime" BU_SG_REL_ VMCU SG_ 2365532224 BBSlidable5thWheelRequest 3000;
BA_REL_ "GenSigTimeoutTime" BU_SG_REL_ VMCU SG_ 2365532224 BBSlidable5thWheelRequest 90;
BA_REL_ "GenSigFirstTimeoutTime" BU_SG_REL_ VMCU SG_ 2365532224 ACmode_IndicationCmd_ISig_4 3000;
BA_REL_ "GenSigTimeoutTime" BU_SG_REL_ VMCU SG_ 2365532224 ACmode_IndicationCmd_ISig_4 90;
BA_REL_ "GenSigFirstTimeoutTime" BU_SG_REL_ VMCU SG_ 2365532224 CabExtraSideWorkingLight_rqst 3000;
BA_REL_ "GenSigTimeoutTime" BU_SG_REL_ VMCU SG_ 2365532224 CabExtraSideWorkingLight_rqst 90;
BA_REL_ "GenSigFirstTimeoutTime" BU_SG_REL_ VMCU SG_ 2365532224 FogLightFront_ButtonStatus_1 3000;
BA_REL_ "GenSigTimeoutTime" BU_SG_REL_ VMCU SG_ 2365532224 FogLightFront_ButtonStatus_1 90;
BA_REL_ "GenSigFirstTimeoutTime" BU_SG_REL_ VMCU SG_ 2365532224 AuxSwitchBbLoad2_Request 3000;
BA_REL_ "GenSigTimeoutTime" BU_SG_REL_ VMCU SG_ 2365532224 AuxSwitchBbLoad2_Request 90;
BA_REL_ "GenSigFirstTimeoutTime" BU_SG_REL_ VMCU SG_ 2365532224 DRL_ButtonStatus 3000;
BA_REL_ "GenSigTimeoutTime" BU_SG_REL_ VMCU SG_ 2365532224 DRL_ButtonStatus 90;
BA_REL_ "GenSigFirstTimeoutTime" BU_SG_REL_ VMCU SG_ 2365532224 CabRoofSpot_rqst 3000;
BA_REL_ "GenSigTimeoutTime" BU_SG_REL_ VMCU SG_ 2365532224 CabRoofSpot_rqst 90;
BA_REL_ "GenSigFirstTimeoutTime" BU_SG_REL_ VMCU SG_ 2365532224 LightMode_Status_Ctr_2 3000;
BA_REL_ "GenSigTimeoutTime" BU_SG_REL_ VMCU SG_ 2365532224 LightMode_Status_Ctr_2 120;
BA_REL_ "GenSigFirstTimeoutTime" BU_SG_REL_ VMCU SG_ 2365532224 CabBeaconLight_rqst 3000;
BA_REL_ "GenSigTimeoutTime" BU_SG_REL_ VMCU SG_ 2365532224 CabBeaconLight_rqst 90;
BA_REL_ "GenSigFirstTimeoutTime" BU_SG_REL_ VMCU SG_ 2365532224 AuxSwitchBbLoad3_Request 3000;
BA_REL_ "GenSigTimeoutTime" BU_SG_REL_ VMCU SG_ 2365532224 AuxSwitchBbLoad3_Request 90;
BA_REL_ "GenSigFirstTimeoutTime" BU_SG_REL_ VMCU SG_ 2365532224 FogLightRear_ButtonStatus_2 3000;
BA_REL_ "GenSigTimeoutTime" BU_SG_REL_ VMCU SG_ 2365532224 FogLightRear_ButtonStatus_2 90;
BA_REL_ "GenSigFirstTimeoutTime" BU_SG_REL_ VMCU SG_ 2365532224 LightMode_Status_Ctr_1 3000;
BA_REL_ "GenSigTimeoutTime" BU_SG_REL_ VMCU SG_ 2365532224 LightMode_Status_Ctr_1 120;
BA_REL_ "GenSigFirstTimeoutTime" BU_SG_REL_ IC3 SG_ 2365532224 MirrorHeat_rqst 3000;
BA_REL_ "GenSigTimeoutTime" BU_SG_REL_ IC3 SG_ 2365532224 MirrorHeat_rqst 90;
BA_REL_ "GenSigFirstTimeoutTime" BU_SG_REL_ VMCU SG_ 2365532224 MirrorHeat_rqst 3000;
BA_REL_ "GenSigTimeoutTime" BU_SG_REL_ VMCU SG_ 2365532224 MirrorHeat_rqst 90;
BA_REL_ "GenSigFirstTimeoutTime" BU_SG_REL_ VMCU SG_ 2432643136 LevelRequest_RollRequest_ISig_4 3000;
BA_REL_ "GenSigTimeoutTime" BU_SG_REL_ VMCU SG_ 2432643136 LevelRequest_RollRequest_ISig_4 500;
BA_REL_ "GenSigFirstTimeoutTime" BU_SG_REL_ VMCU SG_ 2432643136 FerryFunctionSwitchChangeReq_ISi 3000;
BA_REL_ "GenSigTimeoutTime" BU_SG_REL_ VMCU SG_ 2432643136 FerryFunctionSwitchChangeReq_ISi 120;
BA_REL_ "GenSigFirstTimeoutTime" BU_SG_REL_ VMCU SG_ 2432643136 FerryFunctionRequest_ISig_4 3000;
BA_REL_ "GenSigTimeoutTime" BU_SG_REL_ VMCU SG_ 2432643136 FerryFunctionRequest_ISig_4 500;
BA_REL_ "GenSigFirstTimeoutTime" BU_SG_REL_ VMCU SG_ 2432643136 LevelRequest_FrontAxle_ISig_4 3000;
BA_REL_ "GenSigTimeoutTime" BU_SG_REL_ VMCU SG_ 2432643136 LevelRequest_FrontAxle_ISig_4 500;
BA_REL_ "GenSigFirstTimeoutTime" BU_SG_REL_ VMCU SG_ 2432643136 KneelingChangeRequest_ISig_4 3000;
BA_REL_ "GenSigTimeoutTime" BU_SG_REL_ VMCU SG_ 2432643136 KneelingChangeRequest_ISig_4 120;
BA_REL_ "GenSigFirstTimeoutTime" BU_SG_REL_ IC3 SG_ 2432643136 BunkH1AudioSrcSem_rqst_ISig_4 3000;
BA_REL_ "GenSigTimeoutTime" BU_SG_REL_ IC3 SG_ 2432643136 BunkH1AudioSrcSem_rqst_ISig_4 120;
BA_REL_ "GenSigFirstTimeoutTime" BU_SG_REL_ VMCU SG_ 2432643136 ECSStandByRequest_ISig_4 3000;
BA_REL_ "GenSigTimeoutTime" BU_SG_REL_ VMCU SG_ 2432643136 ECSStandByRequest_ISig_4 120;
BA_REL_ "GenSigFirstTimeoutTime" BU_SG_REL_ VMCU SG_ 2432643136 LevelStrokeRequest_ISig_4 3000;
BA_REL_ "GenSigTimeoutTime" BU_SG_REL_ VMCU SG_ 2432643136 LevelStrokeRequest_ISig_4 120;
BA_REL_ "GenSigFirstTimeoutTime" BU_SG_REL_ VMCU SG_ 2432643136 RideHeightStorageRequest_ISig_4 3000;
BA_REL_ "GenSigTimeoutTime" BU_SG_REL_ VMCU SG_ 2432643136 RideHeightStorageRequest_ISig_4 120;
BA_REL_ "GenSigFirstTimeoutTime" BU_SG_REL_ VMCU SG_ 2432643136 RampLevelRequest_ISig_4 3000;
BA_REL_ "GenSigTimeoutTime" BU_SG_REL_ VMCU SG_ 2432643136 RampLevelRequest_ISig_4 120;
BA_REL_ "GenSigFirstTimeoutTime" BU_SG_REL_ IC3 SG_ 2432643136 TCP_KnobPostionStatus 3000;
BA_REL_ "GenSigTimeoutTime" BU_SG_REL_ IC3 SG_ 2432643136 TCP_KnobPostionStatus 120;
BA_REL_ "GenSigFirstTimeoutTime" BU_SG_REL_ DACU SG_ 2432643136 SetFCWOperation 3000;
BA_REL_ "GenSigTimeoutTime" BU_SG_REL_ DACU SG_ 2432643136 SetFCWOperation 120;
BA_REL_ "GenSigFirstTimeoutTime" BU_SG_REL_ VMCU SG_ 2432643136 StopLevelChangeRequest_ISig_4 3000;
BA_REL_ "GenSigTimeoutTime" BU_SG_REL_ VMCU SG_ 2432643136 StopLevelChangeRequest_ISig_4 120;
BA_REL_ "GenSigFirstTimeoutTime" BU_SG_REL_ VMCU SG_ 2432643136 RideHeightFunctionRequest_ISig_4 3000;
BA_REL_ "GenSigTimeoutTime" BU_SG_REL_ VMCU SG_ 2432643136 RideHeightFunctionRequest_ISig_4 500;
BA_REL_ "GenSigFirstTimeoutTime" BU_SG_REL_ VMCU SG_ 2432643136 LevelRequest_RearAxle_ISig_4 3000;
BA_REL_ "GenSigTimeoutTime" BU_SG_REL_ VMCU SG_ 2432643136 LevelRequest_RearAxle_ISig_4 500;
BA_REL_ "GenSigFirstTimeoutTime" BU_SG_REL_ VMCU SG_ 2432643136 RampLevelStorageRequest_ISig_4 3000;
BA_REL_ "GenSigTimeoutTime" BU_SG_REL_ VMCU SG_ 2432643136 RampLevelStorageRequest_ISig_4 120;
BA_REL_ "GenSigFirstTimeoutTime" BU_SG_REL_ DACU SG_ 2432643136 SetCMOperation 3000;
BA_REL_ "GenSigTimeoutTime" BU_SG_REL_ DACU SG_ 2432643136 SetCMOperation 120;
BA_REL_ "GenSigFirstTimeoutTime" BU_SG_REL_ IC3 SG_ 2432643136 SetCMOperation 3000;
BA_REL_ "GenSigTimeoutTime" BU_SG_REL_ IC3 SG_ 2432643136 SetCMOperation 120;
BA_REL_ "GenSigFirstTimeoutTime" BU_SG_REL_ VMCU SG_ 2432643136 SetCMOperation 3000;
BA_REL_ "GenSigTimeoutTime" BU_SG_REL_ VMCU SG_ 2432643136 SetCMOperation 120;
BA_REL_ "GenSigFirstTimeoutTime" BU_SG_REL_ VMCU SG_ 2432643136 BackToDriveReq_ISig_4 3000;
BA_REL_ "GenSigTimeoutTime" BU_SG_REL_ VMCU SG_ 2432643136 BackToDriveReq_ISig_4 120;
BA_REL_ "GenSigFirstTimeoutTime" BU_SG_REL_ VMCU SG_ 2432640832 LockingIndication_rqst 3000;
BA_REL_ "GenSigTimeoutTime" BU_SG_REL_ VMCU SG_ 2432640832 LockingIndication_rqst 120;
BA_REL_ "GenSigFirstTimeoutTime" BU_SG_REL_ VMCU SG_ 2432640832 KeyfobLockBtn_DoublePress_ISig_4 3000;
BA_REL_ "GenSigTimeoutTime" BU_SG_REL_ VMCU SG_ 2432640832 KeyfobLockBtn_DoublePress_ISig_4 120;
BA_REL_ "GenSigFirstTimeoutTime" BU_SG_REL_ VMCU SG_ 2432640832 MainSwitchButton_Status_ISig_4 3000;
BA_REL_ "GenSigTimeoutTime" BU_SG_REL_ VMCU SG_ 2432640832 MainSwitchButton_Status_ISig_4 120;
BA_REL_ "GenSigFirstTimeoutTime" BU_SG_REL_ VMCU SG_ 2432640832 CityHorn_cmd_ISig_4 3000;
BA_REL_ "GenSigTimeoutTime" BU_SG_REL_ VMCU SG_ 2432640832 CityHorn_cmd_ISig_4 500;
BA_REL_ "GenSigFirstTimeoutTime" BU_SG_REL_ BBM SG_ 2432640832 CityHorn_cmd_ISig_4 3000;
BA_REL_ "GenSigTimeoutTime" BU_SG_REL_ BBM SG_ 2432640832 CityHorn_cmd_ISig_4 500;
BA_REL_ "GenSigFirstTimeoutTime" BU_SG_REL_ VMCU SG_ 2432640832 KeyfobUnlockButton_Status 3000;
BA_REL_ "GenSigTimeoutTime" BU_SG_REL_ VMCU SG_ 2432640832 KeyfobUnlockButton_Status 120;
BA_REL_ "GenSigFirstTimeoutTime" BU_SG_REL_ VMCU SG_ 2432640832 BrakeBlendingButtonStatus 3000;
BA_REL_ "GenSigTimeoutTime" BU_SG_REL_ VMCU SG_ 2432640832 BrakeBlendingButtonStatus 120;
BA_REL_ "GenSigFirstTimeoutTime" BU_SG_REL_ IC3 SG_ 2432640832 KeyNotValid 3000;
BA_REL_ "GenSigTimeoutTime" BU_SG_REL_ IC3 SG_ 2432640832 KeyNotValid 120;
BA_REL_ "GenSigFirstTimeoutTime" BU_SG_REL_ VMCU SG_ 2432640832 ExtraMainbeam_SwitchStatus 3000;
BA_REL_ "GenSigTimeoutTime" BU_SG_REL_ VMCU SG_ 2432640832 ExtraMainbeam_SwitchStatus 120;
BA_REL_ "GenSigFirstTimeoutTime" BU_SG_REL_ BBM SG_ 2432640832 AuxiliaryHorn_cmd_ISig_4 3000;
BA_REL_ "GenSigTimeoutTime" BU_SG_REL_ BBM SG_ 2432640832 AuxiliaryHorn_cmd_ISig_4 500;
BA_REL_ "GenSigFirstTimeoutTime" BU_SG_REL_ VMCU SG_ 2432640832 AuxiliaryHorn_cmd_ISig_4 3000;
BA_REL_ "GenSigTimeoutTime" BU_SG_REL_ VMCU SG_ 2432640832 AuxiliaryHorn_cmd_ISig_4 500;
BA_REL_ "GenSigFirstTimeoutTime" BU_SG_REL_ VMCU SG_ 2432640832 ReverseWarning_rqst_ISig_4 3000;
BA_REL_ "GenSigTimeoutTime" BU_SG_REL_ VMCU SG_ 2432640832 ReverseWarning_rqst_ISig_4 120;
BA_REL_ "GenSigFirstTimeoutTime" BU_SG_REL_ IC3 SG_ 2432640832 BackLightDimming_Status 3000;
BA_REL_ "GenSigTimeoutTime" BU_SG_REL_ IC3 SG_ 2432640832 BackLightDimming_Status 120;
BA_REL_ "GenSigFirstTimeoutTime" BU_SG_REL_ IC3 SG_ 2432640832 BlackPanelMode_ButtonStatus 3000;
BA_REL_ "GenSigTimeoutTime" BU_SG_REL_ IC3 SG_ 2432640832 BlackPanelMode_ButtonStatus 120;
BA_REL_ "GenSigFirstTimeoutTime" BU_SG_REL_ EMS SG_ 2432661312 VIN_rqst_ISig_4 3000;
BA_REL_ "GenSigTimeoutTime" BU_SG_REL_ EMS SG_ 2432661312 VIN_rqst_ISig_4 120;
BA_REL_ "GenSigFirstTimeoutTime" BU_SG_REL_ TECU SG_ 2432661312 VIN_rqst_ISig_4 3000;
BA_REL_ "GenSigTimeoutTime" BU_SG_REL_ TECU SG_ 2432661312 VIN_rqst_ISig_4 120;
BA_REL_ "GenSigFirstTimeoutTime" BU_SG_REL_ IC3 SG_ 2432661312 VIN_rqst_ISig_4 3000;
BA_REL_ "GenSigTimeoutTime" BU_SG_REL_ IC3 SG_ 2432661312 VIN_rqst_ISig_4 120;
BA_REL_ "GenSigFirstTimeoutTime" BU_SG_REL_ VMCU SG_ 2432661312 VIN_rqst_ISig_4 3000;
BA_REL_ "GenSigTimeoutTime" BU_SG_REL_ VMCU SG_ 2432661312 VIN_rqst_ISig_4 600;
BA_REL_ "GenSigFirstTimeoutTime" BU_SG_REL_ IC3 SG_ 2432661312 FWSelectedSpeedControlMode 3000;
BA_REL_ "GenSigTimeoutTime" BU_SG_REL_ IC3 SG_ 2432661312 FWSelectedSpeedControlMode 120;
BA_REL_ "GenSigFirstTimeoutTime" BU_SG_REL_ VMCU SG_ 2432661312 FogLightFront_ButtonStatus_3 3000;
BA_REL_ "GenSigTimeoutTime" BU_SG_REL_ VMCU SG_ 2432661312 FogLightFront_ButtonStatus_3 600;
BA_REL_ "GenSigFirstTimeoutTime" BU_SG_REL_ VMCU SG_ 2432661312 InteriorLightDimming_rqst 3000;
BA_REL_ "GenSigTimeoutTime" BU_SG_REL_ VMCU SG_ 2432661312 InteriorLightDimming_rqst 600;
BA_REL_ "GenSigFirstTimeoutTime" BU_SG_REL_ IC3 SG_ 2432661312 InteriorLightDimming_rqst 3000;
BA_REL_ "GenSigTimeoutTime" BU_SG_REL_ IC3 SG_ 2432661312 InteriorLightDimming_rqst 120;
BA_REL_ "GenSigFirstTimeoutTime" BU_SG_REL_ VMCU SG_ 2432661312 FrAxleDiffLockActvnDriverRqst_IS 3000;
BA_REL_ "GenSigTimeoutTime" BU_SG_REL_ VMCU SG_ 2432661312 FrAxleDiffLockActvnDriverRqst_IS 600;
BA_REL_ "GenSigFirstTimeoutTime" BU_SG_REL_ VMCU SG_ 2432661312 AdjustFrontBeamInclination 3000;
BA_REL_ "GenSigTimeoutTime" BU_SG_REL_ VMCU SG_ 2432661312 AdjustFrontBeamInclination 600;
BA_REL_ "GenSigFirstTimeoutTime" BU_SG_REL_ VMCU SG_ 2432661312 LiftAxle2AutoLiftRequest_ISig_4 3000;
BA_REL_ "GenSigTimeoutTime" BU_SG_REL_ VMCU SG_ 2432661312 LiftAxle2AutoLiftRequest_ISig_4 600;
BA_REL_ "GenSigFirstTimeoutTime" BU_SG_REL_ VMCU SG_ 2432661312 AltLoadDistribution_rqst_ISig_4 3000;
BA_REL_ "GenSigTimeoutTime" BU_SG_REL_ VMCU SG_ 2432661312 AltLoadDistribution_rqst_ISig_4 600;
BA_REL_ "GenSigFirstTimeoutTime" BU_SG_REL_ VMCU SG_ 2432661312 FogLightRear_ButtonStatus_3 3000;
BA_REL_ "GenSigTimeoutTime" BU_SG_REL_ VMCU SG_ 2432661312 FogLightRear_ButtonStatus_3 600;
BA_REL_ "GenSigFirstTimeoutTime" BU_SG_REL_ VMCU SG_ 2432661312 LiftAxle2LiftPositionRequest_ISi 3000;
BA_REL_ "GenSigTimeoutTime" BU_SG_REL_ VMCU SG_ 2432661312 LiftAxle2LiftPositionRequest_ISi 600;
BA_REL_ "GenSigFirstTimeoutTime" BU_SG_REL_ VMCU SG_ 2432661312 TrailerBodyLamp_rqst 3000;
BA_REL_ "GenSigTimeoutTime" BU_SG_REL_ VMCU SG_ 2432661312 TrailerBodyLamp_rqst 600;
BA_REL_ "GenSigFirstTimeoutTime" BU_SG_REL_ VMCU SG_ 2432661312 LoadDistributionChangeRequest_IS 3000;
BA_REL_ "GenSigTimeoutTime" BU_SG_REL_ VMCU SG_ 2432661312 LoadDistributionChangeRequest_IS 600;
BA_REL_ "GenSigFirstTimeoutTime" BU_SG_REL_ VMCU SG_ 2432661312 LiftAxle1AutoLiftRequest_ISig_4 3000;
BA_REL_ "GenSigTimeoutTime" BU_SG_REL_ VMCU SG_ 2432661312 LiftAxle1AutoLiftRequest_ISig_4 600;
BA_REL_ "GenSigFirstTimeoutTime" BU_SG_REL_ VMCU SG_ 2432661312 LiftAxle1LiftPositionRequest_ISi 3000;
BA_REL_ "GenSigTimeoutTime" BU_SG_REL_ VMCU SG_ 2432661312 LiftAxle1LiftPositionRequest_ISi 600;
BA_REL_ "GenSigFirstTimeoutTime" BU_SG_REL_ IC3 SG_ 1355 BBPeriodicLog1Status_ISig_4 24000;
BA_REL_ "GenSigTimeoutTime" BU_SG_REL_ IC3 SG_ 1355 BBPeriodicLog1Status_ISig_4 6000;
BA_REL_ "GenSigFirstTimeoutTime" BU_SG_REL_ IC3 SG_ 1355 BBPeriodicLog4Status_ISig_4 24000;
BA_REL_ "GenSigTimeoutTime" BU_SG_REL_ IC3 SG_ 1355 BBPeriodicLog4Status_ISig_4 6000;
BA_REL_ "GenSigFirstTimeoutTime" BU_SG_REL_ IC3 SG_ 1355 BBEventLog4Status_ISig_4 24000;
BA_REL_ "GenSigTimeoutTime" BU_SG_REL_ IC3 SG_ 1355 BBEventLog4Status_ISig_4 6000;
BA_REL_ "GenSigFirstTimeoutTime" BU_SG_REL_ IC3 SG_ 1355 BBEventLog1Status_ISig_4 24000;
BA_REL_ "GenSigTimeoutTime" BU_SG_REL_ IC3 SG_ 1355 BBEventLog1Status_ISig_4 6000;
BA_REL_ "GenSigFirstTimeoutTime" BU_SG_REL_ IC3 SG_ 1355 BBEventLog7Status_ISig_4 24000;
BA_REL_ "GenSigTimeoutTime" BU_SG_REL_ IC3 SG_ 1355 BBEventLog7Status_ISig_4 6000;
BA_REL_ "GenSigFirstTimeoutTime" BU_SG_REL_ IC3 SG_ 1355 BBEventLog10Status_ISig_4 24000;
BA_REL_ "GenSigTimeoutTime" BU_SG_REL_ IC3 SG_ 1355 BBEventLog10Status_ISig_4 6000;
BA_REL_ "GenSigFirstTimeoutTime" BU_SG_REL_ IC3 SG_ 1355 BBRollingBufferLogStatus_ISig_4 24000;
BA_REL_ "GenSigTimeoutTime" BU_SG_REL_ IC3 SG_ 1355 BBRollingBufferLogStatus_ISig_4 6000;
BA_REL_ "GenSigFirstTimeoutTime" BU_SG_REL_ IC3 SG_ 1355 BBPeriodicLog2Status_ISig_4 24000;
BA_REL_ "GenSigTimeoutTime" BU_SG_REL_ IC3 SG_ 1355 BBPeriodicLog2Status_ISig_4 6000;
BA_REL_ "GenSigFirstTimeoutTime" BU_SG_REL_ IC3 SG_ 1355 BBEventLog6Status_ISig_4 24000;
BA_REL_ "GenSigTimeoutTime" BU_SG_REL_ IC3 SG_ 1355 BBEventLog6Status_ISig_4 6000;
BA_REL_ "GenSigFirstTimeoutTime" BU_SG_REL_ IC3 SG_ 1355 BBEventLog9Status_ISig_4 24000;
BA_REL_ "GenSigTimeoutTime" BU_SG_REL_ IC3 SG_ 1355 BBEventLog9Status_ISig_4 6000;
BA_REL_ "GenSigFirstTimeoutTime" BU_SG_REL_ IC3 SG_ 1355 BBFlexibleLoggingActive 24000;
BA_REL_ "GenSigTimeoutTime" BU_SG_REL_ IC3 SG_ 1355 BBFlexibleLoggingActive 6000;
BA_REL_ "GenSigFirstTimeoutTime" BU_SG_REL_ IC3 SG_ 1355 BBEventLog5Status_ISig_4 24000;
BA_REL_ "GenSigTimeoutTime" BU_SG_REL_ IC3 SG_ 1355 BBEventLog5Status_ISig_4 6000;
BA_REL_ "GenSigFirstTimeoutTime" BU_SG_REL_ IC3 SG_ 1355 BBPeriodicLog3Status_ISig_4 24000;
BA_REL_ "GenSigTimeoutTime" BU_SG_REL_ IC3 SG_ 1355 BBPeriodicLog3Status_ISig_4 6000;
BA_REL_ "GenSigFirstTimeoutTime" BU_SG_REL_ IC3 SG_ 1355 BBEventLog3Status_ISig_4 24000;
BA_REL_ "GenSigTimeoutTime" BU_SG_REL_ IC3 SG_ 1355 BBEventLog3Status_ISig_4 6000;
BA_REL_ "GenSigFirstTimeoutTime" BU_SG_REL_ IC3 SG_ 1355 BBEventLog2Status_ISig_4 24000;
BA_REL_ "GenSigTimeoutTime" BU_SG_REL_ IC3 SG_ 1355 BBEventLog2Status_ISig_4 6000;
BA_REL_ "GenSigFirstTimeoutTime" BU_SG_REL_ IC3 SG_ 1355 BBEventLog8Status_ISig_4 24000;
BA_REL_ "GenSigTimeoutTime" BU_SG_REL_ IC3 SG_ 1355 BBEventLog8Status_ISig_4 6000;
BA_REL_ "GenSigFirstTimeoutTime" BU_SG_REL_ DACU SG_ 2365554662 RSBBM_BBSystemChecksum 3000;
BA_REL_ "GenSigTimeoutTime" BU_SG_REL_ DACU SG_ 2365554662 RSBBM_BBSystemChecksum 120;
BA_REL_ "GenSigFirstTimeoutTime" BU_SG_REL_ DACU SG_ 2365554662 RSBBM_BBSystemFASReqControlMode 3000;
BA_REL_ "GenSigTimeoutTime" BU_SG_REL_ DACU SG_ 2365554662 RSBBM_BBSystemFASReqControlMode 120;
BA_REL_ "GenSigFirstTimeoutTime" BU_SG_REL_ DACU SG_ 2365554662 RSBBM_BBSystemCounter 3000;
BA_REL_ "GenSigTimeoutTime" BU_SG_REL_ DACU SG_ 2365554662 RSBBM_BBSystemCounter 120;
BA_REL_ "GenSigFirstTimeoutTime" BU_SG_REL_ DACU SG_ 2365554662 RSBBM_BBSystemFASAngleRequest 3000;
BA_REL_ "GenSigTimeoutTime" BU_SG_REL_ DACU SG_ 2365554662 RSBBM_BBSystemFASAngleRequest 120;
BA_REL_ "GenSigFirstTimeoutTime" BU_SG_REL_ IC3 SG_ 955 FdDiagStatus4_ISig_4 3000;
BA_REL_ "GenSigTimeoutTime" BU_SG_REL_ IC3 SG_ 955 FdDiagStatus4_ISig_4 270;
BA_REL_ "GenSigFirstTimeoutTime" BU_SG_REL_ IC3 SG_ 955 FdDiagStatus2_ISig_4 3000;
BA_REL_ "GenSigTimeoutTime" BU_SG_REL_ IC3 SG_ 955 FdDiagStatus2_ISig_4 270;
BA_REL_ "GenSigFirstTimeoutTime" BU_SG_REL_ IC3 SG_ 955 FdDiagStatus8_ISig_4 3000;
BA_REL_ "GenSigTimeoutTime" BU_SG_REL_ IC3 SG_ 955 FdDiagStatus8_ISig_4 270;
BA_REL_ "GenSigFirstTimeoutTime" BU_SG_REL_ IC3 SG_ 955 FdDiagStatus10_ISig_4 3000;
BA_REL_ "GenSigTimeoutTime" BU_SG_REL_ IC3 SG_ 955 FdDiagStatus10_ISig_4 270;
BA_REL_ "GenSigFirstTimeoutTime" BU_SG_REL_ IC3 SG_ 955 FdDiagStatus6_ISig_4 3000;
BA_REL_ "GenSigTimeoutTime" BU_SG_REL_ IC3 SG_ 955 FdDiagStatus6_ISig_4 270;
BA_REL_ "GenSigFirstTimeoutTime" BU_SG_REL_ IC3 SG_ 955 FdDiagStatus9_ISig_4 3000;
BA_REL_ "GenSigTimeoutTime" BU_SG_REL_ IC3 SG_ 955 FdDiagStatus9_ISig_4 270;
BA_REL_ "GenSigFirstTimeoutTime" BU_SG_REL_ IC3 SG_ 955 FdDiagStatus5_ISig_4 3000;
BA_REL_ "GenSigTimeoutTime" BU_SG_REL_ IC3 SG_ 955 FdDiagStatus5_ISig_4 270;
BA_REL_ "GenSigFirstTimeoutTime" BU_SG_REL_ IC3 SG_ 955 FdDiagStatus7_ISig_4 3000;
BA_REL_ "GenSigTimeoutTime" BU_SG_REL_ IC3 SG_ 955 FdDiagStatus7_ISig_4 270;
BA_REL_ "GenSigFirstTimeoutTime" BU_SG_REL_ IC3 SG_ 955 FdDiagStatus1_ISig_4 3000;
BA_REL_ "GenSigTimeoutTime" BU_SG_REL_ IC3 SG_ 955 FdDiagStatus1_ISig_4 270;
BA_REL_ "GenSigFirstTimeoutTime" BU_SG_REL_ IC3 SG_ 955 FdDiagStatus3_ISig_4 3000;
BA_REL_ "GenSigTimeoutTime" BU_SG_REL_ IC3 SG_ 955 FdDiagStatus3_ISig_4 270;
BA_REL_ "GenSigFirstTimeoutTime" BU_SG_REL_ VMCU SG_ 2550057702 RFBEngineStopAllowed 6000;
BA_REL_ "GenSigTimeoutTime" BU_SG_REL_ VMCU SG_ 2550057702 RFBEngineStopAllowed 1500;
BA_REL_ "GenSigFirstTimeoutTime" BU_SG_REL_ VMCU SG_ 2550057702 PreTSC1BsTr_EnOvrdCtrlM 6000;
BA_REL_ "GenSigTimeoutTime" BU_SG_REL_ VMCU SG_ 2550057702 PreTSC1BsTr_EnOvrdCtrlM 1500;
BA_REL_ "GenSigFirstTimeoutTime" BU_SG_REL_ VMCU SG_ 2550057702 BrakeAndPark_ind 6000;
BA_REL_ "GenSigTimeoutTime" BU_SG_REL_ VMCU SG_ 2550057702 BrakeAndPark_ind 1500;
BA_REL_ "GenSigFirstTimeoutTime" BU_SG_REL_ VMCU SG_ 2550057702 PreTSC1BsTr_EnRTrqTrqLm 6000;
BA_REL_ "GenSigTimeoutTime" BU_SG_REL_ VMCU SG_ 2550057702 PreTSC1BsTr_EnRTrqTrqLm 1500;
BA_REL_ "GenSigFirstTimeoutTime" BU_SG_REL_ VMCU SG_ 2550057702 VehicleImmobilization_ind 6000;
BA_REL_ "GenSigTimeoutTime" BU_SG_REL_ VMCU SG_ 2550057702 VehicleImmobilization_ind 1500;
BA_REL_ "GenSigFirstTimeoutTime" BU_SG_REL_ IC3 SG_ 2550057702 FullBrakes_ind_ISig_4 6000;
BA_REL_ "GenSigTimeoutTime" BU_SG_REL_ IC3 SG_ 2550057702 FullBrakes_ind_ISig_4 1500;
BA_REL_ "GenSigFirstTimeoutTime" BU_SG_REL_ VMCU SG_ 2550057702 PtoTorqueRequest 6000;
BA_REL_ "GenSigTimeoutTime" BU_SG_REL_ VMCU SG_ 2550057702 PtoTorqueRequest 1500;
BA_REL_ "GenSigFirstTimeoutTime" BU_SG_REL_ CIOM SG_ 2481984998 TipperConditionsStatus_ISig_4 3000;
BA_REL_ "GenSigTimeoutTime" BU_SG_REL_ CIOM SG_ 2481984998 TipperConditionsStatus_ISig_4 300;
BA_REL_ "GenSigFirstTimeoutTime" BU_SG_REL_ CIOM SG_ 2481984998 TailLiftRemoteNotAllowed_ISig_4 3000;
BA_REL_ "GenSigTimeoutTime" BU_SG_REL_ CIOM SG_ 2481984998 TailLiftRemoteNotAllowed_ISig_4 300;
BA_REL_ "GenSigFirstTimeoutTime" BU_SG_REL_ CIOM SG_ 2481984998 TipperTarpaulinStatus_ISig_4 3000;
BA_REL_ "GenSigTimeoutTime" BU_SG_REL_ CIOM SG_ 2481984998 TipperTarpaulinStatus_ISig_4 300;
BA_REL_ "GenSigFirstTimeoutTime" BU_SG_REL_ IC3 SG_ 2481984998 TipperAutoLowering 3000;
BA_REL_ "GenSigTimeoutTime" BU_SG_REL_ IC3 SG_ 2481984998 TipperAutoLowering 300;
BA_REL_ "GenSigFirstTimeoutTime" BU_SG_REL_ VMCU SG_ 2481984998 DirInd_Plough_Status 3000;
BA_REL_ "GenSigTimeoutTime" BU_SG_REL_ VMCU SG_ 2481984998 DirInd_Plough_Status 300;
BA_REL_ "GenSigFirstTimeoutTime" BU_SG_REL_ CIOM SG_ 2481984998 TipperShakerStatus_ISig_4 3000;
BA_REL_ "GenSigTimeoutTime" BU_SG_REL_ CIOM SG_ 2481984998 TipperShakerStatus_ISig_4 300;
BA_REL_ "GenSigFirstTimeoutTime" BU_SG_REL_ CIOM SG_ 2481984998 TipperEmergencyStopStatus_ISig_4 3000;
BA_REL_ "GenSigTimeoutTime" BU_SG_REL_ CIOM SG_ 2481984998 TipperEmergencyStopStatus_ISig_4 300;
BA_REL_ "GenSigFirstTimeoutTime" BU_SG_REL_ CIOM SG_ 2481984998 TipperSecondaryBodyStatus_ISig_4 3000;
BA_REL_ "GenSigTimeoutTime" BU_SG_REL_ CIOM SG_ 2481984998 TipperSecondaryBodyStatus_ISig_4 300;
BA_REL_ "GenSigFirstTimeoutTime" BU_SG_REL_ CIOM SG_ 2481984998 TipperPrimaryBodyStatus_ISig_4 3000;
BA_REL_ "GenSigTimeoutTime" BU_SG_REL_ CIOM SG_ 2481984998 TipperPrimaryBodyStatus_ISig_4 300;
BA_REL_ "GenSigFirstTimeoutTime" BU_SG_REL_ VMCU SG_ 2481984998 AuxSwitchBbLoad5Feedback 3000;
BA_REL_ "GenSigTimeoutTime" BU_SG_REL_ VMCU SG_ 2481984998 AuxSwitchBbLoad5Feedback 300;
BA_REL_ "GenSigFirstTimeoutTime" BU_SG_REL_ VMCU SG_ 2481984998 AuxSwitchBbLoad3Feedback 3000;
BA_REL_ "GenSigTimeoutTime" BU_SG_REL_ VMCU SG_ 2481984998 AuxSwitchBbLoad3Feedback 300;
BA_REL_ "GenSigFirstTimeoutTime" BU_SG_REL_ CIOM SG_ 2481984998 TailLiftMotionStatus_ISig_4 3000;
BA_REL_ "GenSigTimeoutTime" BU_SG_REL_ CIOM SG_ 2481984998 TailLiftMotionStatus_ISig_4 300;
BA_REL_ "GenSigFirstTimeoutTime" BU_SG_REL_ VMCU SG_ 2481984998 AuxSwitchBbLoad4Feedback 3000;
BA_REL_ "GenSigTimeoutTime" BU_SG_REL_ VMCU SG_ 2481984998 AuxSwitchBbLoad4Feedback 300;
BA_REL_ "GenSigFirstTimeoutTime" BU_SG_REL_ CIOM SG_ 2481984998 TipperUpDownStatus_ISig_4 3000;
BA_REL_ "GenSigTimeoutTime" BU_SG_REL_ CIOM SG_ 2481984998 TipperUpDownStatus_ISig_4 300;
BA_REL_ "GenSigFirstTimeoutTime" BU_SG_REL_ CIOM SG_ 2481984998 TailLiftConditionsStatus_ISig_4 3000;
BA_REL_ "GenSigTimeoutTime" BU_SG_REL_ CIOM SG_ 2481984998 TailLiftConditionsStatus_ISig_4 300;
BA_REL_ "GenSigFirstTimeoutTime" BU_SG_REL_ VMCU SG_ 2481984998 AuxSwitchBbLoad6Feedback 3000;
BA_REL_ "GenSigTimeoutTime" BU_SG_REL_ VMCU SG_ 2481984998 AuxSwitchBbLoad6Feedback 300;
BA_REL_ "GenSigFirstTimeoutTime" BU_SG_REL_ CIOM SG_ 2481984998 TipperTailGateStatus_ISig_4 3000;
BA_REL_ "GenSigTimeoutTime" BU_SG_REL_ CIOM SG_ 2481984998 TipperTailGateStatus_ISig_4 300;
BA_REL_ "GenSigFirstTimeoutTime" BU_SG_REL_ VMCU SG_ 2481984998 CTA_PBReleaseInhibit_rqst 3000;
BA_REL_ "GenSigTimeoutTime" BU_SG_REL_ VMCU SG_ 2481984998 CTA_PBReleaseInhibit_rqst 500;
BA_REL_ "GenSigFirstTimeoutTime" BU_SG_REL_ TECU SG_ 2466201830 CtaGcReverseInhibit 3000;
BA_REL_ "GenSigTimeoutTime" BU_SG_REL_ TECU SG_ 2466201830 CtaGcReverseInhibit 180;
BA_REL_ "GenSigFirstTimeoutTime" BU_SG_REL_ VMCU SG_ 2466201830 BBSystemProhibitControlRequest_I 3000;
BA_REL_ "GenSigTimeoutTime" BU_SG_REL_ VMCU SG_ 2466201830 BBSystemProhibitControlRequest_I 180;
BA_REL_ "GenSigFirstTimeoutTime" BU_SG_REL_ VMCU SG_ 2466201830 BBUSecondDriverInterfEnable_ISig 3000;
BA_REL_ "GenSigTimeoutTime" BU_SG_REL_ VMCU SG_ 2466201830 BBUSecondDriverInterfEnable_ISig 500;
BA_REL_ "GenSigFirstTimeoutTime" BU_SG_REL_ VMCU SG_ 2466201830 SecondDriverInterfEnableInput 3000;
BA_REL_ "GenSigTimeoutTime" BU_SG_REL_ VMCU SG_ 2466201830 SecondDriverInterfEnableInput 180;
BA_REL_ "GenSigFirstTimeoutTime" BU_SG_REL_ VMCU SG_ 2466201830 XPRRequest_RBS_ISig_4 3000;
BA_REL_ "GenSigTimeoutTime" BU_SG_REL_ VMCU SG_ 2466201830 XPRRequest_RBS_ISig_4 180;
BA_REL_ "GenSigFirstTimeoutTime" BU_SG_REL_ TECU SG_ 2466201830 CtaGcInhibitGearEngaged 3000;
BA_REL_ "GenSigTimeoutTime" BU_SG_REL_ TECU SG_ 2466201830 CtaGcInhibitGearEngaged 180;
BA_REL_ "GenSigFirstTimeoutTime" BU_SG_REL_ VMCU SG_ 2466201830 EscChassisEngineSpdMode4 3000;
BA_REL_ "GenSigTimeoutTime" BU_SG_REL_ VMCU SG_ 2466201830 EscChassisEngineSpdMode4 180;
BA_REL_ "GenSigFirstTimeoutTime" BU_SG_REL_ VMCU SG_ 2466201830 SecondAcceleratorPedalPosition 3000;
BA_REL_ "GenSigTimeoutTime" BU_SG_REL_ VMCU SG_ 2466201830 SecondAcceleratorPedalPosition 180;
BA_REL_ "GenSigFirstTimeoutTime" BU_SG_REL_ VMCU SG_ 2466201830 SecondaryAccelPedalQuality 3000;
BA_REL_ "GenSigTimeoutTime" BU_SG_REL_ VMCU SG_ 2466201830 SecondaryAccelPedalQuality 180;
BA_REL_ "GenSigFirstTimeoutTime" BU_SG_REL_ VMCU SG_ 2466201830 BBSystemKneelRequest_ISig_4 3000;
BA_REL_ "GenSigTimeoutTime" BU_SG_REL_ VMCU SG_ 2466201830 BBSystemKneelRequest_ISig_4 180;
BA_REL_ "GenSigFirstTimeoutTime" BU_SG_REL_ VMCU SG_ 2466201830 BBSystemAlternatLoadDistribReq_I 3000;
BA_REL_ "GenSigTimeoutTime" BU_SG_REL_ VMCU SG_ 2466201830 BBSystemAlternatLoadDistribReq_I 500;
BA_REL_ "GenSigFirstTimeoutTime" BU_SG_REL_ VMCU SG_ 2466201830 EscChassisEngineSpdMode3 3000;
BA_REL_ "GenSigTimeoutTime" BU_SG_REL_ VMCU SG_ 2466201830 EscChassisEngineSpdMode3 180;
BA_REL_ "GenSigFirstTimeoutTime" BU_SG_REL_ VMCU SG_ 2466201830 CtaGcSecondGearLeverPosition_ISi 3000;
BA_REL_ "GenSigTimeoutTime" BU_SG_REL_ VMCU SG_ 2466201830 CtaGcSecondGearLeverPosition_ISi 180;
BA_REL_ "GenSigFirstTimeoutTime" BU_SG_REL_ TECU SG_ 2466201830 CtaGcAlternativeGearStarter 3000;
BA_REL_ "GenSigTimeoutTime" BU_SG_REL_ TECU SG_ 2466201830 CtaGcAlternativeGearStarter 180;
BA_REL_ "GenSigFirstTimeoutTime" BU_SG_REL_ VMCU SG_ 2466201830 EscChassisEngineSpdMode2 3000;
BA_REL_ "GenSigTimeoutTime" BU_SG_REL_ VMCU SG_ 2466201830 EscChassisEngineSpdMode2 180;
BA_REL_ "GenSigFirstTimeoutTime" BU_SG_REL_ VMCU SG_ 2466201830 SecondaryAccelPedalKickDown 3000;
BA_REL_ "GenSigTimeoutTime" BU_SG_REL_ VMCU SG_ 2466201830 SecondaryAccelPedalKickDown 180;
BA_REL_ "GenSigFirstTimeoutTime" BU_SG_REL_ VMCU SG_ 2466201830 SecondAcceleratorPedalStatus 3000;
BA_REL_ "GenSigTimeoutTime" BU_SG_REL_ VMCU SG_ 2466201830 SecondAcceleratorPedalStatus 180;
BA_REL_ "GenSigFirstTimeoutTime" BU_SG_REL_ VMCU SG_ 2466201830 GCRemoteEsc_rqst 3000;
BA_REL_ "GenSigTimeoutTime" BU_SG_REL_ VMCU SG_ 2466201830 GCRemoteEsc_rqst 180;
BA_REL_ "GenSigFirstTimeoutTime" BU_SG_REL_ VMCU SG_ 2466201830 EscChassisEngineSpdMode1 3000;
BA_REL_ "GenSigTimeoutTime" BU_SG_REL_ VMCU SG_ 2466201830 EscChassisEngineSpdMode1 180;
BA_REL_ "GenSigFirstTimeoutTime" BU_SG_REL_ VMCU SG_ 2466201830 BBSystemSpeedDepDriveLevelReq_IS 3000;
BA_REL_ "GenSigTimeoutTime" BU_SG_REL_ VMCU SG_ 2466201830 BBSystemSpeedDepDriveLevelReq_IS 180;
BA_REL_ "GenSigFirstTimeoutTime" BU_SG_REL_ IC3 SG_ 2466239718 RssRemoteStopEngine_rqst 3000;
BA_REL_ "GenSigTimeoutTime" BU_SG_REL_ IC3 SG_ 2466239718 RssRemoteStopEngine_rqst 270;
BA_REL_ "GenSigFirstTimeoutTime" BU_SG_REL_ VMCU SG_ 2466239718 RssRemoteStopEngine_rqst 3000;
BA_REL_ "GenSigTimeoutTime" BU_SG_REL_ VMCU SG_ 2466239718 RssRemoteStopEngine_rqst 270;
BA_REL_ "GenSigFirstTimeoutTime" BU_SG_REL_ VMCU SG_ 2466239718 RSL2requestStatus 3000;
BA_REL_ "GenSigTimeoutTime" BU_SG_REL_ VMCU SG_ 2466239718 RSL2requestStatus 270;
BA_REL_ "GenSigFirstTimeoutTime" BU_SG_REL_ IC3 SG_ 2466239718 FdEquipmentStatus2_ISig_4 3000;
BA_REL_ "GenSigTimeoutTime" BU_SG_REL_ IC3 SG_ 2466239718 FdEquipmentStatus2_ISig_4 270;
BA_REL_ "GenSigFirstTimeoutTime" BU_SG_REL_ CIOM SG_ 2466239718 FdEquipmentStatus2_ISig_4 6000;
BA_REL_ "GenSigTimeoutTime" BU_SG_REL_ CIOM SG_ 2466239718 FdEquipmentStatus2_ISig_4 6000;
BA_REL_ "GenSigFirstTimeoutTime" BU_SG_REL_ VMCU SG_ 2466239718 RssRemoteStartEngine_rqst 3000;
BA_REL_ "GenSigTimeoutTime" BU_SG_REL_ VMCU SG_ 2466239718 RssRemoteStartEngine_rqst 270;
BA_REL_ "GenSigFirstTimeoutTime" BU_SG_REL_ CIOM SG_ 2466239718 BBNetwBeaconLight_stat 6000;
BA_REL_ "GenSigTimeoutTime" BU_SG_REL_ CIOM SG_ 2466239718 BBNetwBeaconLight_stat 6000;
BA_REL_ "GenSigFirstTimeoutTime" BU_SG_REL_ VMCU SG_ 2466239718 Pto2RemoteRequest 3000;
BA_REL_ "GenSigTimeoutTime" BU_SG_REL_ VMCU SG_ 2466239718 Pto2RemoteRequest 270;
BA_REL_ "GenSigFirstTimeoutTime" BU_SG_REL_ CIOM SG_ 2466239718 FdEquipmentValue1_ISig_4 6000;
BA_REL_ "GenSigTimeoutTime" BU_SG_REL_ CIOM SG_ 2466239718 FdEquipmentValue1_ISig_4 6000;
BA_REL_ "GenSigFirstTimeoutTime" BU_SG_REL_ IC3 SG_ 2466239718 FdEquipmentValue1_ISig_4 3000;
BA_REL_ "GenSigTimeoutTime" BU_SG_REL_ IC3 SG_ 2466239718 FdEquipmentValue1_ISig_4 270;
BA_REL_ "GenSigFirstTimeoutTime" BU_SG_REL_ VMCU SG_ 2466239718 Pto1RemoteRequest 3000;
BA_REL_ "GenSigTimeoutTime" BU_SG_REL_ VMCU SG_ 2466239718 Pto1RemoteRequest 270;
BA_REL_ "GenSigFirstTimeoutTime" BU_SG_REL_ VMCU SG_ 2466239718 Pto3RemoteRequest 3000;
BA_REL_ "GenSigTimeoutTime" BU_SG_REL_ VMCU SG_ 2466239718 Pto3RemoteRequest 270;
BA_REL_ "GenSigFirstTimeoutTime" BU_SG_REL_ IC3 SG_ 2466239718 FdEquipmentValue2_ISig_4 3000;
BA_REL_ "GenSigTimeoutTime" BU_SG_REL_ IC3 SG_ 2466239718 FdEquipmentValue2_ISig_4 270;
BA_REL_ "GenSigFirstTimeoutTime" BU_SG_REL_ CIOM SG_ 2466239718 FdEquipmentValue2_ISig_4 6000;
BA_REL_ "GenSigTimeoutTime" BU_SG_REL_ CIOM SG_ 2466239718 FdEquipmentValue2_ISig_4 6000;
BA_REL_ "GenSigFirstTimeoutTime" BU_SG_REL_ VMCU SG_ 2466239718 BBHazardWarning_rqst 3000;
BA_REL_ "GenSigTimeoutTime" BU_SG_REL_ VMCU SG_ 2466239718 BBHazardWarning_rqst 270;
BA_REL_ "GenSigFirstTimeoutTime" BU_SG_REL_ CIOM SG_ 2466239718 FdEquipmentStatus5_ISig_4 6000;
BA_REL_ "GenSigTimeoutTime" BU_SG_REL_ CIOM SG_ 2466239718 FdEquipmentStatus5_ISig_4 6000;
BA_REL_ "GenSigFirstTimeoutTime" BU_SG_REL_ IC3 SG_ 2466239718 FdEquipmentStatus5_ISig_4 3000;
BA_REL_ "GenSigTimeoutTime" BU_SG_REL_ IC3 SG_ 2466239718 FdEquipmentStatus5_ISig_4 270;
BA_REL_ "GenSigFirstTimeoutTime" BU_SG_REL_ VMCU SG_ 2466239718 RssInhibitStartEngFromBB_rqst 3000;
BA_REL_ "GenSigTimeoutTime" BU_SG_REL_ VMCU SG_ 2466239718 RssInhibitStartEngFromBB_rqst 270;
BA_REL_ "GenSigFirstTimeoutTime" BU_SG_REL_ CIOM SG_ 2466239718 BBNetwExtraSWrknLight_stat 6000;
BA_REL_ "GenSigTimeoutTime" BU_SG_REL_ CIOM SG_ 2466239718 BBNetwExtraSWrknLight_stat 6000;
BA_REL_ "GenSigFirstTimeoutTime" BU_SG_REL_ IC3 SG_ 2466239718 FdEquipmentStatus4_ISig_4 3000;
BA_REL_ "GenSigTimeoutTime" BU_SG_REL_ IC3 SG_ 2466239718 FdEquipmentStatus4_ISig_4 270;
BA_REL_ "GenSigFirstTimeoutTime" BU_SG_REL_ CIOM SG_ 2466239718 FdEquipmentStatus4_ISig_4 6000;
BA_REL_ "GenSigTimeoutTime" BU_SG_REL_ CIOM SG_ 2466239718 FdEquipmentStatus4_ISig_4 6000;
BA_REL_ "GenSigFirstTimeoutTime" BU_SG_REL_ CIOM SG_ 2466239718 FdEquipmentStatus3_ISig_4 6000;
BA_REL_ "GenSigTimeoutTime" BU_SG_REL_ CIOM SG_ 2466239718 FdEquipmentStatus3_ISig_4 6000;
BA_REL_ "GenSigFirstTimeoutTime" BU_SG_REL_ IC3 SG_ 2466239718 FdEquipmentStatus3_ISig_4 3000;
BA_REL_ "GenSigTimeoutTime" BU_SG_REL_ IC3 SG_ 2466239718 FdEquipmentStatus3_ISig_4 270;
BA_REL_ "GenSigFirstTimeoutTime" BU_SG_REL_ CIOM SG_ 2466239718 BBNetwWrknLightChassis_stat 6000;
BA_REL_ "GenSigTimeoutTime" BU_SG_REL_ CIOM SG_ 2466239718 BBNetwWrknLightChassis_stat 6000;
BA_REL_ "GenSigFirstTimeoutTime" BU_SG_REL_ CIOM SG_ 2466239718 BBNetwBodyOrCabWrknLight_stat 6000;
BA_REL_ "GenSigTimeoutTime" BU_SG_REL_ CIOM SG_ 2466239718 BBNetwBodyOrCabWrknLight_stat 6000;
BA_REL_ "GenSigFirstTimeoutTime" BU_SG_REL_ CIOM SG_ 2466239718 BBNetwTrailerBodyLighting_rqst 6000;
BA_REL_ "GenSigTimeoutTime" BU_SG_REL_ CIOM SG_ 2466239718 BBNetwTrailerBodyLighting_rqst 6000;
BA_REL_ "GenSigFirstTimeoutTime" BU_SG_REL_ VMCU SG_ 2466239718 Pto4RemoteRequest 3000;
BA_REL_ "GenSigTimeoutTime" BU_SG_REL_ VMCU SG_ 2466239718 Pto4RemoteRequest 270;
BA_REL_ "GenSigFirstTimeoutTime" BU_SG_REL_ VMCU SG_ 2466239718 Pto3FeedbackStatus 3000;
BA_REL_ "GenSigTimeoutTime" BU_SG_REL_ VMCU SG_ 2466239718 Pto3FeedbackStatus 270;
BA_REL_ "GenSigFirstTimeoutTime" BU_SG_REL_ IC3 SG_ 2466239718 FdEquipmentValue3_ISig_4 3000;
BA_REL_ "GenSigTimeoutTime" BU_SG_REL_ IC3 SG_ 2466239718 FdEquipmentValue3_ISig_4 270;
BA_REL_ "GenSigFirstTimeoutTime" BU_SG_REL_ CIOM SG_ 2466239718 FdEquipmentValue3_ISig_4 6000;
BA_REL_ "GenSigTimeoutTime" BU_SG_REL_ CIOM SG_ 2466239718 FdEquipmentValue3_ISig_4 6000;
BA_REL_ "GenSigFirstTimeoutTime" BU_SG_REL_ VMCU SG_ 2466217958 EscChassisActivationRequest 3000;
BA_REL_ "GenSigTimeoutTime" BU_SG_REL_ VMCU SG_ 2466217958 EscChassisActivationRequest 270;
BA_REL_ "GenSigFirstTimeoutTime" BU_SG_REL_ VMCU SG_ 2466217958 EscChassisTargetRequest 3000;
BA_REL_ "GenSigTimeoutTime" BU_SG_REL_ VMCU SG_ 2466217958 EscChassisTargetRequest 270;
BA_REL_ "GenSigFirstTimeoutTime" BU_SG_REL_ CIOM SG_ 2466217958 PloughLampModeStatus_ISig_4 6000;
BA_REL_ "GenSigTimeoutTime" BU_SG_REL_ CIOM SG_ 2466217958 PloughLampModeStatus_ISig_4 6000;
BA_REL_ "GenSigFirstTimeoutTime" BU_SG_REL_ VMCU SG_ 2466217958 PloughLampModeStatus_ISig_4 3000;
BA_REL_ "GenSigTimeoutTime" BU_SG_REL_ VMCU SG_ 2466217958 PloughLampModeStatus_ISig_4 270;
BA_REL_ "GenSigFirstTimeoutTime" BU_SG_REL_ IC3 SG_ 2466217958 PloughLampModeStatus_ISig_4 3000;
BA_REL_ "GenSigTimeoutTime" BU_SG_REL_ IC3 SG_ 2466217958 PloughLampModeStatus_ISig_4 270;
BA_REL_ "GenSigFirstTimeoutTime" BU_SG_REL_ DACU SG_ 2466217958 PloughLampModeStatus_ISig_4 3000;
BA_REL_ "GenSigTimeoutTime" BU_SG_REL_ DACU SG_ 2466217958 PloughLampModeStatus_ISig_4 600;
BA_REL_ "GenSigFirstTimeoutTime" BU_SG_REL_ CIOM SG_ 2466217958 CtaBB_Horn_rqst 6000;
BA_REL_ "GenSigTimeoutTime" BU_SG_REL_ CIOM SG_ 2466217958 CtaBB_Horn_rqst 6000;
BA_REL_ "GenSigFirstTimeoutTime" BU_SG_REL_ VMCU SG_ 2466217958 EscChassisEngineSpdSelection 3000;
BA_REL_ "GenSigTimeoutTime" BU_SG_REL_ VMCU SG_ 2466217958 EscChassisEngineSpdSelection 270;
BA_REL_ "GenSigFirstTimeoutTime" BU_SG_REL_ VMCU SG_ 2466217958 EscChassisActionRequest 3000;
BA_REL_ "GenSigTimeoutTime" BU_SG_REL_ VMCU SG_ 2466217958 EscChassisActionRequest 270;
BA_REL_ "GenSigFirstTimeoutTime" BU_SG_REL_ VMCU SG_ 2466217958 EscChassisMaxEngineTorque_rqst 3000;
BA_REL_ "GenSigTimeoutTime" BU_SG_REL_ VMCU SG_ 2466217958 EscChassisMaxEngineTorque_rqst 270;
BA_REL_ "GenSigFirstTimeoutTime" BU_SG_REL_ VMCU SG_ 2466217958 EscChassisMaxEngineSpeed_rqst 3000;
BA_REL_ "GenSigTimeoutTime" BU_SG_REL_ VMCU SG_ 2466217958 EscChassisMaxEngineSpeed_rqst 270;
BA_REL_ "GenSigFirstTimeoutTime" BU_SG_REL_ VMCU SG_ 2466217958 EscChassisEnable 3000;
BA_REL_ "GenSigTimeoutTime" BU_SG_REL_ VMCU SG_ 2466217958 EscChassisEnable 270;
BA_REL_ "GenSigFirstTimeoutTime" BU_SG_REL_ IC3 SG_ 2466217958 CtaBs_VehicleImmobilizationCmd_I 3000;
BA_REL_ "GenSigTimeoutTime" BU_SG_REL_ IC3 SG_ 2466217958 CtaBs_VehicleImmobilizationCmd_I 270;
BA_REL_ "GenSigFirstTimeoutTime" BU_SG_REL_ VMCU SG_ 2466217958 BBRslBBRoadSpeedLimit_ISig_4 3000;
BA_REL_ "GenSigTimeoutTime" BU_SG_REL_ VMCU SG_ 2466217958 BBRslBBRoadSpeedLimit_ISig_4 270;
VAL_ 2482973248 FPBRChangeReq_ISig_4 3 "FPBRChangeReq_NotAvailable" 2 "FPBRChangeReq_Error" 1 "FPBRChangeReq_ChangeFPBRFunction" 0 "FPBRChangeReq_TakeNoAction" ;
VAL_ 2482973248 HeadLampUpDown_SwitchStatus 7 "A3PosSwitchStatus_NotAvailable" 6 "A3PosSwitchStatus_Error" 5 "A3PosSwitchStatus_Spare_02" 4 "A3PosSwitchStatus_Spare_01" 3 "A3PosSwitchStatus_Spare" 2 "A3PosSwitchStatus_Upper" 1 "A3PosSwitchStatus_Lower" 0 "A3PosSwitchStatus_Middle" ;
VAL_ 2482973248 Recirc_ButtonStatus_ISig_4 3 "PushButtonStatus_NotAvailable" 2 "PushButtonStatus_Error" 1 "PushButtonStatus_Pushed" 0 "PushButtonStatus_Neutral" ;
VAL_ 2482973248 Auto_ButtonStatus_ISig_4 3 "PushButtonStatus_NotAvailable" 2 "PushButtonStatus_Error" 1 "PushButtonStatus_Pushed" 0 "PushButtonStatus_Neutral" ;
VAL_ 2482973248 AirFlowSelectionFrontBtn_stat_IS 3 "PushButtonStatus_NotAvailable" 2 "PushButtonStatus_Error" 1 "PushButtonStatus_Pushed" 0 "PushButtonStatus_Neutral" ;
VAL_ 2482973248 InteriorLightMode_rqst_IL_Mode 7 "IL_ModeReq_NotAvailable" 6 "IL_ModeReq_ErrorIndicator" 5 "IL_ModeReq_NonHMIModeMax" 4 "IL_ModeReq_NonHMIModeResting" 3 "IL_ModeReq_Max" 2 "IL_ModeReq_Resting" 1 "IL_ModeReq_NightDriving" 0 "IL_ModeReq_OFF" ;
VAL_ 2482973248 InteriorLightMode_rqst_EventFlag 1 "EventFlag_High" 0 "EventFlag_Low" ;
VAL_ 2482973248 BlackOutConvoyModeSwitchStatus 7 "A3PosSwitchStatus_NotAvailable" 6 "A3PosSwitchStatus_Error" 5 "A3PosSwitchStatus_Spare_02" 4 "A3PosSwitchStatus_Spare_01" 3 "A3PosSwitchStatus_Spare" 2 "A3PosSwitchStatus_Upper" 1 "A3PosSwitchStatus_Lower" 0 "A3PosSwitchStatus_Middle" ;
VAL_ 2482973248 Indicator_Lights_Alarm_rqst_ISig 7 "Indicator_Lights_Alarm_rqst_NotAvailable" 6 "Indicator_Lights_Alarm_rqst_Error" 5 "Indicator_Lights_Alarm_rqst_Spare_02" 4 "Indicator_Lights_Alarm_rqst_Spare_01" 3 "Indicator_Lights_Alarm_rqst_Spare" 2 "Indicator_Lights_Alarm_rqst_DeactivateIndLightsNoWarnings" 1 "Indicator_Lights_Alarm_rqst_ActivateIndicatorLightsWarnings" 0 "Indicator_Lights_Alarm_rqst_Idle" ;
VAL_ 2482973248 AirFlowSelectionDownBtn_stat_ISi 3 "PushButtonStatus_NotAvailable" 2 "PushButtonStatus_Error" 1 "PushButtonStatus_Pushed" 0 "PushButtonStatus_Neutral" ;
VAL_ 2482973248 ParkingHeater_IndicationCmd_ISig 1 "IndicationCmd_ONLEDActivated" 0 "IndicationCmd_OFFLEDNotActivated" ;
VAL_ 2482973248 AirFlowSelectionUpBtn_stat_ISig_ 3 "PushButtonStatus_NotAvailable" 2 "PushButtonStatus_Error" 1 "PushButtonStatus_Pushed" 0 "PushButtonStatus_Neutral" ;
VAL_ 2482973248 ApproachLight_HMI_rqst 3 "InactiveActive_NotAvailable" 2 "InactiveActive_Error" 1 "InactiveActive_Active" 0 "InactiveActive_Inactive" ;
VAL_ 2482973248 Temperature_FreeWheelStatus_ISig 15 "FreeWheel_Status_NotAvailable" 14 "FreeWheel_Status_Error" 13 "FreeWheel_Status_Spare" 12 "FreeWheel_Status_6StepsCounterClockwise" 11 "FreeWheel_Status_5StepsCounterClockwise" 10 "FreeWheel_Status_4StepsCounterClockwise" 9 "FreeWheel_Status_3StepsCounterClockwise" 8 "FreeWheel_Status_2StepsCounterClockwise" 7 "FreeWheel_Status_1StepCounterClockwise" 6 "FreeWheel_Status_6StepsClockwise" 5 "FreeWheel_Status_5StepsClockwise" 4 "FreeWheel_Status_4StepsClockwise" 3 "FreeWheel_Status_3StepsClockwise" 2 "FreeWheel_Status_2StepsClockwise" 1 "FreeWheel_Status_1StepClockwise" 0 "FreeWheel_Status_NoMovement" ;
VAL_ 2482973248 AirBlowerSpeed_FreeWheelStatus_I 15 "FreeWheel_Status_NotAvailable" 14 "FreeWheel_Status_Error" 13 "FreeWheel_Status_Spare" 12 "FreeWheel_Status_6StepsCounterClockwise" 11 "FreeWheel_Status_5StepsCounterClockwise" 10 "FreeWheel_Status_4StepsCounterClockwise" 9 "FreeWheel_Status_3StepsCounterClockwise" 8 "FreeWheel_Status_2StepsCounterClockwise" 7 "FreeWheel_Status_1StepCounterClockwise" 6 "FreeWheel_Status_6StepsClockwise" 5 "FreeWheel_Status_5StepsClockwise" 4 "FreeWheel_Status_4StepsClockwise" 3 "FreeWheel_Status_3StepsClockwise" 2 "FreeWheel_Status_2StepsClockwise" 1 "FreeWheel_Status_1StepClockwise" 0 "FreeWheel_Status_NoMovement" ;
VAL_ 2482973248 ParkHeaterCooler_ButtonStatus_IS 3 "PushButtonStatus_NotAvailable" 2 "PushButtonStatus_Error" 1 "PushButtonStatus_Pushed" 0 "PushButtonStatus_Neutral" ;
VAL_ 2482973248 WindscreenDefrost_ButtonStatus_I 3 "PushButtonStatus_NotAvailable" 2 "PushButtonStatus_Error" 1 "PushButtonStatus_Pushed" 0 "PushButtonStatus_Neutral" ;
VAL_ 2482973248 AC_ButtonStatus_ISig_4 3 "PushButtonStatus_NotAvailable" 2 "PushButtonStatus_Error" 1 "PushButtonStatus_Pushed" 0 "PushButtonStatus_Neutral" ;
VAL_ 2365532224 BBContainerUnlockRequest 3 "OffOn_NotAvailable" 2 "OffOn_Error" 1 "OffOn_On" 0 "OffOn_Off" ;
VAL_ 2365532224 CabPlowLight_rqst 3 "Request_NotAvailable" 2 "Request_Error" 1 "Request_RequestActive" 0 "Request_NotRequested" ;
VAL_ 2365532224 AC_CompressorClutchCmd_ISig_4 3 "DisengageEngage_NotAvailable" 2 "DisengageEngage_Error" 1 "DisengageEngage_Engage" 0 "DisengageEngage_Disengage" ;
VAL_ 2365532224 AuxSwitchBbLoad4_Request 3 "OffOn_NotAvailable" 2 "OffOn_Error" 1 "OffOn_On" 0 "OffOn_Off" ;
VAL_ 2365532224 FogLightRear_ButtonStatus_1 3 "PushButtonStatus_NotAvailable" 2 "PushButtonStatus_Error" 1 "PushButtonStatus_Pushed" 0 "PushButtonStatus_Neutral" ;
VAL_ 2365532224 CabRoofSignOrVegaLight_rqst 3 "Request_NotAvailable" 2 "Request_Error" 1 "Request_RequestActive" 0 "Request_NotRequested" ;
VAL_ 2365532224 FogLightFront_ButtonStatus_2 3 "PushButtonStatus_NotAvailable" 2 "PushButtonStatus_Error" 1 "PushButtonStatus_Pushed" 0 "PushButtonStatus_Neutral" ;
VAL_ 2365532224 AuxSwitchBbLoad1_Request 3 "OffOn_NotAvailable" 2 "OffOn_Error" 1 "OffOn_On" 0 "OffOn_Off" ;
VAL_ 2365532224 BBCraneRequest 3 "OffOn_NotAvailable" 2 "OffOn_Error" 1 "OffOn_On" 0 "OffOn_Off" ;
VAL_ 2365532224 AuxSwitchBbLoad6_Request 3 "OffOn_NotAvailable" 2 "OffOn_Error" 1 "OffOn_On" 0 "OffOn_Off" ;
VAL_ 2365532224 AuxSwitchBbLoad5_Request 3 "OffOn_NotAvailable" 2 "OffOn_Error" 1 "OffOn_On" 0 "OffOn_Off" ;
VAL_ 2365532224 BodyOrCabWorkingLight_rqst 3 "Request_NotAvailable" 2 "Request_Error" 1 "Request_RequestActive" 0 "Request_NotRequested" ;
VAL_ 2365532224 CabFrontSpot_rqst 3 "Request_NotAvailable" 2 "Request_Error" 1 "Request_RequestActive" 0 "Request_NotRequested" ;
VAL_ 2365532224 CabTrailerBodyLighting_rqst 3 "Request_NotAvailable" 2 "Request_Error" 1 "Request_RequestActive" 0 "Request_NotRequested" ;
VAL_ 2365532224 CabWorkingLightChassis_rqst 3 "Request_NotAvailable" 2 "Request_Error" 1 "Request_RequestActive" 0 "Request_NotRequested" ;
VAL_ 2365532224 BBTailLiftRequest 3 "OffOn_NotAvailable" 2 "OffOn_Error" 1 "OffOn_On" 0 "OffOn_Off" ;
VAL_ 2365532224 BBSlidable5thWheelRequest 3 "OffOn_NotAvailable" 2 "OffOn_Error" 1 "OffOn_On" 0 "OffOn_Off" ;
VAL_ 2365532224 ACmode_IndicationCmd_ISig_4 1 "IndicationCmd_ONLEDActivated" 0 "IndicationCmd_OFFLEDNotActivated" ;
VAL_ 2365532224 CabExtraSideWorkingLight_rqst 7 "CabExtraSideWorkingLight_rqst_NotAvailable" 6 "CabExtraSideWorkingLight_rqst_Error" 5 "CabExtraSideWorkingLight_rqst_SpareValue_02" 4 "CabExtraSideWorkingLight_rqst_SpareValue_01" 3 "CabExtraSideWorkingLight_rqst_SpareValue" 2 "CabExtraSideWorkingLight_rqst_ReverseModeRequestedCab" 1 "CabExtraSideWorkingLight_rqst_WorkingModeRequestedCab" 0 "CabExtraSideWorkingLight_rqst_ExtraSideWorkingLightNotRqstdCab" ;
VAL_ 2365532224 FogLightFront_ButtonStatus_1 3 "PushButtonStatus_NotAvailable" 2 "PushButtonStatus_Error" 1 "PushButtonStatus_Pushed" 0 "PushButtonStatus_Neutral" ;
VAL_ 2365532224 AuxSwitchBbLoad2_Request 3 "OffOn_NotAvailable" 2 "OffOn_Error" 1 "OffOn_On" 0 "OffOn_Off" ;
VAL_ 2365532224 DRL_ButtonStatus 3 "PushButtonStatus_NotAvailable" 2 "PushButtonStatus_Error" 1 "PushButtonStatus_Pushed" 0 "PushButtonStatus_Neutral" ;
VAL_ 2365532224 CabRoofSpot_rqst 3 "Request_NotAvailable" 2 "Request_Error" 1 "Request_RequestActive" 0 "Request_NotRequested" ;
VAL_ 2365532224 LightMode_Status_Ctr_2 15 "Freewheel_Status_Ctr_NotAvailable" 14 "Freewheel_Status_Ctr_Error" 13 "Freewheel_Status_Ctr_Position13" 12 "Freewheel_Status_Ctr_Position12" 11 "Freewheel_Status_Ctr_Position11" 10 "Freewheel_Status_Ctr_Position10" 9 "Freewheel_Status_Ctr_Position9" 8 "Freewheel_Status_Ctr_Position8" 7 "Freewheel_Status_Ctr_Position7" 6 "Freewheel_Status_Ctr_Position6" 5 "Freewheel_Status_Ctr_Position5" 4 "Freewheel_Status_Ctr_Position4" 3 "Freewheel_Status_Ctr_Position3" 2 "Freewheel_Status_Ctr_Position2" 1 "Freewheel_Status_Ctr_Position1" 0 "Freewheel_Status_Ctr_NoMovement" ;
VAL_ 2365532224 CabBeaconLight_rqst 3 "Request_NotAvailable" 2 "Request_Error" 1 "Request_RequestActive" 0 "Request_NotRequested" ;
VAL_ 2365532224 AuxSwitchBbLoad3_Request 3 "OffOn_NotAvailable" 2 "OffOn_Error" 1 "OffOn_On" 0 "OffOn_Off" ;
VAL_ 2365532224 FogLightRear_ButtonStatus_2 3 "PushButtonStatus_NotAvailable" 2 "PushButtonStatus_Error" 1 "PushButtonStatus_Pushed" 0 "PushButtonStatus_Neutral" ;
VAL_ 2365532224 LightMode_Status_Ctr_1 15 "Freewheel_Status_Ctr_NotAvailable" 14 "Freewheel_Status_Ctr_Error" 13 "Freewheel_Status_Ctr_Position13" 12 "Freewheel_Status_Ctr_Position12" 11 "Freewheel_Status_Ctr_Position11" 10 "Freewheel_Status_Ctr_Position10" 9 "Freewheel_Status_Ctr_Position9" 8 "Freewheel_Status_Ctr_Position8" 7 "Freewheel_Status_Ctr_Position7" 6 "Freewheel_Status_Ctr_Position6" 5 "Freewheel_Status_Ctr_Position5" 4 "Freewheel_Status_Ctr_Position4" 3 "Freewheel_Status_Ctr_Position3" 2 "Freewheel_Status_Ctr_Position2" 1 "Freewheel_Status_Ctr_Position1" 0 "Freewheel_Status_Ctr_NoMovement" ;
VAL_ 2365532224 MirrorHeat_rqst 7 "MirrorHeat_NotAvailable" 6 "MirrorHeat_ErrorIndicator" 5 "MirrorHeat_SpareValue_02" 4 "MirrorHeat_SpareValue_01" 3 "MirrorHeat_SpareValue" 2 "MirrorHeat_ONExtendedMode" 1 "MirrorHeat_ONNormalMode" 0 "MirrorHeat_OFF" ;
VAL_ 2432643136 LevelRequest_RollRequest_ISig_4 7 "RollRequest_NotAvailable" 6 "RollRequest_Error" 5 "RollRequest_Reserved" 4 "RollRequest_CounterClockwiseShort" 3 "RollRequest_ClockwiseShort" 2 "RollRequest_CounterClockwise" 1 "RollRequest_Clockwise" 0 "RollRequest_Idle" ;
VAL_ 2432643136 FerryFunctionSwitchChangeReq_ISi 3 "ChangeRequest2Bit_NotAvailable" 2 "ChangeRequest2Bit_Error" 1 "ChangeRequest2Bit_Change" 0 "ChangeRequest2Bit_TakeNoAction" ;
VAL_ 2432643136 FerryFunctionRequest_ISig_4 3 "Request_NotAvailable" 2 "Request_Error" 1 "Request_RequestActive" 0 "Request_NotRequested" ;
VAL_ 2432643136 LevelRequest_FrontAxle_ISig_4 7 "LevelChangeRequest_NotAvailable" 6 "LevelChangeRequest_ErrorIndicator" 5 "LevelChangeRequest_NotDefined" 4 "LevelChangeRequest_VehicleBodyDownMinimumMovementLowering" 3 "LevelChangeRequest_VehicleBodyUpMinimumMovementLifting" 2 "LevelChangeRequest_VehicleBodyDownLowering" 1 "LevelChangeRequest_VehicleBodyUpLifting" 0 "LevelChangeRequest_TakeNoAction" ;
VAL_ 2432643136 KneelingChangeRequest_ISig_4 3 "KneelingChangeRequest_NotAvailable" 2 "KneelingChangeRequest_Error" 1 "KneelingChangeRequest_ChangeKneelFunction" 0 "KneelingChangeRequest_TakeNoAction" ;
VAL_ 2432643136 BunkH1AudioSrcSem_rqst_ISig_4 15 "AudioSource_NotAvailable" 14 "AudioSource_Error" 13 "AudioSource_Source13" 12 "AudioSource_Source12" 11 "AudioSource_Source11" 10 "AudioSource_Source10" 9 "AudioSource_Source09" 8 "AudioSource_Source08" 7 "AudioSource_Source07" 6 "AudioSource_Source06" 5 "AudioSource_Source05" 4 "AudioSource_Source04" 3 "AudioSource_Source03" 2 "AudioSource_Source02" 1 "AudioSource_Source01" 0 "AudioSource_Source00" ;
VAL_ 2432643136 ECSStandByRequest_ISig_4 7 "ECSStandByRequest_NotAvailable" 6 "ECSStandByRequest_Error" 5 "ECSStandByRequest_Reserved_01" 4 "ECSStandByRequest_Reserved" 3 "ECSStandByRequest_StandbyRequestedWRC" 2 "ECSStandByRequest_StandbyRequestedRCECS" 1 "ECSStandByRequest_Initiate" 0 "ECSStandByRequest_NoRequest" ;
VAL_ 2432643136 LevelStrokeRequest_ISig_4 3 "LevelStrokeRequest_NotAvailable" 2 "LevelStrokeRequest_ErrorIndicator" 1 "LevelStrokeRequest_DriveLevelControlStroke" 0 "LevelStrokeRequest_DockingLevelControlStroke" ;
VAL_ 2432643136 RideHeightStorageRequest_ISig_4 15 "RideHeightStorageRequest_NotAvailable" 14 "RideHeightStorageRequest_ErrorIndicator" 13 "RideHeightStorageRequest_NotDefined_06" 12 "RideHeightStorageRequest_NotDefined_05" 11 "RideHeightStorageRequest_NotDefined_04" 10 "RideHeightStorageRequest_NotDefined_03" 9 "RideHeightStorageRequest_NotDefined_02" 8 "RideHeightStorageRequest_NotDefined_01" 7 "RideHeightStorageRequest_NotDefined" 6 "RideHeightStorageRequest_ResetHighDrivePosition" 5 "RideHeightStorageRequest_ResetLowDrivePosition" 4 "RideHeightStorageRequest_StoreHighDrivePosition" 3 "RideHeightStorageRequest_StoreLowDrivePosition" 2 "RideHeightStorageRequest_StoreStandardUserDrivePosition" 1 "RideHeightStorageRequest_ResetToStoreFactoryDrivePosition" 0 "RideHeightStorageRequest_TakeNoAction" ;
VAL_ 2432643136 RampLevelRequest_ISig_4 15 "RampLevelRequest_NotAvailable" 14 "RampLevelRequest_ErrorIndicator" 13 "RampLevelRequest_NotDefined_09" 12 "RampLevelRequest_NotDefined_08" 11 "RampLevelRequest_NotDefined_07" 10 "RampLevelRequest_NotDefined_06" 9 "RampLevelRequest_NotDefined_05" 8 "RampLevelRequest_NotDefined_04" 7 "RampLevelRequest_RampLevelM7" 6 "RampLevelRequest_RampLevelM6" 5 "RampLevelRequest_RampLevelM5" 4 "RampLevelRequest_RampLevelM4" 3 "RampLevelRequest_RampLevelM3" 2 "RampLevelRequest_RampLevelM2" 1 "RampLevelRequest_RampLevelM1" 0 "RampLevelRequest_TakeNoAction" ;
VAL_ 2432643136 TCP_KnobPostionStatus 7 "TCPKnobPostionStatus_NotAvailable" 6 "TCPKnobPostionStatus_Error" 5 "TCPKnobPostionStatus_Spare1" 4 "TCPKnobPostionStatus_Pos4" 3 "TCPKnobPostionStatus_Pos3" 2 "TCPKnobPostionStatus_Pos2" 1 "TCPKnobPostionStatus_Pos1" 0 "TCPKnobPostionStatus_Pos0" ;
VAL_ 2432643136 SetFCWOperation 7 "SetFCWOperation_NotAvailable" 6 "SetFCWOperation_Error" 5 "SetFCWOperation_Spare3" 4 "SetFCWOperation_Spare2" 3 "SetFCWOperation_Spare1" 2 "SetFCWOperation_SetCollisionWarningOFF" 1 "SetFCWOperation_SetCollisionWarningON" 0 "SetFCWOperation_NoRequest" ;
VAL_ 2432643136 StopLevelChangeRequest_ISig_4 3 "Request_NotAvailable" 2 "Request_Error" 1 "Request_RequestActive" 0 "Request_NotRequested" ;
VAL_ 2432643136 RideHeightFunctionRequest_ISig_4 15 "RideHeightFunction_NotAvailable" 14 "RideHeightFunction_ErrorIndicator" 13 "RideHeightFunction_NotDefined_05" 12 "RideHeightFunction_NotDefined_04" 11 "RideHeightFunction_NotDefined_03" 10 "RideHeightFunction_NotDefined_02" 9 "RideHeightFunction_NotDefined_01" 8 "RideHeightFunction_NotDefined" 7 "RideHeightFunction_AlternativeDrivePosition2" 6 "RideHeightFunction_AlternativeDrivePosition1" 5 "RideHeightFunction_LowDrivePosition" 4 "RideHeightFunction_HighDrivePosition" 3 "RideHeightFunction_SpeedDependentDrivePosition" 2 "RideHeightFunction_AlternativeDrivePosition" 1 "RideHeightFunction_StandardDrivePosition" 0 "RideHeightFunction_Inactive" ;
VAL_ 2432643136 LevelRequest_RearAxle_ISig_4 7 "LevelChangeRequest_NotAvailable" 6 "LevelChangeRequest_ErrorIndicator" 5 "LevelChangeRequest_NotDefined" 4 "LevelChangeRequest_VehicleBodyDownMinimumMovementLowering" 3 "LevelChangeRequest_VehicleBodyUpMinimumMovementLifting" 2 "LevelChangeRequest_VehicleBodyDownLowering" 1 "LevelChangeRequest_VehicleBodyUpLifting" 0 "LevelChangeRequest_TakeNoAction" ;
VAL_ 2432643136 RampLevelStorageRequest_ISig_4 15 "RampLevelRequest_NotAvailable" 14 "RampLevelRequest_ErrorIndicator" 13 "RampLevelRequest_NotDefined_09" 12 "RampLevelRequest_NotDefined_08" 11 "RampLevelRequest_NotDefined_07" 10 "RampLevelRequest_NotDefined_06" 9 "RampLevelRequest_NotDefined_05" 8 "RampLevelRequest_NotDefined_04" 7 "RampLevelRequest_RampLevelM7" 6 "RampLevelRequest_RampLevelM6" 5 "RampLevelRequest_RampLevelM5" 4 "RampLevelRequest_RampLevelM4" 3 "RampLevelRequest_RampLevelM3" 2 "RampLevelRequest_RampLevelM2" 1 "RampLevelRequest_RampLevelM1" 0 "RampLevelRequest_TakeNoAction" ;
VAL_ 2432643136 SetCMOperation 7 "SetCMOperation_NotAvailable" 6 "SetCMOperation_Error" 5 "SetCMOperation_Spare3" 4 "SetCMOperation_Spare2" 3 "SetCMOperation_Spare1" 2 "SetCMOperation_SetEmergencyBrakeOFF" 1 "SetCMOperation_SetEmergencyBrakeON" 0 "SetCMOperation_NoRequest" ;
VAL_ 2432643136 BackToDriveReq_ISig_4 3 "Requested_NotAvailable" 2 "Requested_Error" 1 "BackToDriveReq_B2DRequested" 0 "BackToDriveReq_Idle" ;
VAL_ 2432640832 LockingIndication_rqst 7 "LockingIndication_rqst_NotAvailable" 6 "LockingIndication_rqst_Error" 5 "LockingIndication_rqst_Spare02" 4 "LockingIndication_rqst_Spare01" 3 "LockingIndication_rqst_Spare" 2 "LockingIndication_rqst_Unlock" 1 "LockingIndication_rqst_Lock" 0 "LockingIndication_rqst_Idle" ;
VAL_ 2432640832 KeyfobLockBtn_DoublePress_ISig_4 3 "NotDetected_NotAvaliable" 2 "NotDetected_Error" 1 "NotDetected_Detected" 0 "NotDetected_NotDetected" ;
VAL_ 2432640832 MainSwitchButton_Status_ISig_4 3 "PushButtonStatus_NotAvailable" 2 "PushButtonStatus_Error" 1 "PushButtonStatus_Pushed" 0 "PushButtonStatus_Neutral" ;
VAL_ 2432640832 CityHorn_cmd_ISig_4 3 "OffOn_NotAvailable" 2 "OffOn_Error" 1 "OffOn_On" 0 "OffOn_Off" ;
VAL_ 2432640832 KeyfobUnlockButton_Status 3 "PushButtonStatus_NotAvailable" 2 "PushButtonStatus_Error" 1 "PushButtonStatus_Pushed" 0 "PushButtonStatus_Neutral" ;
VAL_ 2432640832 BrakeBlendingButtonStatus 3 "PushButtonStatus_NotAvailable" 2 "PushButtonStatus_Error" 1 "PushButtonStatus_Pushed" 0 "PushButtonStatus_Neutral" ;
VAL_ 2432640832 KeyNotValid 7 "KeyNotValid_NotAvailable" 6 "KeyNotValid_Error" 1 "KeyNotValid_KeyNotValid" 0 "KeyNotValid_Idle" ;
VAL_ 2432640832 ExtraMainbeam_SwitchStatus 3 "A2PosSwitchStatus_NotAvailable" 2 "A2PosSwitchStatus_Error" 1 "A2PosSwitchStatus_On" 0 "A2PosSwitchStatus_Off" ;
VAL_ 2432640832 AuxiliaryHorn_cmd_ISig_4 3 "OffOn_NotAvailable" 2 "OffOn_Error" 1 "OffOn_On" 0 "OffOn_Off" ;
VAL_ 2432640832 ReverseWarning_rqst_ISig_4 3 "ReverseWarning_rqst_NotAvailable" 2 "ReverseWarning_rqst_Error" 1 "ReverseWarning_rqst_SoundOn" 0 "ReverseWarning_rqst_SoundOff" ;
VAL_ 2432640832 BackLightDimming_Status 31 "Thumbwheel_stat_NotAvaliable" 30 "Thumbwheel_stat_Error" 29 "Thumbwheel_stat_Spare_12" 28 "Thumbwheel_stat_Spare_11" 27 "Thumbwheel_stat_Spare_10" 26 "Thumbwheel_stat_Spare_09" 25 "Thumbwheel_stat_Spare_08" 24 "Thumbwheel_stat_Spare_07" 23 "Thumbwheel_stat_Spare_06" 22 "Thumbwheel_stat_Spare_05" 21 "Thumbwheel_stat_Spare_04" 20 "Thumbwheel_stat_Spare_03" 19 "Thumbwheel_stat_Spare_02" 18 "Thumbwheel_stat_Spare_01" 17 "Thumbwheel_stat_Spare" 16 "Thumbwheel_stat_ThumbWheelPos16" 15 "Thumbwheel_stat_ThumbWheelPos15" 14 "Thumbwheel_stat_ThumbWheelPos14" 13 "Thumbwheel_stat_ThumbWheelPos13" 12 "Thumbwheel_stat_ThumbWheelPos12" 11 "Thumbwheel_stat_ThumbWheelPos11" 10 "Thumbwheel_stat_ThumbWheelPos10" 9 "Thumbwheel_stat_ThumbWheelPos9" 8 "Thumbwheel_stat_ThumbWheelPos8" 7 "Thumbwheel_stat_ThumbWheelPos7" 6 "Thumbwheel_stat_ThumbWheelPos6" 5 "Thumbwheel_stat_ThumbWheelPos5" 4 "Thumbwheel_stat_ThumbWheelPos4" 3 "Thumbwheel_stat_ThumbWheelPos3" 2 "Thumbwheel_stat_ThumbWheelPos2" 1 "Thumbwheel_stat_ThumbWheelPos1" 0 "Thumbwheel_stat_ThumbWheelPos0" ;
VAL_ 2432640832 BlackPanelMode_ButtonStatus 3 "PushButtonStatus_NotAvailable" 2 "PushButtonStatus_Error" 1 "PushButtonStatus_Pushed" 0 "PushButtonStatus_Neutral" ;
VAL_ 2432661312 FWSelectedSpeedControlMode 7 "FWSelectedSpeedControlMode_NotAvailable" 6 "FWSelectedSpeedControlMode_Error" 5 "FWSelectedSpeedControlMode_Spare_02" 4 "FWSelectedSpeedControlMode_Spare_01" 3 "FWSelectedSpeedControlMode_AdaptiveCruiseControl" 2 "FWSelectedSpeedControlMode_AdjustableSpeedLimiter" 1 "FWSelectedSpeedControlMode_CruiseControl" 0 "FWSelectedSpeedControlMode_Off" ;
VAL_ 2432661312 FogLightFront_ButtonStatus_3 3 "PushButtonStatus_NotAvailable" 2 "PushButtonStatus_Error" 1 "PushButtonStatus_Pushed" 0 "PushButtonStatus_Neutral" ;
VAL_ 2432661312 InteriorLightDimming_rqst 31 "InteriorLightDimming_rqst_NotAvailable" 30 "InteriorLightDimming_rqst_Error" 15 "InteriorLightDimming_rqst_DimDownContinously" 14 "InteriorLightDimming_rqst_DimUpContinously" 13 "InteriorLightDimming_rqst_Position13" 12 "InteriorLightDimming_rqst_Position12" 11 "InteriorLightDimming_rqst_Position11" 10 "InteriorLightDimming_rqst_Position10" 9 "InteriorLightDimming_rqst_Position9" 8 "InteriorLightDimming_rqst_Position8" 7 "InteriorLightDimming_rqst_Position7" 6 "InteriorLightDimming_rqst_Position6" 5 "InteriorLightDimming_rqst_Position5" 4 "InteriorLightDimming_rqst_Position4" 3 "InteriorLightDimming_rqst_Position3" 2 "InteriorLightDimming_rqst_Position2" 1 "InteriorLightDimming_rqst_Position1" 0 "InteriorLightDimming_rqst_NoMovement" ;
VAL_ 2432661312 FrAxleDiffLockActvnDriverRqst_IS 3 "DisengageEngage_NotAvailable" 2 "DisengageEngage_Error" 1 "DisengageEngage_Engage" 0 "DisengageEngage_Disengage" ;
VAL_ 2432661312 AdjustFrontBeamInclination 7 "A3PosSwitchStatus_NotAvailable" 6 "A3PosSwitchStatus_Error" 5 "A3PosSwitchStatus_Spare_02" 4 "A3PosSwitchStatus_Spare_01" 3 "A3PosSwitchStatus_Spare" 2 "A3PosSwitchStatus_Upper" 1 "A3PosSwitchStatus_Lower" 0 "A3PosSwitchStatus_Middle" ;
VAL_ 2432661312 LiftAxle2AutoLiftRequest_ISig_4 3 "InactiveActive_NotAvailable" 2 "InactiveActive_Error" 1 "InactiveActive_Active" 0 "InactiveActive_Inactive" ;
VAL_ 2432661312 AltLoadDistribution_rqst_ISig_4 7 "AltLoadDistribution_rqst_NotAvailable" 6 "AltLoadDistribution_rqst_Error" 5 "AltLoadDistribution_rqst_Reserved_3" 4 "AltLoadDistribution_rqst_Reserved_2" 3 "AltLoadDistribution_rqst_Reserved_1" 2 "AltLoadDistribution_rqst_ALDOff" 1 "AltLoadDistribution_rqst_ALDOn" 0 "AltLoadDistribution_rqst_Idle" ;
VAL_ 2432661312 FogLightRear_ButtonStatus_3 3 "PushButtonStatus_NotAvailable" 2 "PushButtonStatus_Error" 1 "PushButtonStatus_Pushed" 0 "PushButtonStatus_Neutral" ;
VAL_ 2432661312 LiftAxle2LiftPositionRequest_ISi 7 "LiftAxleLiftPositionRequest_NotAvailable" 6 "LiftAxleLiftPositionRequest_Error" 5 "LiftAxleLiftPositionRequest_Reserved_02" 4 "LiftAxleLiftPositionRequest_Reserved_01" 3 "LiftAxleLiftPositionRequest_Reserved" 2 "LiftAxleLiftPositionRequest_Up" 1 "LiftAxleLiftPositionRequest_Down" 0 "LiftAxleLiftPositionRequest_Idle" ;
VAL_ 2432661312 TrailerBodyLamp_rqst 3 "PushButtonStatus_NotAvailable" 2 "PushButtonStatus_Error" 1 "PushButtonStatus_Pushed" 0 "PushButtonStatus_Neutral" ;
VAL_ 2432661312 LoadDistributionChangeRequest_IS 3 "LoadDistributionChangeRequest_NotAvailable" 2 "LoadDistributionChangeRequest_Error" 1 "LoadDistributionChangeRequest_ChangeLoadDistribution" 0 "LoadDistributionChangeRequest_Idle" ;
VAL_ 2432661312 LiftAxle1AutoLiftRequest_ISig_4 3 "InactiveActive_NotAvailable" 2 "InactiveActive_Error" 1 "InactiveActive_Active" 0 "InactiveActive_Inactive" ;
VAL_ 2432661312 LiftAxle1LiftPositionRequest_ISi 7 "LiftAxleLiftPositionRequest_NotAvailable" 6 "LiftAxleLiftPositionRequest_Error" 5 "LiftAxleLiftPositionRequest_Reserved_02" 4 "LiftAxleLiftPositionRequest_Reserved_01" 3 "LiftAxleLiftPositionRequest_Reserved" 2 "LiftAxleLiftPositionRequest_Up" 1 "LiftAxleLiftPositionRequest_Down" 0 "LiftAxleLiftPositionRequest_Idle" ;
VAL_ 1355 BBPeriodicLog1Status_ISig_4 3 "NotupdatedLog_NotAvailable" 2 "NotupdatedLog_Error" 1 "NotupdatedLog_UpdatedLog" 0 "NotupdatedLog_NotUpdated" ;
VAL_ 1355 BBPeriodicLog4Status_ISig_4 3 "NotupdatedLog_NotAvailable" 2 "NotupdatedLog_Error" 1 "NotupdatedLog_UpdatedLog" 0 "NotupdatedLog_NotUpdated" ;
VAL_ 1355 BBEventLog4Status_ISig_4 3 "NotupdatedLog_NotAvailable" 2 "NotupdatedLog_Error" 1 "NotupdatedLog_UpdatedLog" 0 "NotupdatedLog_NotUpdated" ;
VAL_ 1355 BBEventLog1Status_ISig_4 3 "NotupdatedLog_NotAvailable" 2 "NotupdatedLog_Error" 1 "NotupdatedLog_UpdatedLog" 0 "NotupdatedLog_NotUpdated" ;
VAL_ 1355 BBEventLog7Status_ISig_4 3 "NotupdatedLog_NotAvailable" 2 "NotupdatedLog_Error" 1 "NotupdatedLog_UpdatedLog" 0 "NotupdatedLog_NotUpdated" ;
VAL_ 1355 BBEventLog10Status_ISig_4 3 "NotupdatedLog_NotAvailable" 2 "NotupdatedLog_Error" 1 "NotupdatedLog_UpdatedLog" 0 "NotupdatedLog_NotUpdated" ;
VAL_ 1355 BBRollingBufferLogStatus_ISig_4 3 "NotupdatedLog_NotAvailable" 2 "NotupdatedLog_Error" 1 "NotupdatedLog_UpdatedLog" 0 "NotupdatedLog_NotUpdated" ;
VAL_ 1355 BBPeriodicLog2Status_ISig_4 3 "NotupdatedLog_NotAvailable" 2 "NotupdatedLog_Error" 1 "NotupdatedLog_UpdatedLog" 0 "NotupdatedLog_NotUpdated" ;
VAL_ 1355 BBEventLog6Status_ISig_4 3 "NotupdatedLog_NotAvailable" 2 "NotupdatedLog_Error" 1 "NotupdatedLog_UpdatedLog" 0 "NotupdatedLog_NotUpdated" ;
VAL_ 1355 BBEventLog9Status_ISig_4 3 "NotupdatedLog_NotAvailable" 2 "NotupdatedLog_Error" 1 "NotupdatedLog_UpdatedLog" 0 "NotupdatedLog_NotUpdated" ;
VAL_ 1355 BBFlexibleLoggingActive 3 "InactiveActive2_NotAvailableDontCare" 2 "InactiveActive2_Reserved" 1 "InactiveActive2_Active" 0 "InactiveActive2_Inactive" ;
VAL_ 1355 BBEventLog5Status_ISig_4 3 "NotupdatedLog_NotAvailable" 2 "NotupdatedLog_Error" 1 "NotupdatedLog_UpdatedLog" 0 "NotupdatedLog_NotUpdated" ;
VAL_ 1355 BBPeriodicLog3Status_ISig_4 3 "NotupdatedLog_NotAvailable" 2 "NotupdatedLog_Error" 1 "NotupdatedLog_UpdatedLog" 0 "NotupdatedLog_NotUpdated" ;
VAL_ 1355 BBEventLog3Status_ISig_4 3 "NotupdatedLog_NotAvailable" 2 "NotupdatedLog_Error" 1 "NotupdatedLog_UpdatedLog" 0 "NotupdatedLog_NotUpdated" ;
VAL_ 1355 BBEventLog2Status_ISig_4 3 "NotupdatedLog_NotAvailable" 2 "NotupdatedLog_Error" 1 "NotupdatedLog_UpdatedLog" 0 "NotupdatedLog_NotUpdated" ;
VAL_ 1355 BBEventLog8Status_ISig_4 3 "NotupdatedLog_NotAvailable" 2 "NotupdatedLog_Error" 1 "NotupdatedLog_UpdatedLog" 0 "NotupdatedLog_NotUpdated" ;
VAL_ 2365554662 RSBBM_BBSystemFASReqControlMode 7 "FASReqControlMode_NotAvailable" 6 "FASReqControlMode_Error" 5 "FASReqControlMode_Spare_03" 4 "FASReqControlMode_Spare_02" 3 "FASReqControlMode_Spare_01" 2 "FASReqControlMode_Curvature" 1 "FASReqControlMode_Angle" 0 "FASReqControlMode_Off" ;
VAL_ 955 FdDiagStatus4_ISig_4 3 "InactiveActiveSpare_NotAvailable" 2 "InactiveActiveSpare_Spare" 1 "InactiveActiveSpare_Active" 0 "InactiveActiveSpare_Inactive" ;
VAL_ 955 FdDiagStatus2_ISig_4 3 "InactiveActiveSpare_NotAvailable" 2 "InactiveActiveSpare_Spare" 1 "InactiveActiveSpare_Active" 0 "InactiveActiveSpare_Inactive" ;
VAL_ 955 FdDiagStatus8_ISig_4 3 "InactiveActiveSpare_NotAvailable" 2 "InactiveActiveSpare_Spare" 1 "InactiveActiveSpare_Active" 0 "InactiveActiveSpare_Inactive" ;
VAL_ 955 FdDiagStatus10_ISig_4 3 "InactiveActiveSpare_NotAvailable" 2 "InactiveActiveSpare_Spare" 1 "InactiveActiveSpare_Active" 0 "InactiveActiveSpare_Inactive" ;
VAL_ 955 FdDiagStatus6_ISig_4 3 "InactiveActiveSpare_NotAvailable" 2 "InactiveActiveSpare_Spare" 1 "InactiveActiveSpare_Active" 0 "InactiveActiveSpare_Inactive" ;
VAL_ 955 FdDiagStatus9_ISig_4 3 "InactiveActiveSpare_NotAvailable" 2 "InactiveActiveSpare_Spare" 1 "InactiveActiveSpare_Active" 0 "InactiveActiveSpare_Inactive" ;
VAL_ 955 FdDiagStatus5_ISig_4 3 "InactiveActiveSpare_NotAvailable" 2 "InactiveActiveSpare_Spare" 1 "InactiveActiveSpare_Active" 0 "InactiveActiveSpare_Inactive" ;
VAL_ 955 FdDiagStatus7_ISig_4 3 "InactiveActiveSpare_NotAvailable" 2 "InactiveActiveSpare_Spare" 1 "InactiveActiveSpare_Active" 0 "InactiveActiveSpare_Inactive" ;
VAL_ 955 FdDiagStatus1_ISig_4 3 "InactiveActiveSpare_NotAvailable" 2 "InactiveActiveSpare_Spare" 1 "InactiveActiveSpare_Active" 0 "InactiveActiveSpare_Inactive" ;
VAL_ 955 FdDiagStatus3_ISig_4 3 "InactiveActiveSpare_NotAvailable" 2 "InactiveActiveSpare_Spare" 1 "InactiveActiveSpare_Active" 0 "InactiveActiveSpare_Inactive" ;
VAL_ 2550057702 RFBEngineStopAllowed 3 "NotAllowedAllowed_NotAvailable" 2 "NotAllowedAllowed_Error" 1 "NotAllowedAllowed_Allowed" 0 "NotAllowedAllowed_NotAllowed" ;
VAL_ 2550057702 PreTSC1BsTr_EnOvrdCtrlM 3 "TSC1EngOverrideCtrlMode_SpeedTorqueLimitControl" 2 "TSC1EngOverrideCtrlMode_TorqueControl" 1 "TSC1EngOverrideCtrlMode_SpeedControl" 0 "TSC1EngOverrideCtrlMode_OverrideDisabled" ;
VAL_ 2550057702 BrakeAndPark_ind 7 "BrakeAndPark_ind_NotAvailable" 6 "BrakeAndPark_ind_Error" 5 "BrakeAndPark_ind_Spare3" 4 "BrakeAndPark_ind_Spare2" 3 "BrakeAndPark_ind_Spare1" 2 "BrakeAndPark_ind_ActiveAndVehicleParked" 1 "BrakeAndPark_ind_ActiveAndServiceBrakesRequested" 0 "BrakeAndPark_ind_Inactive" ;
VAL_ 2550057702 VehicleImmobilization_ind 3 "InactiveActive_NotAvailable" 2 "InactiveActive_Error" 1 "InactiveActive_Active" 0 "InactiveActive_Inactive" ;
VAL_ 2550057702 FullBrakes_ind_ISig_4 3 "InactiveActive_NotAvailable" 2 "InactiveActive_Error" 1 "InactiveActive_Active" 0 "InactiveActive_Inactive" ;
VAL_ 2550057702 PtoTorqueRequest 3 "PtoTorqueRequest_NotAvailable" 2 "PtoTorqueRequest_Error" 1 "PtoTorqueRequest_PtoIsRequestingHighTorque" 0 "PtoTorqueRequest_PtoIsNotRequestingHighTorque" ;
VAL_ 2481984998 TipperConditionsStatus_ISig_4 3 "NotFulfilledFulfilled_NotAvailable" 2 "NotFulfilledFulfilled_Error" 1 "NotFulfilledFulfilled_Fulfilled" 0 "NotFulfilledFulfilled_NotFulfilled" ;
VAL_ 2481984998 TailLiftRemoteNotAllowed_ISig_4 3 "NotAllowedAllowed_NotAvailable" 2 "NotAllowedAllowed_Error" 1 "NotAllowedAllowed_Allowed" 0 "NotAllowedAllowed_NotAllowed" ;
VAL_ 2481984998 TipperTarpaulinStatus_ISig_4 7 "TarpaulinStatus_NotAvailable" 6 "TarpaulinStatus_Error" 5 "TarpaulinStatus_Spare3" 4 "TarpaulinStatus_Spare2" 3 "TarpaulinStatus_Spare1" 2 "TarpaulinStatus_Uncovering" 1 "TarpaulinStatus_Covering" 0 "TarpaulinStatus_Inactive" ;
VAL_ 2481984998 TipperAutoLowering 3 "InactiveActive_NotAvailable" 2 "InactiveActive_Error" 1 "InactiveActive_Active" 0 "InactiveActive_Inactive" ;
VAL_ 2481984998 DirInd_Plough_Status 7 "DirIndFaultStatus_NotAvailable" 6 "DirIndFaultStatus_Error" 5 "DirIndFaultStatus_SpareValue_01" 4 "DirIndFaultStatus_SpareValue" 3 "DirIndFaultStatus_BothLeftAndRightDirectionIndicatorsFault" 2 "DirIndFaultStatus_RightDirectionIndicatorLampFault" 1 "DirIndFaultStatus_LeftDirectionIndicatorLampFault" 0 "DirIndFaultStatus_NoError" ;
VAL_ 2481984998 TipperShakerStatus_ISig_4 3 "ShakerStatus_NotAvailable" 2 "ShakerStatus_Error" 1 "ShakerStatus_Shaking" 0 "ShakerStatus_Inactive" ;
VAL_ 2481984998 TipperEmergencyStopStatus_ISig_4 7 "TipperEmergencyStopStatus_NotAvailable" 6 "TipperEmergencyStopStatus_Error" 5 "TipperEmergencyStopStatus_Spare2" 4 "TipperEmergencyStopStatus_Spare1" 3 "TipperEmergencyStopStatus_RemoteAndChassis" 2 "TipperEmergencyStopStatus_ChassisOnly" 1 "TipperEmergencyStopStatus_RemoteOnly" 0 "TipperEmergencyStopStatus_None" ;
VAL_ 2481984998 TipperSecondaryBodyStatus_ISig_4 7 "TipperBodyStatus_NotAvailable" 6 "TipperBodyStatus_Error" 5 "TipperBodyStatus_Spare3" 4 "TipperBodyStatus_Spare2" 3 "TipperBodyStatus_Spare1" 2 "TipperBodyStatus_NotPresent" 1 "TipperBodyStatus_Unavailable" 0 "TipperBodyStatus_Available" ;
VAL_ 2481984998 TipperPrimaryBodyStatus_ISig_4 7 "TipperBodyStatus_NotAvailable" 6 "TipperBodyStatus_Error" 5 "TipperBodyStatus_Spare3" 4 "TipperBodyStatus_Spare2" 3 "TipperBodyStatus_Spare1" 2 "TipperBodyStatus_NotPresent" 1 "TipperBodyStatus_Unavailable" 0 "TipperBodyStatus_Available" ;
VAL_ 2481984998 AuxSwitchBbLoad5Feedback 7 "BBDigitalOutputsFeedback_NotAvailable" 6 "BBDigitalOutputsFeedback_Error" 5 "BBDigitalOutputsFeedback_Spare_2" 4 "BBDigitalOutputsFeedback_Spare_1" 3 "BBDigitalOutputsFeedback_OpenCircuit" 2 "BBDigitalOutputsFeedback_ShortCircuitToBattery" 1 "BBDigitalOutputsFeedback_ShortCircuitToGround" 0 "BBDigitalOutputsFeedback_NoError" ;
VAL_ 2481984998 AuxSwitchBbLoad3Feedback 7 "BBDigitalOutputsFeedback_NotAvailable" 6 "BBDigitalOutputsFeedback_Error" 5 "BBDigitalOutputsFeedback_Spare_2" 4 "BBDigitalOutputsFeedback_Spare_1" 3 "BBDigitalOutputsFeedback_OpenCircuit" 2 "BBDigitalOutputsFeedback_ShortCircuitToBattery" 1 "BBDigitalOutputsFeedback_ShortCircuitToGround" 0 "BBDigitalOutputsFeedback_NoError" ;
VAL_ 2481984998 TailLiftMotionStatus_ISig_4 7 "RqstTiltUpDown_NotAvailable" 6 "RqstTiltUpDown_Error" 5 "RqstTiltUpDown_Spare" 4 "RqstTiltUpDown_TiltDown" 3 "RqstTiltUpDown_TiltUp" 2 "RqstTiltUpDown_RequestDown" 1 "RqstTiltUpDown_RequestUp" 0 "RqstTiltUpDown_NoRequest" ;
VAL_ 2481984998 AuxSwitchBbLoad4Feedback 7 "BBDigitalOutputsFeedback_NotAvailable" 6 "BBDigitalOutputsFeedback_Error" 5 "BBDigitalOutputsFeedback_Spare_2" 4 "BBDigitalOutputsFeedback_Spare_1" 3 "BBDigitalOutputsFeedback_OpenCircuit" 2 "BBDigitalOutputsFeedback_ShortCircuitToBattery" 1 "BBDigitalOutputsFeedback_ShortCircuitToGround" 0 "BBDigitalOutputsFeedback_NoError" ;
VAL_ 2481984998 TipperUpDownStatus_ISig_4 7 "UpDownStatus_NotAvailable" 6 "UpDownStatus_Error" 5 "UpDownStatus_Spare2" 4 "UpDownStatus_Spare1" 3 "UpDownStatus_AutoLowering" 2 "UpDownStatus_Lowering" 1 "UpDownStatus_Raising" 0 "UpDownStatus_Inactive" ;
VAL_ 2481984998 TailLiftConditionsStatus_ISig_4 3 "NotFulfilledFulfilled_NotAvailable" 2 "NotFulfilledFulfilled_Error" 1 "NotFulfilledFulfilled_Fulfilled" 0 "NotFulfilledFulfilled_NotFulfilled" ;
VAL_ 2481984998 AuxSwitchBbLoad6Feedback 7 "BBDigitalOutputsFeedback_NotAvailable" 6 "BBDigitalOutputsFeedback_Error" 5 "BBDigitalOutputsFeedback_Spare_2" 4 "BBDigitalOutputsFeedback_Spare_1" 3 "BBDigitalOutputsFeedback_OpenCircuit" 2 "BBDigitalOutputsFeedback_ShortCircuitToBattery" 1 "BBDigitalOutputsFeedback_ShortCircuitToGround" 0 "BBDigitalOutputsFeedback_NoError" ;
VAL_ 2481984998 TipperTailGateStatus_ISig_4 7 "GateStatus_NotAvailable" 6 "GateStatus_Error" 5 "GateStatus_Spare3" 4 "GateStatus_Spare2" 3 "GateStatus_Spare1" 2 "GateStatus_Closing" 1 "GateStatus_Opening" 0 "GateStatus_Inactive" ;
VAL_ 2481984998 CTA_PBReleaseInhibit_rqst 3 "Request_NotAvailable" 2 "Request_Error" 1 "Request_RequestActive" 0 "Request_NotRequested" ;
VAL_ 2466201830 CtaGcReverseInhibit 3 "Inhibit_NotAvailable" 2 "Inhibit_Error" 1 "Inhibit_InhibitActive" 0 "Inhibit_NoInhibit" ;
VAL_ 2466201830 BBSystemProhibitControlRequest_I 3 "Request_NotAvailable" 2 "Request_Error" 1 "Request_RequestActive" 0 "Request_NotRequested" ;
VAL_ 2466201830 BBUSecondDriverInterfEnable_ISig 3 "OffOn_NotAvailable" 2 "OffOn_Error" 1 "OffOn_On" 0 "OffOn_Off" ;
VAL_ 2466201830 SecondDriverInterfEnableInput 3 "OffOn_NotAvailable" 2 "OffOn_Error" 1 "OffOn_On" 0 "OffOn_Off" ;
VAL_ 2466201830 CtaGcInhibitGearEngaged 3 "Inhibit_NotAvailable" 2 "Inhibit_Error" 1 "Inhibit_InhibitActive" 0 "Inhibit_NoInhibit" ;
VAL_ 2466201830 EscChassisEngineSpdMode4 3 "InactiveActive_NotAvailable" 2 "InactiveActive_Error" 1 "InactiveActive_Active" 0 "InactiveActive_Inactive" ;
VAL_ 2466201830 SecondaryAccelPedalQuality 3 "Quality_NotAvailable" 2 "Quality_Error" 1 "Quality_DowngradedMode" 0 "Quality_NormalMode" ;
VAL_ 2466201830 BBSystemKneelRequest_ISig_4 3 "Request_NotAvailable" 2 "Request_Error" 1 "Request_RequestActive" 0 "Request_NotRequested" ;
VAL_ 2466201830 BBSystemAlternatLoadDistribReq_I 3 "InactiveActive_NotAvailable" 2 "InactiveActive_Error" 1 "InactiveActive_Active" 0 "InactiveActive_Inactive" ;
VAL_ 2466201830 EscChassisEngineSpdMode3 3 "InactiveActive_NotAvailable" 2 "InactiveActive_Error" 1 "InactiveActive_Active" 0 "InactiveActive_Inactive" ;
VAL_ 2466201830 CtaGcSecondGearLeverPosition_ISi 7 "CtaGcSecondGearLeverPosition_NotAvailable" 6 "CtaGcSecondGearLeverPosition_Error" 5 "CtaGcSecondGearLeverPosition_Spar_02" 4 "CtaGcSecondGearLeverPosition_Spare_01" 3 "CtaGcSecondGearLeverPosition_Spare" 2 "CtaGcSecondGearLeverPosition_Reverse" 1 "CtaGcSecondGearLeverPosition_Forward" 0 "CtaGcSecondGearLeverPosition_Neutral" ;
VAL_ 2466201830 CtaGcAlternativeGearStarter 3 "Request_NotAvailable" 2 "Request_Error" 1 "Request_RequestActive" 0 "Request_NotRequested" ;
VAL_ 2466201830 EscChassisEngineSpdMode2 3 "InactiveActive_NotAvailable" 2 "InactiveActive_Error" 1 "InactiveActive_Active" 0 "InactiveActive_Inactive" ;
VAL_ 2466201830 SecondaryAccelPedalKickDown 3 "PassiveActive_NotAvailable" 2 "PassiveActive_Error" 1 "PassiveActive_Active" 0 "PassiveActive_Passive" ;
VAL_ 2466201830 SecondAcceleratorPedalStatus 3 "InactiveActive_NotAvailable" 2 "InactiveActive_Error" 1 "InactiveActive_Active" 0 "InactiveActive_Inactive" ;
VAL_ 2466201830 GCRemoteEsc_rqst 3 "Request_NotAvailable" 2 "Request_Error" 1 "Request_RequestActive" 0 "Request_NotRequested" ;
VAL_ 2466201830 EscChassisEngineSpdMode1 3 "InactiveActive_NotAvailable" 2 "InactiveActive_Error" 1 "InactiveActive_Active" 0 "InactiveActive_Inactive" ;
VAL_ 2466201830 BBSystemSpeedDepDriveLevelReq_IS 3 "BBSystemSpeedDepDriveLevelReq_NotAvailable" 2 "BBSystemSpeedDepDriveLevelReq_ErrorIndicator" 1 "BBSystemSpeedDepDriveLevelReq_SpeedDependentDrivePosition" 0 "BBSystemSpeedDepDriveLevelReq_TakeNoAction" ;
VAL_ 2466239718 RssRemoteStopEngine_rqst 3 "OffOn_NotAvailable" 2 "OffOn_Error" 1 "OffOn_On" 0 "OffOn_Off" ;
VAL_ 2466239718 RSL2requestStatus 3 "Request_NotAvailable" 2 "Request_Error" 1 "Request_RequestActive" 0 "Request_NotRequested" ;
VAL_ 2466239718 FdEquipmentStatus2_ISig_4 3 "InactiveActive_NotAvailable" 2 "InactiveActive_Error" 1 "InactiveActive_Active" 0 "InactiveActive_Inactive" ;
VAL_ 2466239718 RssRemoteStartEngine_rqst 3 "OffOn_NotAvailable" 2 "OffOn_Error" 1 "OffOn_On" 0 "OffOn_Off" ;
VAL_ 2466239718 BBNetwBeaconLight_stat 3 "PushButtonStatus_NotAvailable" 2 "PushButtonStatus_Error" 1 "PushButtonStatus_Pushed" 0 "PushButtonStatus_Neutral" ;
VAL_ 2466239718 Pto2RemoteRequest 3 "OffOn_NotAvailable" 2 "OffOn_Error" 1 "OffOn_On" 0 "OffOn_Off" ;
VAL_ 2466239718 Pto1RemoteRequest 3 "OffOn_NotAvailable" 2 "OffOn_Error" 1 "OffOn_On" 0 "OffOn_Off" ;
VAL_ 2466239718 Pto3RemoteRequest 3 "OffOn_NotAvailable" 2 "OffOn_Error" 1 "OffOn_On" 0 "OffOn_Off" ;
VAL_ 2466239718 BBHazardWarning_rqst 3 "NoChangeStatusChanged_NotAvailable" 2 "NoChangeStatusChanged_Error" 1 "NoChangeStatusChanged_StatusChanged" 0 "NoChangeStatusChanged_NoChange" ;
VAL_ 2466239718 FdEquipmentStatus5_ISig_4 3 "InactiveActive_NotAvailable" 2 "InactiveActive_Error" 1 "InactiveActive_Active" 0 "InactiveActive_Inactive" ;
VAL_ 2466239718 RssInhibitStartEngFromBB_rqst 3 "OffOn_NotAvailable" 2 "OffOn_Error" 1 "OffOn_On" 0 "OffOn_Off" ;
VAL_ 2466239718 BBNetwExtraSWrknLight_stat 7 "BBNetworkExtraSideWrknLights_NotAvailable" 6 "BBNetworkExtraSideWrknLights_Error" 5 "BBNetworkExtraSideWrknLights_Reserved_02" 4 "BBNetworkExtraSideWrknLights_Reserved_01" 3 "BBNetworkExtraSideWrknLights_Reserved" 2 "BBNetworkExtraSideWrknLights_TurnOffLightWorkingMode" 1 "BBNetworkExtraSideWrknLights_TurnOnLightWorkingMode" 0 "BBNetworkExtraSideWrknLights_KeepCurrentLightStatus" ;
VAL_ 2466239718 FdEquipmentStatus4_ISig_4 3 "InactiveActive_NotAvailable" 2 "InactiveActive_Error" 1 "InactiveActive_Active" 0 "InactiveActive_Inactive" ;
VAL_ 2466239718 FdEquipmentStatus3_ISig_4 3 "InactiveActive_NotAvailable" 2 "InactiveActive_Error" 1 "InactiveActive_Active" 0 "InactiveActive_Inactive" ;
VAL_ 2466239718 BBNetwWrknLightChassis_stat 3 "PushButtonStatus_NotAvailable" 2 "PushButtonStatus_Error" 1 "PushButtonStatus_Pushed" 0 "PushButtonStatus_Neutral" ;
VAL_ 2466239718 BBNetwBodyOrCabWrknLight_stat 3 "PushButtonStatus_NotAvailable" 2 "PushButtonStatus_Error" 1 "PushButtonStatus_Pushed" 0 "PushButtonStatus_Neutral" ;
VAL_ 2466239718 BBNetwTrailerBodyLighting_rqst 3 "PushButtonStatus_NotAvailable" 2 "PushButtonStatus_Error" 1 "PushButtonStatus_Pushed" 0 "PushButtonStatus_Neutral" ;
VAL_ 2466239718 Pto4RemoteRequest 3 "OffOn_NotAvailable" 2 "OffOn_Error" 1 "OffOn_On" 0 "OffOn_Off" ;
VAL_ 2466239718 Pto3FeedbackStatus 3 "OffOn_NotAvailable" 2 "OffOn_Error" 1 "OffOn_On" 0 "OffOn_Off" ;
VAL_ 2466217958 EscChassisActivationRequest 3 "InactiveActive_NotAvailable" 2 "InactiveActive_Error" 1 "InactiveActive_Active" 0 "InactiveActive_Inactive" ;
VAL_ 2466217958 PloughLampModeStatus_ISig_4 3 "InactiveActive_NotAvailable" 2 "InactiveActive_Error" 1 "InactiveActive_Active" 0 "InactiveActive_Inactive" ;
VAL_ 2466217958 CtaBB_Horn_rqst 3 "OffOn_NotAvailable" 2 "OffOn_Error" 1 "OffOn_On" 0 "OffOn_Off" ;
VAL_ 2466217958 EscChassisEngineSpdSelection 7 "EscChassisEngineSpdSelection_NotAvailable" 6 "EscChassisEngineSpdSelection_Error" 5 "EscChassisEngineSpdSelection_Spare_01" 4 "EscChassisEngineSpdSelection_Spare" 3 "EscChassisEngineSpdSelection_EngineSpeedSelection3" 2 "EscChassisEngineSpdSelection_EngineSpeedSelection2" 1 "EscChassisEngineSpdSelection_EngineSpeedSelection1" 0 "EscChassisEngineSpdSelection_EngineSpeedSelection0" ;
VAL_ 2466217958 EscChassisActionRequest 7 "EscActionRequest_NotAvailable" 6 "EscActionRequest_Error" 5 "EscActionRequest_Spare" 4 "EscActionRequest_Set" 3 "EscActionRequest_Decrease" 2 "EscActionRequest_Increase" 1 "EscActionRequest_Resume" 0 "EscActionRequest_NoRequest" ;
VAL_ 2466217958 EscChassisEnable 3 "DisableEnable_NotAvailable" 2 "DisableEnable_Error" 1 "DisableEnable_Enable" 0 "DisableEnable_Disable" ;
VAL_ 2466217958 CtaBs_VehicleImmobilizationCmd_I 3 "OffOn_NotAvailable" 2 "OffOn_Error" 1 "OffOn_On" 0 "OffOn_Off" ;
SIG_GROUP_ 2482973248 InteriorLightMode_rqst_sg 1 : InteriorLightMode_rqst_IL_Mode InteriorLightMode_rqst_EventFlag;
SIG_GROUP_ 2432643136 LevelRequest_sg_ISig_4 1 : LevelRequest_RollRequest_ISig_4 LevelRequest_FrontAxle_ISig_4 LevelRequest_RearAxle_ISig_4;
SIG_GROUP_ 2365554662 RSBBM_sg 1 : RSBBM_BBSystemChecksum RSBBM_BBSystemFASReqControlMode RSBBM_BBSystemCounter RSBBM_BBSystemFASAngleRequest;
SIG_GROUP_ 2550057702 PreTSC1BsTr_sg 1 : PreTSC1BsTr_EnOvrdCtrlM PreTSC1BsTr_EnRTrqTrqLm;
